VERSION ""

NS_ :

BS_:

BU_: IVT_Mod ECU Inverters

VAL_TABLE_ _B9_Voltage_Channels 3 "3 Channels" 0 "0 Channels" ;
VAL_TABLE_ _B9_Supply_Voltage 1 "12 / 24 V nominal supply voltage" ;
VAL_TABLE_ _B9_Current 2500 "2500 A" 1000 "1000 A" 500 "500 A" 300 "300 A" 100 "100 A" ;
VAL_TABLE_ _B9_Device_Type 2 "IVT-S" 1 "IVT-Mod" ;
VAL_TABLE_ VtDevice_Com 2 "CAN 2 - not terminated" 1 "CAN 1 - terminated" 0 "none" ;
VAL_TABLE_ VtDevice_TOI 3 "I" ;
VAL_TABLE_ VtResetErrorLogdata 7 "Reset error current implausible" 6 "Reset error Vref" 5 "Reset error Underflow ADC ch2" 4 "Reset error Overflow ADC ch2" 3 "Reset error Underflow ADC ch1" 2 "Reset error Overflow ADC ch1" 1 "Reset error ADC interrupt" 0 "Reset all measurement errors" ;
VAL_TABLE_ VtID_Result 0 "Vt_Result_inaktive" 8 "Vt_Result_Wh" 7 "Vt_Result_Ah" 6 "Vt_Result_W" 5 "Vt_Result_T" 4 "Vt_Result_U3" 3 "Vt_Result_U2" 2 "Vt_Result_U1" 1 "Vt_Result_I" ;
VAL_TABLE_ VtID_Cmd 54 "Set_THRESHOLD_neg" 53 "Set_THRESHOLD_pos" 32 "Set_MODE_Result_I" 16 "Set_CAN_ID_Result_I" 52 "Set_MODE" 51 "START_OC_TEST" 50 "STORE" 49 "TRIGGER" 48 "Reset_Err_Log" 39 "Set_MODE_Result_Wh" 38 "Set_MODE_Result_Ah" 37 "Set_MODE_Result_W" 23 "Set_CAN_ID_Result_Wh" 22 "Set_CAN_ID_Result_Ah" 21 "Set_CAN_ID_Result_W" 20 "Set_CAN_ID_Result_T" 35 "Set_MODE_Result_U3" 31 "Set_CAN_ID_Cmd" 29 "Set_CAN_ID_Response" 19 "Set_CAN_ID_Result_U3" 18 "Set_CAN_ID_Result_U2" 36 "Set_MODE_Result_T" 34 "Set_MODE_Result_U2" 33 "Set_MODE_Result_U1" 17 "Set_CAN_ID_Result_U1" ;
VAL_TABLE_ VtTriggerMode 2 "CYCLIC" 1 "TRIGGERED" 0 "DISABLED" ;
VAL_TABLE_ VtRunMode 1 "START" 0 "STOP" ;
VAL_TABLE_ VtID_Response 149 "ARTICLE_NUMBER" 148 "SERIAL NUMBER" 147 "SW_VERSION" 146 "DEVICE_ID" 145 "STATUS" 143 "CAN_ID" 142 "STORE_to_default" 134 "START_OC_TEST" 133 "Description for the value '0x85'" 132 "THRESHOLD" 131 "CONFIG" 130 "MODE" 129 "STORE" 128 "TRIGGER" ;

BO_ 3221225472 VECTOR__INDEPENDENT_SIG_MSG: 0 Vector__XXX
 SG_ _B1_Resp_Trigger_Mask : 0|16@0+ (1,0) [0|0] "" Vector__XXX
 SG_ _B9_Resp_Device_spare : 0|8@0+ (1,0) [0|0] "" Vector__XXX

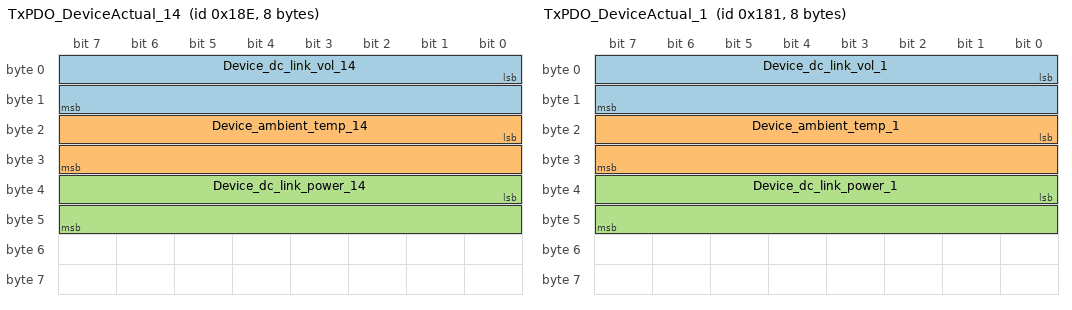
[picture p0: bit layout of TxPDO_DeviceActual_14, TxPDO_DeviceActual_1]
BO_ 398 TxPDO_DeviceActual_14: 8 Inverters
 SG_ Device_dc_link_vol_14 : 0|16@1- (0.0625,0) [-2048|2047.9375] "V" Vector__XXX
 SG_ Device_ambient_temp_14 : 16|16@1- (0.0625,0) [-2048|2047.9375] "°C" Vector__XXX
 SG_ Device_dc_link_power_14 : 32|16@1- (0.016,0) [-524.288|524.272] "kW" Vector__XXX

BO_ 385 TxPDO_DeviceActual_1: 8 Inverters
 SG_ Device_dc_link_vol_1 : 0|16@1- (0.0625,0) [-2048|2047.9375] "V" Vector__XXX
 SG_ Device_ambient_temp_1 : 16|16@1- (0.0625,0) [-2048|2047.9375] "°C" Vector__XXX
 SG_ Device_dc_link_power_1 : 32|16@1- (0.016,0) [-524.288|524.272] "kW" Vector__XXX

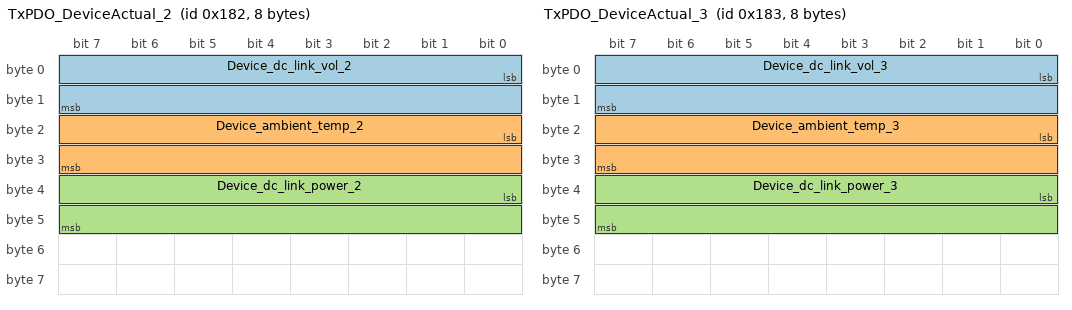
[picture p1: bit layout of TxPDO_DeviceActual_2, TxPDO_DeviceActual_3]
BO_ 386 TxPDO_DeviceActual_2: 8 Inverters
 SG_ Device_dc_link_vol_2 : 0|16@1- (0.0625,0) [-2048|2047.9375] "V" Vector__XXX
 SG_ Device_ambient_temp_2 : 16|16@1- (0.0625,0) [-2048|2047.9375] "°C" Vector__XXX
 SG_ Device_dc_link_power_2 : 32|16@1- (0.016,0) [-524.288|524.272] "kW" Vector__XXX

BO_ 387 TxPDO_DeviceActual_3: 8 Inverters
 SG_ Device_dc_link_vol_3 : 0|16@1- (0.0625,0) [-2048|2047.9375] "V" Vector__XXX
 SG_ Device_ambient_temp_3 : 16|16@1- (0.0625,0) [-2048|2047.9375] "°C" Vector__XXX
 SG_ Device_dc_link_power_3 : 32|16@1- (0.016,0) [-524.288|524.272] "kW" Vector__XXX

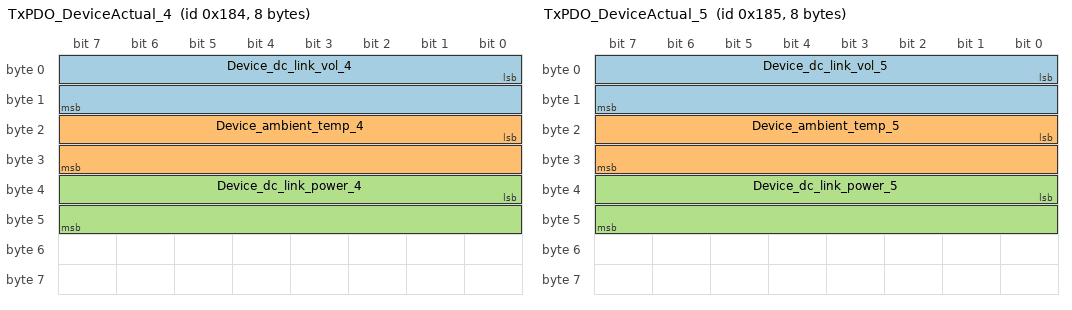
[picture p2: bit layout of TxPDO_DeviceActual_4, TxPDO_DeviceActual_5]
BO_ 388 TxPDO_DeviceActual_4: 8 Inverters
 SG_ Device_dc_link_vol_4 : 0|16@1- (0.0625,0) [-2048|2047.9375] "V" Vector__XXX
 SG_ Device_ambient_temp_4 : 16|16@1- (0.0625,0) [-2048|2047.9375] "°C" Vector__XXX
 SG_ Device_dc_link_power_4 : 32|16@1- (0.016,0) [-524.288|524.272] "kW" Vector__XXX

BO_ 389 TxPDO_DeviceActual_5: 8 Inverters
 SG_ Device_dc_link_vol_5 : 0|16@1- (0.0625,0) [-2048|2047.9375] "V" Vector__XXX
 SG_ Device_ambient_temp_5 : 16|16@1- (0.0625,0) [-2048|2047.9375] "°C" Vector__XXX
 SG_ Device_dc_link_power_5 : 32|16@1- (0.016,0) [-524.288|524.272] "kW" Vector__XXX

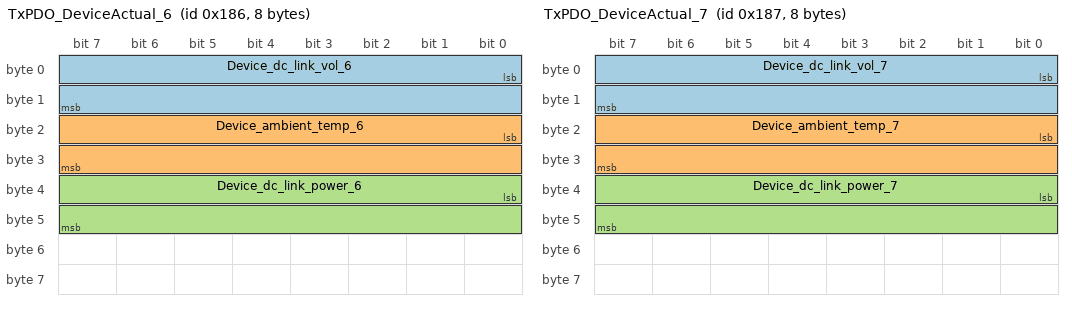
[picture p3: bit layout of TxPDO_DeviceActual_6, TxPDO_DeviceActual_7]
BO_ 390 TxPDO_DeviceActual_6: 8 Inverters
 SG_ Device_dc_link_vol_6 : 0|16@1- (0.0625,0) [-2048|2047.9375] "V" Vector__XXX
 SG_ Device_ambient_temp_6 : 16|16@1- (0.0625,0) [-2048|2047.9375] "°C" Vector__XXX
 SG_ Device_dc_link_power_6 : 32|16@1- (0.016,0) [-524.288|524.272] "kW" Vector__XXX

BO_ 391 TxPDO_DeviceActual_7: 8 Inverters
 SG_ Device_dc_link_vol_7 : 0|16@1- (0.0625,0) [-2048|2047.9375] "V" Vector__XXX
 SG_ Device_ambient_temp_7 : 16|16@1- (0.0625,0) [-2048|2047.9375] "°C" Vector__XXX
 SG_ Device_dc_link_power_7 : 32|16@1- (0.016,0) [-524.288|524.272] "kW" Vector__XXX

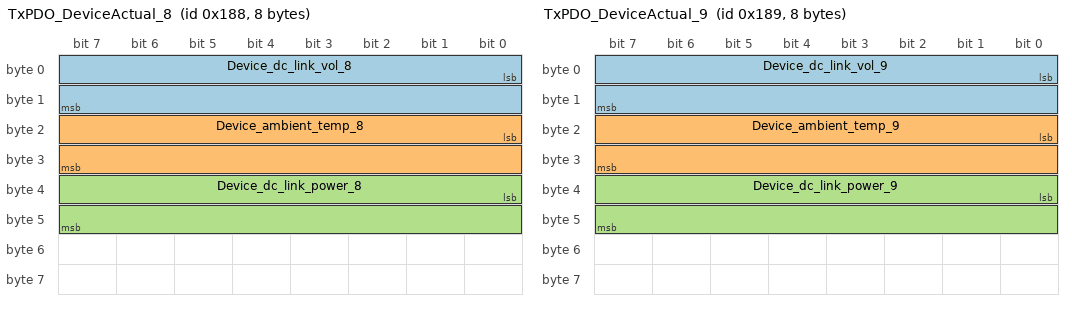
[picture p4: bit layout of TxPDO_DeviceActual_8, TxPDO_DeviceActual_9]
BO_ 392 TxPDO_DeviceActual_8: 8 Inverters
 SG_ Device_dc_link_vol_8 : 0|16@1- (0.0625,0) [-2048|2047.9375] "V" Vector__XXX
 SG_ Device_ambient_temp_8 : 16|16@1- (0.0625,0) [-2048|2047.9375] "°C" Vector__XXX
 SG_ Device_dc_link_power_8 : 32|16@1- (0.016,0) [-524.288|524.272] "kW" Vector__XXX

BO_ 393 TxPDO_DeviceActual_9: 8 Inverters
 SG_ Device_dc_link_vol_9 : 0|16@1- (0.0625,0) [-2048|2047.9375] "V" Vector__XXX
 SG_ Device_ambient_temp_9 : 16|16@1- (0.0625,0) [-2048|2047.9375] "°C" Vector__XXX
 SG_ Device_dc_link_power_9 : 32|16@1- (0.016,0) [-524.288|524.272] "kW" Vector__XXX

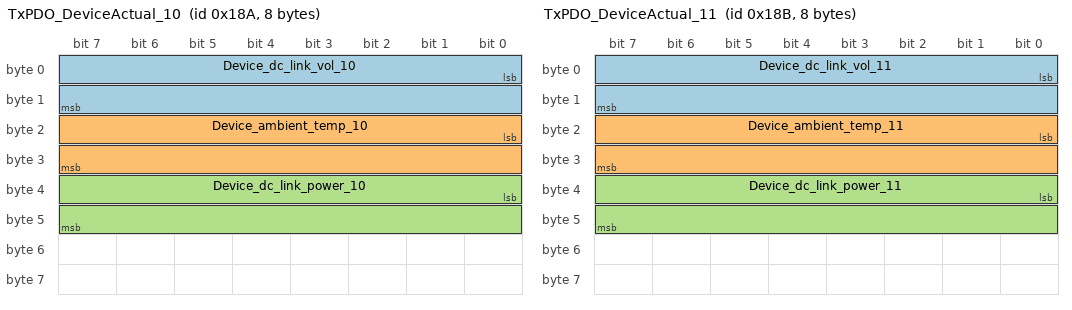
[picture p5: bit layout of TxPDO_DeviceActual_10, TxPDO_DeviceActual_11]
BO_ 394 TxPDO_DeviceActual_10: 8 Inverters
 SG_ Device_dc_link_vol_10 : 0|16@1- (0.0625,0) [-2048|2047.9375] "V" Vector__XXX
 SG_ Device_ambient_temp_10 : 16|16@1- (0.0625,0) [-2048|2047.9375] "°C" Vector__XXX
 SG_ Device_dc_link_power_10 : 32|16@1- (0.016,0) [-524.288|524.272] "kW" Vector__XXX

BO_ 395 TxPDO_DeviceActual_11: 8 Inverters
 SG_ Device_dc_link_vol_11 : 0|16@1- (0.0625,0) [-2048|2047.9375] "V" Vector__XXX
 SG_ Device_ambient_temp_11 : 16|16@1- (0.0625,0) [-2048|2047.9375] "°C" Vector__XXX
 SG_ Device_dc_link_power_11 : 32|16@1- (0.016,0) [-524.288|524.272] "kW" Vector__XXX

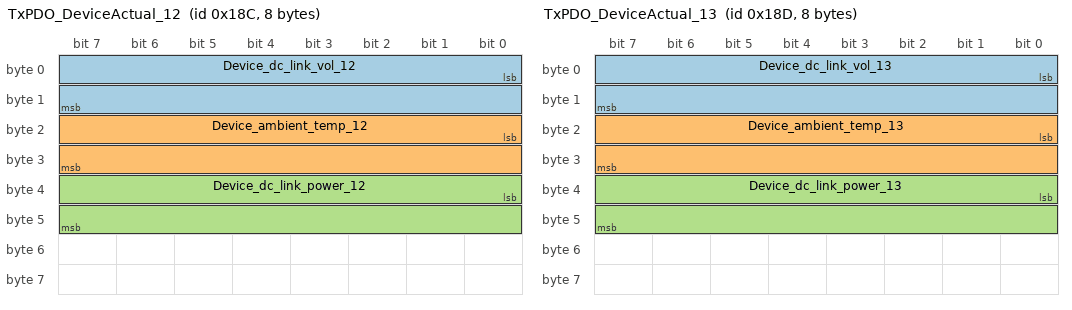
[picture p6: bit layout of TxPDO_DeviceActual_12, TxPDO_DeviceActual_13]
BO_ 396 TxPDO_DeviceActual_12: 8 Inverters
 SG_ Device_dc_link_vol_12 : 0|16@1- (0.0625,0) [-2048|2047.9375] "V" Vector__XXX
 SG_ Device_ambient_temp_12 : 16|16@1- (0.0625,0) [-2048|2047.9375] "°C" Vector__XXX
 SG_ Device_dc_link_power_12 : 32|16@1- (0.016,0) [-524.288|524.272] "kW" Vector__XXX

BO_ 397 TxPDO_DeviceActual_13: 8 Inverters
 SG_ Device_dc_link_vol_13 : 0|16@1- (0.0625,0) [-2048|2047.9375] "V" Vector__XXX
 SG_ Device_ambient_temp_13 : 16|16@1- (0.0625,0) [-2048|2047.9375] "°C" Vector__XXX
 SG_ Device_dc_link_power_13 : 32|16@1- (0.016,0) [-524.288|524.272] "kW" Vector__XXX

BO_ 462 TxPDO_InverterAStatus_14: 8 Inverters
 SG_ Inverter_A_Statusword_14 : 0|7@1+ (1,0) [0|127] "" Vector__XXX
 SG_ EVENTBUFFER_NEW_EVENT : 16|1@1+ (1,0) [0|1] "" Vector__XXX
 SG_ EVENTBUFFER_OVERFLOW : 17|1@1+ (1,0) [0|1] "" Vector__XXX
 SG_ POWERMODULE_TRIPZONE_OVERCURRE : 18|1@1+ (1,0) [0|1] "" Vector__XXX
 SG_ POWERMODULE_CURRENT_OFFSET_INI : 19|1@1+ (1,0) [0|1] "" Vector__XXX
 SG_ POWERMODULE_TEMPSENSOR_ERROR : 20|1@1+ (1,0) [0|1] "" Vector__XXX
 SG_ POWERMODULE_TEMPERATURE_WARNIN : 21|1@1+ (1,0) [0|1] "" Vector__XXX
 SG_ POWERMODULE_OVERTEMPERATURE : 22|1@1+ (1,0) [0|1] "" Vector__XXX
 SG_ POWERMODULE_IXT_FAULT : 23|1@1+ (1,0) [0|1] "" Vector__XXX
 SG_ POWERMODULE_SW_OVERCURRENT : 24|1@1+ (1,0) [0|1] "" Vector__XXX
 SG_ POWERMODULE_PATTERNDATA_INCONS : 25|1@1+ (1,0) [0|1] "" Vector__XXX
 SG_ DCBUS_TRIPZONE_OVERVOLTAGE : 26|1@1+ (1,0) [0|1] "" Vector__XXX
 SG_ DCBUS_SW_OVERVOLTAGE : 27|1@1+ (1,0) [0|1] "" Vector__XXX
 SG_ DCBUS_SW_UNDERVOLTAGE : 28|1@1+ (1,0) [0|1] "" Vector__XXX
 SG_ NEIGHBOUR_FAULT : 29|1@1+ (1,0) [0|1] "" Vector__XXX
 SG_ MOTOR_TEMPSENSOR_ERROR : 30|1@1+ (1,0) [0|1] "" Vector__XXX
 SG_ MOTOR_TEMPERATURE_WARNING : 31|1@1+ (1,0) [0|1] "" Vector__XXX
 SG_ MOTOR_OVERTEMPERATURE : 32|1@1+ (1,0) [0|1] "" Vector__XXX
 SG_ MOTOR_STATOR_FREQ_TO_HIGH : 33|1@1+ (1,0) [0|1] "" Vector__XXX
 SG_ SUPPLYVOLTAGE_ERROR : 34|1@1+ (1,0) [0|1] "" Vector__XXX
 SG_ RPDO_TIMEOUT : 35|1@1+ (1,0) [0|1] "" Vector__XXX
 SG_ NMT_NOT_OPERATIONAL : 36|1@1+ (1,0) [0|1] "" Vector__XXX
 SG_ TASKOVERRUN : 37|1@1+ (1,0) [0|1] "" Vector__XXX
 SG_ NETSYNC_ERROR : 38|1@1+ (1,0) [0|1] "" Vector__XXX
 SG_ POSDEVICE_SIGNAL_TO_LOW : 39|1@1+ (1,0) [0|1] "" Vector__XXX
 SG_ POSDEVICE_SIGNAL_TO_HIGH : 40|1@1+ (1,0) [0|1] "" Vector__XXX
 SG_ RESOLVER_CALIBRATION_FAILED : 41|1@1+ (1,0) [0|1] "" Vector__XXX
 SG_ SYSTEM_FAULT : 42|1@1+ (1,0) [0|1] "" Vector__XXX
 SG_ INTERLOCK_OPEN : 43|1@1+ (1,0) [0|1] "" Vector__XXX
 SG_ APPC_HAS_GATE_DRIVER_DISABLED : 44|1@1+ (1,0) [0|1] "" Vector__XXX
 SG_ MOTOR_STALL_ERROR : 45|1@1+ (1,0) [0|1] "" Vector__XXX
 SG_ AMBIENT_TEMPERATURE_WARNING : 46|1@1+ (1,0) [0|1] "" Vector__XXX
 SG_ AMBIENT_OVERTEMPERATURE : 47|1@1+ (1,0) [0|1] "" Vector__XXX
 SG_ AMBIENT_TEMPSENSOR_ERROR : 48|1@1+ (1,0) [0|1] "" Vector__XXX
 SG_ POWERMODULE_CLAMPING_TIMEOUT : 49|1@1+ (1,0) [0|1] "" Vector__XXX
 SG_ DCBUS_RIPPLE_TO_HIGH : 50|1@1+ (1,0) [0|1] "" Vector__XXX
 SG_ MOTOR_I2XT_WARNING : 51|1@1+ (1,0) [0|1] "" Vector__XXX
 SG_ MOTOR_I2XT_ERROR : 52|1@1+ (1,0) [0|1] "" Vector__XXX
 SG_ MOTOR_FIELDWEAKENING_ERROR : 53|1@1+ (1,0) [0|1] "" Vector__XXX
 SG_ INVALID_PARAMETER_COMBINATION : 54|1@1+ (1,0) [0|1] "" Vector__XXX
 SG_ PLUG_COVER_SENSOR_SIGNAL_LOW : 55|1@1+ (1,0) [0|1] "" Vector__XXX
 SG_ MOTOR_CONNECTION_TEST_FAILED : 56|1@1+ (1,0) [0|1] "" Vector__XXX
 SG_ POWERMODULE_IXT_WARNING : 57|1@1+ (1,0) [0|1] "" Vector__XXX
 SG_ ISOLATION_FAULT : 58|1@1+ (1,0) [0|1] "" Vector__XXX

BO_ 449 TxPDO_InverterAStatus_1: 8 Inverters
 SG_ Inverter_A_Statusword_1 : 0|7@1+ (1,0) [0|127] "" Vector__XXX
 SG_ EVENTBUFFER_NEW_EVENT : 16|1@1+ (1,0) [0|1] "" Vector__XXX
 SG_ EVENTBUFFER_OVERFLOW : 17|1@1+ (1,0) [0|1] "" Vector__XXX
 SG_ POWERMODULE_TRIPZONE_OVERCURRE : 18|1@1+ (1,0) [0|1] "" Vector__XXX
 SG_ POWERMODULE_CURRENT_OFFSET_INI : 19|1@1+ (1,0) [0|1] "" Vector__XXX
 SG_ POWERMODULE_TEMPSENSOR_ERROR : 20|1@1+ (1,0) [0|1] "" Vector__XXX
 SG_ POWERMODULE_TEMPERATURE_WARNIN : 21|1@1+ (1,0) [0|1] "" Vector__XXX
 SG_ POWERMODULE_OVERTEMPERATURE : 22|1@1+ (1,0) [0|1] "" Vector__XXX
 SG_ POWERMODULE_IXT_FAULT : 23|1@1+ (1,0) [0|1] "" Vector__XXX
 SG_ POWERMODULE_SW_OVERCURRENT : 24|1@1+ (1,0) [0|1] "" Vector__XXX
 SG_ POWERMODULE_PATTERNDATA_INCONS : 25|1@1+ (1,0) [0|1] "" Vector__XXX
 SG_ DCBUS_TRIPZONE_OVERVOLTAGE : 26|1@1+ (1,0) [0|1] "" Vector__XXX
 SG_ DCBUS_SW_OVERVOLTAGE : 27|1@1+ (1,0) [0|1] "" Vector__XXX
 SG_ DCBUS_SW_UNDERVOLTAGE : 28|1@1+ (1,0) [0|1] "" Vector__XXX
 SG_ NEIGHBOUR_FAULT : 29|1@1+ (1,0) [0|1] "" Vector__XXX
 SG_ MOTOR_TEMPSENSOR_ERROR : 30|1@1+ (1,0) [0|1] "" Vector__XXX
 SG_ MOTOR_TEMPERATURE_WARNING : 31|1@1+ (1,0) [0|1] "" Vector__XXX
 SG_ MOTOR_OVERTEMPERATURE : 32|1@1+ (1,0) [0|1] "" Vector__XXX
 SG_ MOTOR_STATOR_FREQ_TO_HIGH : 33|1@1+ (1,0) [0|1] "" Vector__XXX
 SG_ SUPPLYVOLTAGE_ERROR : 34|1@1+ (1,0) [0|1] "" Vector__XXX
 SG_ RPDO_TIMEOUT : 35|1@1+ (1,0) [0|1] "" Vector__XXX
 SG_ NMT_NOT_OPERATIONAL : 36|1@1+ (1,0) [0|1] "" Vector__XXX
 SG_ TASKOVERRUN : 37|1@1+ (1,0) [0|1] "" Vector__XXX
 SG_ NETSYNC_ERROR : 38|1@1+ (1,0) [0|1] "" Vector__XXX
 SG_ POSDEVICE_SIGNAL_TO_LOW : 39|1@1+ (1,0) [0|1] "" Vector__XXX
 SG_ POSDEVICE_SIGNAL_TO_HIGH : 40|1@1+ (1,0) [0|1] "" Vector__XXX
 SG_ RESOLVER_CALIBRATION_FAILED : 41|1@1+ (1,0) [0|1] "" Vector__XXX
 SG_ SYSTEM_FAULT : 42|1@1+ (1,0) [0|1] "" Vector__XXX
 SG_ INTERLOCK_OPEN : 43|1@1+ (1,0) [0|1] "" Vector__XXX
 SG_ APPC_HAS_GATE_DRIVER_DISABLED : 44|1@1+ (1,0) [0|1] "" Vector__XXX
 SG_ MOTOR_STALL_ERROR : 45|1@1+ (1,0) [0|1] "" Vector__XXX
 SG_ AMBIENT_TEMPERATURE_WARNING : 46|1@1+ (1,0) [0|1] "" Vector__XXX
 SG_ AMBIENT_OVERTEMPERATURE : 47|1@1+ (1,0) [0|1] "" Vector__XXX
 SG_ AMBIENT_TEMPSENSOR_ERROR : 48|1@1+ (1,0) [0|1] "" Vector__XXX
 SG_ POWERMODULE_CLAMPING_TIMEOUT : 49|1@1+ (1,0) [0|1] "" Vector__XXX
 SG_ DCBUS_RIPPLE_TO_HIGH : 50|1@1+ (1,0) [0|1] "" Vector__XXX
 SG_ MOTOR_I2XT_WARNING : 51|1@1+ (1,0) [0|1] "" Vector__XXX
 SG_ MOTOR_I2XT_ERROR : 52|1@1+ (1,0) [0|1] "" Vector__XXX
 SG_ MOTOR_FIELDWEAKENING_ERROR : 53|1@1+ (1,0) [0|1] "" Vector__XXX
 SG_ INVALID_PARAMETER_COMBINATION : 54|1@1+ (1,0) [0|1] "" Vector__XXX
 SG_ PLUG_COVER_SENSOR_SIGNAL_LOW : 55|1@1+ (1,0) [0|1] "" Vector__XXX
 SG_ MOTOR_CONNECTION_TEST_FAILED : 56|1@1+ (1,0) [0|1] "" Vector__XXX
 SG_ POWERMODULE_IXT_WARNING : 57|1@1+ (1,0) [0|1] "" Vector__XXX
 SG_ ISOLATION_FAULT : 58|1@1+ (1,0) [0|1] "" Vector__XXX

BO_ 450 TxPDO_InverterAStatus_2: 8 Inverters
 SG_ Inverter_A_Statusword_2 : 0|7@1+ (1,0) [0|127] "" Vector__XXX
 SG_ EVENTBUFFER_NEW_EVENT : 16|1@1+ (1,0) [0|1] "" Vector__XXX
 SG_ EVENTBUFFER_OVERFLOW : 17|1@1+ (1,0) [0|1] "" Vector__XXX
 SG_ POWERMODULE_TRIPZONE_OVERCURRE : 18|1@1+ (1,0) [0|1] "" Vector__XXX
 SG_ POWERMODULE_CURRENT_OFFSET_INI : 19|1@1+ (1,0) [0|1] "" Vector__XXX
 SG_ POWERMODULE_TEMPSENSOR_ERROR : 20|1@1+ (1,0) [0|1] "" Vector__XXX
 SG_ POWERMODULE_TEMPERATURE_WARNIN : 21|1@1+ (1,0) [0|1] "" Vector__XXX
 SG_ POWERMODULE_OVERTEMPERATURE : 22|1@1+ (1,0) [0|1] "" Vector__XXX
 SG_ POWERMODULE_IXT_FAULT : 23|1@1+ (1,0) [0|1] "" Vector__XXX
 SG_ POWERMODULE_SW_OVERCURRENT : 24|1@1+ (1,0) [0|1] "" Vector__XXX
 SG_ POWERMODULE_PATTERNDATA_INCONS : 25|1@1+ (1,0) [0|1] "" Vector__XXX
 SG_ DCBUS_TRIPZONE_OVERVOLTAGE : 26|1@1+ (1,0) [0|1] "" Vector__XXX
 SG_ DCBUS_SW_OVERVOLTAGE : 27|1@1+ (1,0) [0|1] "" Vector__XXX
 SG_ DCBUS_SW_UNDERVOLTAGE : 28|1@1+ (1,0) [0|1] "" Vector__XXX
 SG_ NEIGHBOUR_FAULT : 29|1@1+ (1,0) [0|1] "" Vector__XXX
 SG_ MOTOR_TEMPSENSOR_ERROR : 30|1@1+ (1,0) [0|1] "" Vector__XXX
 SG_ MOTOR_TEMPERATURE_WARNING : 31|1@1+ (1,0) [0|1] "" Vector__XXX
 SG_ MOTOR_OVERTEMPERATURE : 32|1@1+ (1,0) [0|1] "" Vector__XXX
 SG_ MOTOR_STATOR_FREQ_TO_HIGH : 33|1@1+ (1,0) [0|1] "" Vector__XXX
 SG_ SUPPLYVOLTAGE_ERROR : 34|1@1+ (1,0) [0|1] "" Vector__XXX
 SG_ RPDO_TIMEOUT : 35|1@1+ (1,0) [0|1] "" Vector__XXX
 SG_ NMT_NOT_OPERATIONAL : 36|1@1+ (1,0) [0|1] "" Vector__XXX
 SG_ TASKOVERRUN : 37|1@1+ (1,0) [0|1] "" Vector__XXX
 SG_ NETSYNC_ERROR : 38|1@1+ (1,0) [0|1] "" Vector__XXX
 SG_ POSDEVICE_SIGNAL_TO_LOW : 39|1@1+ (1,0) [0|1] "" Vector__XXX
 SG_ POSDEVICE_SIGNAL_TO_HIGH : 40|1@1+ (1,0) [0|1] "" Vector__XXX
 SG_ RESOLVER_CALIBRATION_FAILED : 41|1@1+ (1,0) [0|1] "" Vector__XXX
 SG_ SYSTEM_FAULT : 42|1@1+ (1,0) [0|1] "" Vector__XXX
 SG_ INTERLOCK_OPEN : 43|1@1+ (1,0) [0|1] "" Vector__XXX
 SG_ APPC_HAS_GATE_DRIVER_DISABLED : 44|1@1+ (1,0) [0|1] "" Vector__XXX
 SG_ MOTOR_STALL_ERROR : 45|1@1+ (1,0) [0|1] "" Vector__XXX
 SG_ AMBIENT_TEMPERATURE_WARNING : 46|1@1+ (1,0) [0|1] "" Vector__XXX
 SG_ AMBIENT_OVERTEMPERATURE : 47|1@1+ (1,0) [0|1] "" Vector__XXX
 SG_ AMBIENT_TEMPSENSOR_ERROR : 48|1@1+ (1,0) [0|1] "" Vector__XXX
 SG_ POWERMODULE_CLAMPING_TIMEOUT : 49|1@1+ (1,0) [0|1] "" Vector__XXX
 SG_ DCBUS_RIPPLE_TO_HIGH : 50|1@1+ (1,0) [0|1] "" Vector__XXX
 SG_ MOTOR_I2XT_WARNING : 51|1@1+ (1,0) [0|1] "" Vector__XXX
 SG_ MOTOR_I2XT_ERROR : 52|1@1+ (1,0) [0|1] "" Vector__XXX
 SG_ MOTOR_FIELDWEAKENING_ERROR : 53|1@1+ (1,0) [0|1] "" Vector__XXX
 SG_ INVALID_PARAMETER_COMBINATION : 54|1@1+ (1,0) [0|1] "" Vector__XXX
 SG_ PLUG_COVER_SENSOR_SIGNAL_LOW : 55|1@1+ (1,0) [0|1] "" Vector__XXX
 SG_ MOTOR_CONNECTION_TEST_FAILED : 56|1@1+ (1,0) [0|1] "" Vector__XXX
 SG_ POWERMODULE_IXT_WARNING : 57|1@1+ (1,0) [0|1] "" Vector__XXX
 SG_ ISOLATION_FAULT : 58|1@1+ (1,0) [0|1] "" Vector__XXX

BO_ 451 TxPDO_InverterAStatus_3: 8 Inverters
 SG_ Inverter_A_Statusword_3 : 0|7@1+ (1,0) [0|127] "" Vector__XXX
 SG_ EVENTBUFFER_NEW_EVENT : 16|1@1+ (1,0) [0|1] "" Vector__XXX
 SG_ EVENTBUFFER_OVERFLOW : 17|1@1+ (1,0) [0|1] "" Vector__XXX
 SG_ POWERMODULE_TRIPZONE_OVERCURRE : 18|1@1+ (1,0) [0|1] "" Vector__XXX
 SG_ POWERMODULE_CURRENT_OFFSET_INI : 19|1@1+ (1,0) [0|1] "" Vector__XXX
 SG_ POWERMODULE_TEMPSENSOR_ERROR : 20|1@1+ (1,0) [0|1] "" Vector__XXX
 SG_ POWERMODULE_TEMPERATURE_WARNIN : 21|1@1+ (1,0) [0|1] "" Vector__XXX
 SG_ POWERMODULE_OVERTEMPERATURE : 22|1@1+ (1,0) [0|1] "" Vector__XXX
 SG_ POWERMODULE_IXT_FAULT : 23|1@1+ (1,0) [0|1] "" Vector__XXX
 SG_ POWERMODULE_SW_OVERCURRENT : 24|1@1+ (1,0) [0|1] "" Vector__XXX
 SG_ POWERMODULE_PATTERNDATA_INCONS : 25|1@1+ (1,0) [0|1] "" Vector__XXX
 SG_ DCBUS_TRIPZONE_OVERVOLTAGE : 26|1@1+ (1,0) [0|1] "" Vector__XXX
 SG_ DCBUS_SW_OVERVOLTAGE : 27|1@1+ (1,0) [0|1] "" Vector__XXX
 SG_ DCBUS_SW_UNDERVOLTAGE : 28|1@1+ (1,0) [0|1] "" Vector__XXX
 SG_ NEIGHBOUR_FAULT : 29|1@1+ (1,0) [0|1] "" Vector__XXX
 SG_ MOTOR_TEMPSENSOR_ERROR : 30|1@1+ (1,0) [0|1] "" Vector__XXX
 SG_ MOTOR_TEMPERATURE_WARNING : 31|1@1+ (1,0) [0|1] "" Vector__XXX
 SG_ MOTOR_OVERTEMPERATURE : 32|1@1+ (1,0) [0|1] "" Vector__XXX
 SG_ MOTOR_STATOR_FREQ_TO_HIGH : 33|1@1+ (1,0) [0|1] "" Vector__XXX
 SG_ SUPPLYVOLTAGE_ERROR : 34|1@1+ (1,0) [0|1] "" Vector__XXX
 SG_ RPDO_TIMEOUT : 35|1@1+ (1,0) [0|1] "" Vector__XXX
 SG_ NMT_NOT_OPERATIONAL : 36|1@1+ (1,0) [0|1] "" Vector__XXX
 SG_ TASKOVERRUN : 37|1@1+ (1,0) [0|1] "" Vector__XXX
 SG_ NETSYNC_ERROR : 38|1@1+ (1,0) [0|1] "" Vector__XXX
 SG_ POSDEVICE_SIGNAL_TO_LOW : 39|1@1+ (1,0) [0|1] "" Vector__XXX
 SG_ POSDEVICE_SIGNAL_TO_HIGH : 40|1@1+ (1,0) [0|1] "" Vector__XXX
 SG_ RESOLVER_CALIBRATION_FAILED : 41|1@1+ (1,0) [0|1] "" Vector__XXX
 SG_ SYSTEM_FAULT : 42|1@1+ (1,0) [0|1] "" Vector__XXX
 SG_ INTERLOCK_OPEN : 43|1@1+ (1,0) [0|1] "" Vector__XXX
 SG_ APPC_HAS_GATE_DRIVER_DISABLED : 44|1@1+ (1,0) [0|1] "" Vector__XXX
 SG_ MOTOR_STALL_ERROR : 45|1@1+ (1,0) [0|1] "" Vector__XXX
 SG_ AMBIENT_TEMPERATURE_WARNING : 46|1@1+ (1,0) [0|1] "" Vector__XXX
 SG_ AMBIENT_OVERTEMPERATURE : 47|1@1+ (1,0) [0|1] "" Vector__XXX
 SG_ AMBIENT_TEMPSENSOR_ERROR : 48|1@1+ (1,0) [0|1] "" Vector__XXX
 SG_ POWERMODULE_CLAMPING_TIMEOUT : 49|1@1+ (1,0) [0|1] "" Vector__XXX
 SG_ DCBUS_RIPPLE_TO_HIGH : 50|1@1+ (1,0) [0|1] "" Vector__XXX
 SG_ MOTOR_I2XT_WARNING : 51|1@1+ (1,0) [0|1] "" Vector__XXX
 SG_ MOTOR_I2XT_ERROR : 52|1@1+ (1,0) [0|1] "" Vector__XXX
 SG_ MOTOR_FIELDWEAKENING_ERROR : 53|1@1+ (1,0) [0|1] "" Vector__XXX
 SG_ INVALID_PARAMETER_COMBINATION : 54|1@1+ (1,0) [0|1] "" Vector__XXX
 SG_ PLUG_COVER_SENSOR_SIGNAL_LOW : 55|1@1+ (1,0) [0|1] "" Vector__XXX
 SG_ MOTOR_CONNECTION_TEST_FAILED : 56|1@1+ (1,0) [0|1] "" Vector__XXX
 SG_ POWERMODULE_IXT_WARNING : 57|1@1+ (1,0) [0|1] "" Vector__XXX
 SG_ ISOLATION_FAULT : 58|1@1+ (1,0) [0|1] "" Vector__XXX

BO_ 452 TxPDO_InverterAStatus_4: 8 Inverters
 SG_ Inverter_A_Statusword_4 : 0|7@1+ (1,0) [0|127] "" Vector__XXX
 SG_ EVENTBUFFER_NEW_EVENT : 16|1@1+ (1,0) [0|1] "" Vector__XXX
 SG_ EVENTBUFFER_OVERFLOW : 17|1@1+ (1,0) [0|1] "" Vector__XXX
 SG_ POWERMODULE_TRIPZONE_OVERCURRE : 18|1@1+ (1,0) [0|1] "" Vector__XXX
 SG_ POWERMODULE_CURRENT_OFFSET_INI : 19|1@1+ (1,0) [0|1] "" Vector__XXX
 SG_ POWERMODULE_TEMPSENSOR_ERROR : 20|1@1+ (1,0) [0|1] "" Vector__XXX
 SG_ POWERMODULE_TEMPERATURE_WARNIN : 21|1@1+ (1,0) [0|1] "" Vector__XXX
 SG_ POWERMODULE_OVERTEMPERATURE : 22|1@1+ (1,0) [0|1] "" Vector__XXX
 SG_ POWERMODULE_IXT_FAULT : 23|1@1+ (1,0) [0|1] "" Vector__XXX
 SG_ POWERMODULE_SW_OVERCURRENT : 24|1@1+ (1,0) [0|1] "" Vector__XXX
 SG_ POWERMODULE_PATTERNDATA_INCONS : 25|1@1+ (1,0) [0|1] "" Vector__XXX
 SG_ DCBUS_TRIPZONE_OVERVOLTAGE : 26|1@1+ (1,0) [0|1] "" Vector__XXX
 SG_ DCBUS_SW_OVERVOLTAGE : 27|1@1+ (1,0) [0|1] "" Vector__XXX
 SG_ DCBUS_SW_UNDERVOLTAGE : 28|1@1+ (1,0) [0|1] "" Vector__XXX
 SG_ NEIGHBOUR_FAULT : 29|1@1+ (1,0) [0|1] "" Vector__XXX
 SG_ MOTOR_TEMPSENSOR_ERROR : 30|1@1+ (1,0) [0|1] "" Vector__XXX
 SG_ MOTOR_TEMPERATURE_WARNING : 31|1@1+ (1,0) [0|1] "" Vector__XXX
 SG_ MOTOR_OVERTEMPERATURE : 32|1@1+ (1,0) [0|1] "" Vector__XXX
 SG_ MOTOR_STATOR_FREQ_TO_HIGH : 33|1@1+ (1,0) [0|1] "" Vector__XXX
 SG_ SUPPLYVOLTAGE_ERROR : 34|1@1+ (1,0) [0|1] "" Vector__XXX
 SG_ RPDO_TIMEOUT : 35|1@1+ (1,0) [0|1] "" Vector__XXX
 SG_ NMT_NOT_OPERATIONAL : 36|1@1+ (1,0) [0|1] "" Vector__XXX
 SG_ TASKOVERRUN : 37|1@1+ (1,0) [0|1] "" Vector__XXX
 SG_ NETSYNC_ERROR : 38|1@1+ (1,0) [0|1] "" Vector__XXX
 SG_ POSDEVICE_SIGNAL_TO_LOW : 39|1@1+ (1,0) [0|1] "" Vector__XXX
 SG_ POSDEVICE_SIGNAL_TO_HIGH : 40|1@1+ (1,0) [0|1] "" Vector__XXX
 SG_ RESOLVER_CALIBRATION_FAILED : 41|1@1+ (1,0) [0|1] "" Vector__XXX
 SG_ SYSTEM_FAULT : 42|1@1+ (1,0) [0|1] "" Vector__XXX
 SG_ INTERLOCK_OPEN : 43|1@1+ (1,0) [0|1] "" Vector__XXX
 SG_ APPC_HAS_GATE_DRIVER_DISABLED : 44|1@1+ (1,0) [0|1] "" Vector__XXX
 SG_ MOTOR_STALL_ERROR : 45|1@1+ (1,0) [0|1] "" Vector__XXX
 SG_ AMBIENT_TEMPERATURE_WARNING : 46|1@1+ (1,0) [0|1] "" Vector__XXX
 SG_ AMBIENT_OVERTEMPERATURE : 47|1@1+ (1,0) [0|1] "" Vector__XXX
 SG_ AMBIENT_TEMPSENSOR_ERROR : 48|1@1+ (1,0) [0|1] "" Vector__XXX
 SG_ POWERMODULE_CLAMPING_TIMEOUT : 49|1@1+ (1,0) [0|1] "" Vector__XXX
 SG_ DCBUS_RIPPLE_TO_HIGH : 50|1@1+ (1,0) [0|1] "" Vector__XXX
 SG_ MOTOR_I2XT_WARNING : 51|1@1+ (1,0) [0|1] "" Vector__XXX
 SG_ MOTOR_I2XT_ERROR : 52|1@1+ (1,0) [0|1] "" Vector__XXX
 SG_ MOTOR_FIELDWEAKENING_ERROR : 53|1@1+ (1,0) [0|1] "" Vector__XXX
 SG_ INVALID_PARAMETER_COMBINATION : 54|1@1+ (1,0) [0|1] "" Vector__XXX
 SG_ PLUG_COVER_SENSOR_SIGNAL_LOW : 55|1@1+ (1,0) [0|1] "" Vector__XXX
 SG_ MOTOR_CONNECTION_TEST_FAILED : 56|1@1+ (1,0) [0|1] "" Vector__XXX
 SG_ POWERMODULE_IXT_WARNING : 57|1@1+ (1,0) [0|1] "" Vector__XXX
 SG_ ISOLATION_FAULT : 58|1@1+ (1,0) [0|1] "" Vector__XXX

BO_ 453 TxPDO_InverterAStatus_5: 8 Inverters
 SG_ Inverter_A_Statusword_5 : 0|7@1+ (1,0) [0|127] "" Vector__XXX
 SG_ EVENTBUFFER_NEW_EVENT : 16|1@1+ (1,0) [0|1] "" Vector__XXX
 SG_ EVENTBUFFER_OVERFLOW : 17|1@1+ (1,0) [0|1] "" Vector__XXX
 SG_ POWERMODULE_TRIPZONE_OVERCURRE : 18|1@1+ (1,0) [0|1] "" Vector__XXX
 SG_ POWERMODULE_CURRENT_OFFSET_INI : 19|1@1+ (1,0) [0|1] "" Vector__XXX
 SG_ POWERMODULE_TEMPSENSOR_ERROR : 20|1@1+ (1,0) [0|1] "" Vector__XXX
 SG_ POWERMODULE_TEMPERATURE_WARNIN : 21|1@1+ (1,0) [0|1] "" Vector__XXX
 SG_ POWERMODULE_OVERTEMPERATURE : 22|1@1+ (1,0) [0|1] "" Vector__XXX
 SG_ POWERMODULE_IXT_FAULT : 23|1@1+ (1,0) [0|1] "" Vector__XXX
 SG_ POWERMODULE_SW_OVERCURRENT : 24|1@1+ (1,0) [0|1] "" Vector__XXX
 SG_ POWERMODULE_PATTERNDATA_INCONS : 25|1@1+ (1,0) [0|1] "" Vector__XXX
 SG_ DCBUS_TRIPZONE_OVERVOLTAGE : 26|1@1+ (1,0) [0|1] "" Vector__XXX
 SG_ DCBUS_SW_OVERVOLTAGE : 27|1@1+ (1,0) [0|1] "" Vector__XXX
 SG_ DCBUS_SW_UNDERVOLTAGE : 28|1@1+ (1,0) [0|1] "" Vector__XXX
 SG_ NEIGHBOUR_FAULT : 29|1@1+ (1,0) [0|1] "" Vector__XXX
 SG_ MOTOR_TEMPSENSOR_ERROR : 30|1@1+ (1,0) [0|1] "" Vector__XXX
 SG_ MOTOR_TEMPERATURE_WARNING : 31|1@1+ (1,0) [0|1] "" Vector__XXX
 SG_ MOTOR_OVERTEMPERATURE : 32|1@1+ (1,0) [0|1] "" Vector__XXX
 SG_ MOTOR_STATOR_FREQ_TO_HIGH : 33|1@1+ (1,0) [0|1] "" Vector__XXX
 SG_ SUPPLYVOLTAGE_ERROR : 34|1@1+ (1,0) [0|1] "" Vector__XXX
 SG_ RPDO_TIMEOUT : 35|1@1+ (1,0) [0|1] "" Vector__XXX
 SG_ NMT_NOT_OPERATIONAL : 36|1@1+ (1,0) [0|1] "" Vector__XXX
 SG_ TASKOVERRUN : 37|1@1+ (1,0) [0|1] "" Vector__XXX
 SG_ NETSYNC_ERROR : 38|1@1+ (1,0) [0|1] "" Vector__XXX
 SG_ POSDEVICE_SIGNAL_TO_LOW : 39|1@1+ (1,0) [0|1] "" Vector__XXX
 SG_ POSDEVICE_SIGNAL_TO_HIGH : 40|1@1+ (1,0) [0|1] "" Vector__XXX
 SG_ RESOLVER_CALIBRATION_FAILED : 41|1@1+ (1,0) [0|1] "" Vector__XXX
 SG_ SYSTEM_FAULT : 42|1@1+ (1,0) [0|1] "" Vector__XXX
 SG_ INTERLOCK_OPEN : 43|1@1+ (1,0) [0|1] "" Vector__XXX
 SG_ APPC_HAS_GATE_DRIVER_DISABLED : 44|1@1+ (1,0) [0|1] "" Vector__XXX
 SG_ MOTOR_STALL_ERROR : 45|1@1+ (1,0) [0|1] "" Vector__XXX
 SG_ AMBIENT_TEMPERATURE_WARNING : 46|1@1+ (1,0) [0|1] "" Vector__XXX
 SG_ AMBIENT_OVERTEMPERATURE : 47|1@1+ (1,0) [0|1] "" Vector__XXX
 SG_ AMBIENT_TEMPSENSOR_ERROR : 48|1@1+ (1,0) [0|1] "" Vector__XXX
 SG_ POWERMODULE_CLAMPING_TIMEOUT : 49|1@1+ (1,0) [0|1] "" Vector__XXX
 SG_ DCBUS_RIPPLE_TO_HIGH : 50|1@1+ (1,0) [0|1] "" Vector__XXX
 SG_ MOTOR_I2XT_WARNING : 51|1@1+ (1,0) [0|1] "" Vector__XXX
 SG_ MOTOR_I2XT_ERROR : 52|1@1+ (1,0) [0|1] "" Vector__XXX
 SG_ MOTOR_FIELDWEAKENING_ERROR : 53|1@1+ (1,0) [0|1] "" Vector__XXX
 SG_ INVALID_PARAMETER_COMBINATION : 54|1@1+ (1,0) [0|1] "" Vector__XXX
 SG_ PLUG_COVER_SENSOR_SIGNAL_LOW : 55|1@1+ (1,0) [0|1] "" Vector__XXX
 SG_ MOTOR_CONNECTION_TEST_FAILED : 56|1@1+ (1,0) [0|1] "" Vector__XXX
 SG_ POWERMODULE_IXT_WARNING : 57|1@1+ (1,0) [0|1] "" Vector__XXX
 SG_ ISOLATION_FAULT : 58|1@1+ (1,0) [0|1] "" Vector__XXX

BO_ 454 TxPDO_InverterAStatus_6: 8 Inverters
 SG_ Inverter_A_Statusword_6 : 0|7@1+ (1,0) [0|127] "" Vector__XXX
 SG_ EVENTBUFFER_NEW_EVENT : 16|1@1+ (1,0) [0|1] "" Vector__XXX
 SG_ EVENTBUFFER_OVERFLOW : 17|1@1+ (1,0) [0|1] "" Vector__XXX
 SG_ POWERMODULE_TRIPZONE_OVERCURRE : 18|1@1+ (1,0) [0|1] "" Vector__XXX
 SG_ POWERMODULE_CURRENT_OFFSET_INI : 19|1@1+ (1,0) [0|1] "" Vector__XXX
 SG_ POWERMODULE_TEMPSENSOR_ERROR : 20|1@1+ (1,0) [0|1] "" Vector__XXX
 SG_ POWERMODULE_TEMPERATURE_WARNIN : 21|1@1+ (1,0) [0|1] "" Vector__XXX
 SG_ POWERMODULE_OVERTEMPERATURE : 22|1@1+ (1,0) [0|1] "" Vector__XXX
 SG_ POWERMODULE_IXT_FAULT : 23|1@1+ (1,0) [0|1] "" Vector__XXX
 SG_ POWERMODULE_SW_OVERCURRENT : 24|1@1+ (1,0) [0|1] "" Vector__XXX
 SG_ POWERMODULE_PATTERNDATA_INCONS : 25|1@1+ (1,0) [0|1] "" Vector__XXX
 SG_ DCBUS_TRIPZONE_OVERVOLTAGE : 26|1@1+ (1,0) [0|1] "" Vector__XXX
 SG_ DCBUS_SW_OVERVOLTAGE : 27|1@1+ (1,0) [0|1] "" Vector__XXX
 SG_ DCBUS_SW_UNDERVOLTAGE : 28|1@1+ (1,0) [0|1] "" Vector__XXX
 SG_ NEIGHBOUR_FAULT : 29|1@1+ (1,0) [0|1] "" Vector__XXX
 SG_ MOTOR_TEMPSENSOR_ERROR : 30|1@1+ (1,0) [0|1] "" Vector__XXX
 SG_ MOTOR_TEMPERATURE_WARNING : 31|1@1+ (1,0) [0|1] "" Vector__XXX
 SG_ MOTOR_OVERTEMPERATURE : 32|1@1+ (1,0) [0|1] "" Vector__XXX
 SG_ MOTOR_STATOR_FREQ_TO_HIGH : 33|1@1+ (1,0) [0|1] "" Vector__XXX
 SG_ SUPPLYVOLTAGE_ERROR : 34|1@1+ (1,0) [0|1] "" Vector__XXX
 SG_ RPDO_TIMEOUT : 35|1@1+ (1,0) [0|1] "" Vector__XXX
 SG_ NMT_NOT_OPERATIONAL : 36|1@1+ (1,0) [0|1] "" Vector__XXX
 SG_ TASKOVERRUN : 37|1@1+ (1,0) [0|1] "" Vector__XXX
 SG_ NETSYNC_ERROR : 38|1@1+ (1,0) [0|1] "" Vector__XXX
 SG_ POSDEVICE_SIGNAL_TO_LOW : 39|1@1+ (1,0) [0|1] "" Vector__XXX
 SG_ POSDEVICE_SIGNAL_TO_HIGH : 40|1@1+ (1,0) [0|1] "" Vector__XXX
 SG_ RESOLVER_CALIBRATION_FAILED : 41|1@1+ (1,0) [0|1] "" Vector__XXX
 SG_ SYSTEM_FAULT : 42|1@1+ (1,0) [0|1] "" Vector__XXX
 SG_ INTERLOCK_OPEN : 43|1@1+ (1,0) [0|1] "" Vector__XXX
 SG_ APPC_HAS_GATE_DRIVER_DISABLED : 44|1@1+ (1,0) [0|1] "" Vector__XXX
 SG_ MOTOR_STALL_ERROR : 45|1@1+ (1,0) [0|1] "" Vector__XXX
 SG_ AMBIENT_TEMPERATURE_WARNING : 46|1@1+ (1,0) [0|1] "" Vector__XXX
 SG_ AMBIENT_OVERTEMPERATURE : 47|1@1+ (1,0) [0|1] "" Vector__XXX
 SG_ AMBIENT_TEMPSENSOR_ERROR : 48|1@1+ (1,0) [0|1] "" Vector__XXX
 SG_ POWERMODULE_CLAMPING_TIMEOUT : 49|1@1+ (1,0) [0|1] "" Vector__XXX
 SG_ DCBUS_RIPPLE_TO_HIGH : 50|1@1+ (1,0) [0|1] "" Vector__XXX
 SG_ MOTOR_I2XT_WARNING : 51|1@1+ (1,0) [0|1] "" Vector__XXX
 SG_ MOTOR_I2XT_ERROR : 52|1@1+ (1,0) [0|1] "" Vector__XXX
 SG_ MOTOR_FIELDWEAKENING_ERROR : 53|1@1+ (1,0) [0|1] "" Vector__XXX
 SG_ INVALID_PARAMETER_COMBINATION : 54|1@1+ (1,0) [0|1] "" Vector__XXX
 SG_ PLUG_COVER_SENSOR_SIGNAL_LOW : 55|1@1+ (1,0) [0|1] "" Vector__XXX
 SG_ MOTOR_CONNECTION_TEST_FAILED : 56|1@1+ (1,0) [0|1] "" Vector__XXX
 SG_ POWERMODULE_IXT_WARNING : 57|1@1+ (1,0) [0|1] "" Vector__XXX
 SG_ ISOLATION_FAULT : 58|1@1+ (1,0) [0|1] "" Vector__XXX

BO_ 455 TxPDO_InverterAStatus_7: 8 Inverters
 SG_ Inverter_A_Statusword_7 : 0|7@1+ (1,0) [0|127] "" Vector__XXX
 SG_ EVENTBUFFER_NEW_EVENT : 16|1@1+ (1,0) [0|1] "" Vector__XXX
 SG_ EVENTBUFFER_OVERFLOW : 17|1@1+ (1,0) [0|1] "" Vector__XXX
 SG_ POWERMODULE_TRIPZONE_OVERCURRE : 18|1@1+ (1,0) [0|1] "" Vector__XXX
 SG_ POWERMODULE_CURRENT_OFFSET_INI : 19|1@1+ (1,0) [0|1] "" Vector__XXX
 SG_ POWERMODULE_TEMPSENSOR_ERROR : 20|1@1+ (1,0) [0|1] "" Vector__XXX
 SG_ POWERMODULE_TEMPERATURE_WARNIN : 21|1@1+ (1,0) [0|1] "" Vector__XXX
 SG_ POWERMODULE_OVERTEMPERATURE : 22|1@1+ (1,0) [0|1] "" Vector__XXX
 SG_ POWERMODULE_IXT_FAULT : 23|1@1+ (1,0) [0|1] "" Vector__XXX
 SG_ POWERMODULE_SW_OVERCURRENT : 24|1@1+ (1,0) [0|1] "" Vector__XXX
 SG_ POWERMODULE_PATTERNDATA_INCONS : 25|1@1+ (1,0) [0|1] "" Vector__XXX
 SG_ DCBUS_TRIPZONE_OVERVOLTAGE : 26|1@1+ (1,0) [0|1] "" Vector__XXX
 SG_ DCBUS_SW_OVERVOLTAGE : 27|1@1+ (1,0) [0|1] "" Vector__XXX
 SG_ DCBUS_SW_UNDERVOLTAGE : 28|1@1+ (1,0) [0|1] "" Vector__XXX
 SG_ NEIGHBOUR_FAULT : 29|1@1+ (1,0) [0|1] "" Vector__XXX
 SG_ MOTOR_TEMPSENSOR_ERROR : 30|1@1+ (1,0) [0|1] "" Vector__XXX
 SG_ MOTOR_TEMPERATURE_WARNING : 31|1@1+ (1,0) [0|1] "" Vector__XXX
 SG_ MOTOR_OVERTEMPERATURE : 32|1@1+ (1,0) [0|1] "" Vector__XXX
 SG_ MOTOR_STATOR_FREQ_TO_HIGH : 33|1@1+ (1,0) [0|1] "" Vector__XXX
 SG_ SUPPLYVOLTAGE_ERROR : 34|1@1+ (1,0) [0|1] "" Vector__XXX
 SG_ RPDO_TIMEOUT : 35|1@1+ (1,0) [0|1] "" Vector__XXX
 SG_ NMT_NOT_OPERATIONAL : 36|1@1+ (1,0) [0|1] "" Vector__XXX
 SG_ TASKOVERRUN : 37|1@1+ (1,0) [0|1] "" Vector__XXX
 SG_ NETSYNC_ERROR : 38|1@1+ (1,0) [0|1] "" Vector__XXX
 SG_ POSDEVICE_SIGNAL_TO_LOW : 39|1@1+ (1,0) [0|1] "" Vector__XXX
 SG_ POSDEVICE_SIGNAL_TO_HIGH : 40|1@1+ (1,0) [0|1] "" Vector__XXX
 SG_ RESOLVER_CALIBRATION_FAILED : 41|1@1+ (1,0) [0|1] "" Vector__XXX
 SG_ SYSTEM_FAULT : 42|1@1+ (1,0) [0|1] "" Vector__XXX
 SG_ INTERLOCK_OPEN : 43|1@1+ (1,0) [0|1] "" Vector__XXX
 SG_ APPC_HAS_GATE_DRIVER_DISABLED : 44|1@1+ (1,0) [0|1] "" Vector__XXX
 SG_ MOTOR_STALL_ERROR : 45|1@1+ (1,0) [0|1] "" Vector__XXX
 SG_ AMBIENT_TEMPERATURE_WARNING : 46|1@1+ (1,0) [0|1] "" Vector__XXX
 SG_ AMBIENT_OVERTEMPERATURE : 47|1@1+ (1,0) [0|1] "" Vector__XXX
 SG_ AMBIENT_TEMPSENSOR_ERROR : 48|1@1+ (1,0) [0|1] "" Vector__XXX
 SG_ POWERMODULE_CLAMPING_TIMEOUT : 49|1@1+ (1,0) [0|1] "" Vector__XXX
 SG_ DCBUS_RIPPLE_TO_HIGH : 50|1@1+ (1,0) [0|1] "" Vector__XXX
 SG_ MOTOR_I2XT_WARNING : 51|1@1+ (1,0) [0|1] "" Vector__XXX
 SG_ MOTOR_I2XT_ERROR : 52|1@1+ (1,0) [0|1] "" Vector__XXX
 SG_ MOTOR_FIELDWEAKENING_ERROR : 53|1@1+ (1,0) [0|1] "" Vector__XXX
 SG_ INVALID_PARAMETER_COMBINATION : 54|1@1+ (1,0) [0|1] "" Vector__XXX
 SG_ PLUG_COVER_SENSOR_SIGNAL_LOW : 55|1@1+ (1,0) [0|1] "" Vector__XXX
 SG_ MOTOR_CONNECTION_TEST_FAILED : 56|1@1+ (1,0) [0|1] "" Vector__XXX
 SG_ POWERMODULE_IXT_WARNING : 57|1@1+ (1,0) [0|1] "" Vector__XXX
 SG_ ISOLATION_FAULT : 58|1@1+ (1,0) [0|1] "" Vector__XXX

BO_ 456 TxPDO_InverterAStatus_8: 8 Inverters
 SG_ Inverter_A_Statusword_8 : 0|7@1+ (1,0) [0|127] "" Vector__XXX
 SG_ EVENTBUFFER_NEW_EVENT : 16|1@1+ (1,0) [0|1] "" Vector__XXX
 SG_ EVENTBUFFER_OVERFLOW : 17|1@1+ (1,0) [0|1] "" Vector__XXX
 SG_ POWERMODULE_TRIPZONE_OVERCURRE : 18|1@1+ (1,0) [0|1] "" Vector__XXX
 SG_ POWERMODULE_CURRENT_OFFSET_INI : 19|1@1+ (1,0) [0|1] "" Vector__XXX
 SG_ POWERMODULE_TEMPSENSOR_ERROR : 20|1@1+ (1,0) [0|1] "" Vector__XXX
 SG_ POWERMODULE_TEMPERATURE_WARNIN : 21|1@1+ (1,0) [0|1] "" Vector__XXX
 SG_ POWERMODULE_OVERTEMPERATURE : 22|1@1+ (1,0) [0|1] "" Vector__XXX
 SG_ POWERMODULE_IXT_FAULT : 23|1@1+ (1,0) [0|1] "" Vector__XXX
 SG_ POWERMODULE_SW_OVERCURRENT : 24|1@1+ (1,0) [0|1] "" Vector__XXX
 SG_ POWERMODULE_PATTERNDATA_INCONS : 25|1@1+ (1,0) [0|1] "" Vector__XXX
 SG_ DCBUS_TRIPZONE_OVERVOLTAGE : 26|1@1+ (1,0) [0|1] "" Vector__XXX
 SG_ DCBUS_SW_OVERVOLTAGE : 27|1@1+ (1,0) [0|1] "" Vector__XXX
 SG_ DCBUS_SW_UNDERVOLTAGE : 28|1@1+ (1,0) [0|1] "" Vector__XXX
 SG_ NEIGHBOUR_FAULT : 29|1@1+ (1,0) [0|1] "" Vector__XXX
 SG_ MOTOR_TEMPSENSOR_ERROR : 30|1@1+ (1,0) [0|1] "" Vector__XXX
 SG_ MOTOR_TEMPERATURE_WARNING : 31|1@1+ (1,0) [0|1] "" Vector__XXX
 SG_ MOTOR_OVERTEMPERATURE : 32|1@1+ (1,0) [0|1] "" Vector__XXX
 SG_ MOTOR_STATOR_FREQ_TO_HIGH : 33|1@1+ (1,0) [0|1] "" Vector__XXX
 SG_ SUPPLYVOLTAGE_ERROR : 34|1@1+ (1,0) [0|1] "" Vector__XXX
 SG_ RPDO_TIMEOUT : 35|1@1+ (1,0) [0|1] "" Vector__XXX
 SG_ NMT_NOT_OPERATIONAL : 36|1@1+ (1,0) [0|1] "" Vector__XXX
 SG_ TASKOVERRUN : 37|1@1+ (1,0) [0|1] "" Vector__XXX
 SG_ NETSYNC_ERROR : 38|1@1+ (1,0) [0|1] "" Vector__XXX
 SG_ POSDEVICE_SIGNAL_TO_LOW : 39|1@1+ (1,0) [0|1] "" Vector__XXX
 SG_ POSDEVICE_SIGNAL_TO_HIGH : 40|1@1+ (1,0) [0|1] "" Vector__XXX
 SG_ RESOLVER_CALIBRATION_FAILED : 41|1@1+ (1,0) [0|1] "" Vector__XXX
 SG_ SYSTEM_FAULT : 42|1@1+ (1,0) [0|1] "" Vector__XXX
 SG_ INTERLOCK_OPEN : 43|1@1+ (1,0) [0|1] "" Vector__XXX
 SG_ APPC_HAS_GATE_DRIVER_DISABLED : 44|1@1+ (1,0) [0|1] "" Vector__XXX
 SG_ MOTOR_STALL_ERROR : 45|1@1+ (1,0) [0|1] "" Vector__XXX
 SG_ AMBIENT_TEMPERATURE_WARNING : 46|1@1+ (1,0) [0|1] "" Vector__XXX
 SG_ AMBIENT_OVERTEMPERATURE : 47|1@1+ (1,0) [0|1] "" Vector__XXX
 SG_ AMBIENT_TEMPSENSOR_ERROR : 48|1@1+ (1,0) [0|1] "" Vector__XXX
 SG_ POWERMODULE_CLAMPING_TIMEOUT : 49|1@1+ (1,0) [0|1] "" Vector__XXX
 SG_ DCBUS_RIPPLE_TO_HIGH : 50|1@1+ (1,0) [0|1] "" Vector__XXX
 SG_ MOTOR_I2XT_WARNING : 51|1@1+ (1,0) [0|1] "" Vector__XXX
 SG_ MOTOR_I2XT_ERROR : 52|1@1+ (1,0) [0|1] "" Vector__XXX
 SG_ MOTOR_FIELDWEAKENING_ERROR : 53|1@1+ (1,0) [0|1] "" Vector__XXX
 SG_ INVALID_PARAMETER_COMBINATION : 54|1@1+ (1,0) [0|1] "" Vector__XXX
 SG_ PLUG_COVER_SENSOR_SIGNAL_LOW : 55|1@1+ (1,0) [0|1] "" Vector__XXX
 SG_ MOTOR_CONNECTION_TEST_FAILED : 56|1@1+ (1,0) [0|1] "" Vector__XXX
 SG_ POWERMODULE_IXT_WARNING : 57|1@1+ (1,0) [0|1] "" Vector__XXX
 SG_ ISOLATION_FAULT : 58|1@1+ (1,0) [0|1] "" Vector__XXX

BO_ 457 TxPDO_InverterAStatus_9: 8 Inverters
 SG_ Inverter_A_Statusword_9 : 0|7@1+ (1,0) [0|127] "" Vector__XXX
 SG_ EVENTBUFFER_NEW_EVENT : 16|1@1+ (1,0) [0|1] "" Vector__XXX
 SG_ EVENTBUFFER_OVERFLOW : 17|1@1+ (1,0) [0|1] "" Vector__XXX
 SG_ POWERMODULE_TRIPZONE_OVERCURRE : 18|1@1+ (1,0) [0|1] "" Vector__XXX
 SG_ POWERMODULE_CURRENT_OFFSET_INI : 19|1@1+ (1,0) [0|1] "" Vector__XXX
 SG_ POWERMODULE_TEMPSENSOR_ERROR : 20|1@1+ (1,0) [0|1] "" Vector__XXX
 SG_ POWERMODULE_TEMPERATURE_WARNIN : 21|1@1+ (1,0) [0|1] "" Vector__XXX
 SG_ POWERMODULE_OVERTEMPERATURE : 22|1@1+ (1,0) [0|1] "" Vector__XXX
 SG_ POWERMODULE_IXT_FAULT : 23|1@1+ (1,0) [0|1] "" Vector__XXX
 SG_ POWERMODULE_SW_OVERCURRENT : 24|1@1+ (1,0) [0|1] "" Vector__XXX
 SG_ POWERMODULE_PATTERNDATA_INCONS : 25|1@1+ (1,0) [0|1] "" Vector__XXX
 SG_ DCBUS_TRIPZONE_OVERVOLTAGE : 26|1@1+ (1,0) [0|1] "" Vector__XXX
 SG_ DCBUS_SW_OVERVOLTAGE : 27|1@1+ (1,0) [0|1] "" Vector__XXX
 SG_ DCBUS_SW_UNDERVOLTAGE : 28|1@1+ (1,0) [0|1] "" Vector__XXX
 SG_ NEIGHBOUR_FAULT : 29|1@1+ (1,0) [0|1] "" Vector__XXX
 SG_ MOTOR_TEMPSENSOR_ERROR : 30|1@1+ (1,0) [0|1] "" Vector__XXX
 SG_ MOTOR_TEMPERATURE_WARNING : 31|1@1+ (1,0) [0|1] "" Vector__XXX
 SG_ MOTOR_OVERTEMPERATURE : 32|1@1+ (1,0) [0|1] "" Vector__XXX
 SG_ MOTOR_STATOR_FREQ_TO_HIGH : 33|1@1+ (1,0) [0|1] "" Vector__XXX
 SG_ SUPPLYVOLTAGE_ERROR : 34|1@1+ (1,0) [0|1] "" Vector__XXX
 SG_ RPDO_TIMEOUT : 35|1@1+ (1,0) [0|1] "" Vector__XXX
 SG_ NMT_NOT_OPERATIONAL : 36|1@1+ (1,0) [0|1] "" Vector__XXX
 SG_ TASKOVERRUN : 37|1@1+ (1,0) [0|1] "" Vector__XXX
 SG_ NETSYNC_ERROR : 38|1@1+ (1,0) [0|1] "" Vector__XXX
 SG_ POSDEVICE_SIGNAL_TO_LOW : 39|1@1+ (1,0) [0|1] "" Vector__XXX
 SG_ POSDEVICE_SIGNAL_TO_HIGH : 40|1@1+ (1,0) [0|1] "" Vector__XXX
 SG_ RESOLVER_CALIBRATION_FAILED : 41|1@1+ (1,0) [0|1] "" Vector__XXX
 SG_ SYSTEM_FAULT : 42|1@1+ (1,0) [0|1] "" Vector__XXX
 SG_ INTERLOCK_OPEN : 43|1@1+ (1,0) [0|1] "" Vector__XXX
 SG_ APPC_HAS_GATE_DRIVER_DISABLED : 44|1@1+ (1,0) [0|1] "" Vector__XXX
 SG_ MOTOR_STALL_ERROR : 45|1@1+ (1,0) [0|1] "" Vector__XXX
 SG_ AMBIENT_TEMPERATURE_WARNING : 46|1@1+ (1,0) [0|1] "" Vector__XXX
 SG_ AMBIENT_OVERTEMPERATURE : 47|1@1+ (1,0) [0|1] "" Vector__XXX
 SG_ AMBIENT_TEMPSENSOR_ERROR : 48|1@1+ (1,0) [0|1] "" Vector__XXX
 SG_ POWERMODULE_CLAMPING_TIMEOUT : 49|1@1+ (1,0) [0|1] "" Vector__XXX
 SG_ DCBUS_RIPPLE_TO_HIGH : 50|1@1+ (1,0) [0|1] "" Vector__XXX
 SG_ MOTOR_I2XT_WARNING : 51|1@1+ (1,0) [0|1] "" Vector__XXX
 SG_ MOTOR_I2XT_ERROR : 52|1@1+ (1,0) [0|1] "" Vector__XXX
 SG_ MOTOR_FIELDWEAKENING_ERROR : 53|1@1+ (1,0) [0|1] "" Vector__XXX
 SG_ INVALID_PARAMETER_COMBINATION : 54|1@1+ (1,0) [0|1] "" Vector__XXX
 SG_ PLUG_COVER_SENSOR_SIGNAL_LOW : 55|1@1+ (1,0) [0|1] "" Vector__XXX
 SG_ MOTOR_CONNECTION_TEST_FAILED : 56|1@1+ (1,0) [0|1] "" Vector__XXX
 SG_ POWERMODULE_IXT_WARNING : 57|1@1+ (1,0) [0|1] "" Vector__XXX
 SG_ ISOLATION_FAULT : 58|1@1+ (1,0) [0|1] "" Vector__XXX

BO_ 458 TxPDO_InverterAStatus_10: 8 Inverters
 SG_ Inverter_A_Statusword_10 : 0|7@1+ (1,0) [0|127] "" Vector__XXX
 SG_ EVENTBUFFER_NEW_EVENT : 16|1@1+ (1,0) [0|1] "" Vector__XXX
 SG_ EVENTBUFFER_OVERFLOW : 17|1@1+ (1,0) [0|1] "" Vector__XXX
 SG_ POWERMODULE_TRIPZONE_OVERCURRE : 18|1@1+ (1,0) [0|1] "" Vector__XXX
 SG_ POWERMODULE_CURRENT_OFFSET_INI : 19|1@1+ (1,0) [0|1] "" Vector__XXX
 SG_ POWERMODULE_TEMPSENSOR_ERROR : 20|1@1+ (1,0) [0|1] "" Vector__XXX
 SG_ POWERMODULE_TEMPERATURE_WARNIN : 21|1@1+ (1,0) [0|1] "" Vector__XXX
 SG_ POWERMODULE_OVERTEMPERATURE : 22|1@1+ (1,0) [0|1] "" Vector__XXX
 SG_ POWERMODULE_IXT_FAULT : 23|1@1+ (1,0) [0|1] "" Vector__XXX
 SG_ POWERMODULE_SW_OVERCURRENT : 24|1@1+ (1,0) [0|1] "" Vector__XXX
 SG_ POWERMODULE_PATTERNDATA_INCONS : 25|1@1+ (1,0) [0|1] "" Vector__XXX
 SG_ DCBUS_TRIPZONE_OVERVOLTAGE : 26|1@1+ (1,0) [0|1] "" Vector__XXX
 SG_ DCBUS_SW_OVERVOLTAGE : 27|1@1+ (1,0) [0|1] "" Vector__XXX
 SG_ DCBUS_SW_UNDERVOLTAGE : 28|1@1+ (1,0) [0|1] "" Vector__XXX
 SG_ NEIGHBOUR_FAULT : 29|1@1+ (1,0) [0|1] "" Vector__XXX
 SG_ MOTOR_TEMPSENSOR_ERROR : 30|1@1+ (1,0) [0|1] "" Vector__XXX
 SG_ MOTOR_TEMPERATURE_WARNING : 31|1@1+ (1,0) [0|1] "" Vector__XXX
 SG_ MOTOR_OVERTEMPERATURE : 32|1@1+ (1,0) [0|1] "" Vector__XXX
 SG_ MOTOR_STATOR_FREQ_TO_HIGH : 33|1@1+ (1,0) [0|1] "" Vector__XXX
 SG_ SUPPLYVOLTAGE_ERROR : 34|1@1+ (1,0) [0|1] "" Vector__XXX
 SG_ RPDO_TIMEOUT : 35|1@1+ (1,0) [0|1] "" Vector__XXX
 SG_ NMT_NOT_OPERATIONAL : 36|1@1+ (1,0) [0|1] "" Vector__XXX
 SG_ TASKOVERRUN : 37|1@1+ (1,0) [0|1] "" Vector__XXX
 SG_ NETSYNC_ERROR : 38|1@1+ (1,0) [0|1] "" Vector__XXX
 SG_ POSDEVICE_SIGNAL_TO_LOW : 39|1@1+ (1,0) [0|1] "" Vector__XXX
 SG_ POSDEVICE_SIGNAL_TO_HIGH : 40|1@1+ (1,0) [0|1] "" Vector__XXX
 SG_ RESOLVER_CALIBRATION_FAILED : 41|1@1+ (1,0) [0|1] "" Vector__XXX
 SG_ SYSTEM_FAULT : 42|1@1+ (1,0) [0|1] "" Vector__XXX
 SG_ INTERLOCK_OPEN : 43|1@1+ (1,0) [0|1] "" Vector__XXX
 SG_ APPC_HAS_GATE_DRIVER_DISABLED : 44|1@1+ (1,0) [0|1] "" Vector__XXX
 SG_ MOTOR_STALL_ERROR : 45|1@1+ (1,0) [0|1] "" Vector__XXX
 SG_ AMBIENT_TEMPERATURE_WARNING : 46|1@1+ (1,0) [0|1] "" Vector__XXX
 SG_ AMBIENT_OVERTEMPERATURE : 47|1@1+ (1,0) [0|1] "" Vector__XXX
 SG_ AMBIENT_TEMPSENSOR_ERROR : 48|1@1+ (1,0) [0|1] "" Vector__XXX
 SG_ POWERMODULE_CLAMPING_TIMEOUT : 49|1@1+ (1,0) [0|1] "" Vector__XXX
 SG_ DCBUS_RIPPLE_TO_HIGH : 50|1@1+ (1,0) [0|1] "" Vector__XXX
 SG_ MOTOR_I2XT_WARNING : 51|1@1+ (1,0) [0|1] "" Vector__XXX
 SG_ MOTOR_I2XT_ERROR : 52|1@1+ (1,0) [0|1] "" Vector__XXX
 SG_ MOTOR_FIELDWEAKENING_ERROR : 53|1@1+ (1,0) [0|1] "" Vector__XXX
 SG_ INVALID_PARAMETER_COMBINATION : 54|1@1+ (1,0) [0|1] "" Vector__XXX
 SG_ PLUG_COVER_SENSOR_SIGNAL_LOW : 55|1@1+ (1,0) [0|1] "" Vector__XXX
 SG_ MOTOR_CONNECTION_TEST_FAILED : 56|1@1+ (1,0) [0|1] "" Vector__XXX
 SG_ POWERMODULE_IXT_WARNING : 57|1@1+ (1,0) [0|1] "" Vector__XXX
 SG_ ISOLATION_FAULT : 58|1@1+ (1,0) [0|1] "" Vector__XXX

BO_ 459 TxPDO_InverterAStatus_11: 8 Inverters
 SG_ Inverter_A_Statusword_11 : 0|7@1+ (1,0) [0|127] "" Vector__XXX
 SG_ EVENTBUFFER_NEW_EVENT : 16|1@1+ (1,0) [0|1] "" Vector__XXX
 SG_ EVENTBUFFER_OVERFLOW : 17|1@1+ (1,0) [0|1] "" Vector__XXX
 SG_ POWERMODULE_TRIPZONE_OVERCURRE : 18|1@1+ (1,0) [0|1] "" Vector__XXX
 SG_ POWERMODULE_CURRENT_OFFSET_INI : 19|1@1+ (1,0) [0|1] "" Vector__XXX
 SG_ POWERMODULE_TEMPSENSOR_ERROR : 20|1@1+ (1,0) [0|1] "" Vector__XXX
 SG_ POWERMODULE_TEMPERATURE_WARNIN : 21|1@1+ (1,0) [0|1] "" Vector__XXX
 SG_ POWERMODULE_OVERTEMPERATURE : 22|1@1+ (1,0) [0|1] "" Vector__XXX
 SG_ POWERMODULE_IXT_FAULT : 23|1@1+ (1,0) [0|1] "" Vector__XXX
 SG_ POWERMODULE_SW_OVERCURRENT : 24|1@1+ (1,0) [0|1] "" Vector__XXX
 SG_ POWERMODULE_PATTERNDATA_INCONS : 25|1@1+ (1,0) [0|1] "" Vector__XXX
 SG_ DCBUS_TRIPZONE_OVERVOLTAGE : 26|1@1+ (1,0) [0|1] "" Vector__XXX
 SG_ DCBUS_SW_OVERVOLTAGE : 27|1@1+ (1,0) [0|1] "" Vector__XXX
 SG_ DCBUS_SW_UNDERVOLTAGE : 28|1@1+ (1,0) [0|1] "" Vector__XXX
 SG_ NEIGHBOUR_FAULT : 29|1@1+ (1,0) [0|1] "" Vector__XXX
 SG_ MOTOR_TEMPSENSOR_ERROR : 30|1@1+ (1,0) [0|1] "" Vector__XXX
 SG_ MOTOR_TEMPERATURE_WARNING : 31|1@1+ (1,0) [0|1] "" Vector__XXX
 SG_ MOTOR_OVERTEMPERATURE : 32|1@1+ (1,0) [0|1] "" Vector__XXX
 SG_ MOTOR_STATOR_FREQ_TO_HIGH : 33|1@1+ (1,0) [0|1] "" Vector__XXX
 SG_ SUPPLYVOLTAGE_ERROR : 34|1@1+ (1,0) [0|1] "" Vector__XXX
 SG_ RPDO_TIMEOUT : 35|1@1+ (1,0) [0|1] "" Vector__XXX
 SG_ NMT_NOT_OPERATIONAL : 36|1@1+ (1,0) [0|1] "" Vector__XXX
 SG_ TASKOVERRUN : 37|1@1+ (1,0) [0|1] "" Vector__XXX
 SG_ NETSYNC_ERROR : 38|1@1+ (1,0) [0|1] "" Vector__XXX
 SG_ POSDEVICE_SIGNAL_TO_LOW : 39|1@1+ (1,0) [0|1] "" Vector__XXX
 SG_ POSDEVICE_SIGNAL_TO_HIGH : 40|1@1+ (1,0) [0|1] "" Vector__XXX
 SG_ RESOLVER_CALIBRATION_FAILED : 41|1@1+ (1,0) [0|1] "" Vector__XXX
 SG_ SYSTEM_FAULT : 42|1@1+ (1,0) [0|1] "" Vector__XXX
 SG_ INTERLOCK_OPEN : 43|1@1+ (1,0) [0|1] "" Vector__XXX
 SG_ APPC_HAS_GATE_DRIVER_DISABLED : 44|1@1+ (1,0) [0|1] "" Vector__XXX
 SG_ MOTOR_STALL_ERROR : 45|1@1+ (1,0) [0|1] "" Vector__XXX
 SG_ AMBIENT_TEMPERATURE_WARNING : 46|1@1+ (1,0) [0|1] "" Vector__XXX
 SG_ AMBIENT_OVERTEMPERATURE : 47|1@1+ (1,0) [0|1] "" Vector__XXX
 SG_ AMBIENT_TEMPSENSOR_ERROR : 48|1@1+ (1,0) [0|1] "" Vector__XXX
 SG_ POWERMODULE_CLAMPING_TIMEOUT : 49|1@1+ (1,0) [0|1] "" Vector__XXX
 SG_ DCBUS_RIPPLE_TO_HIGH : 50|1@1+ (1,0) [0|1] "" Vector__XXX
 SG_ MOTOR_I2XT_WARNING : 51|1@1+ (1,0) [0|1] "" Vector__XXX
 SG_ MOTOR_I2XT_ERROR : 52|1@1+ (1,0) [0|1] "" Vector__XXX
 SG_ MOTOR_FIELDWEAKENING_ERROR : 53|1@1+ (1,0) [0|1] "" Vector__XXX
 SG_ INVALID_PARAMETER_COMBINATION : 54|1@1+ (1,0) [0|1] "" Vector__XXX
 SG_ PLUG_COVER_SENSOR_SIGNAL_LOW : 55|1@1+ (1,0) [0|1] "" Vector__XXX
 SG_ MOTOR_CONNECTION_TEST_FAILED : 56|1@1+ (1,0) [0|1] "" Vector__XXX
 SG_ POWERMODULE_IXT_WARNING : 57|1@1+ (1,0) [0|1] "" Vector__XXX
 SG_ ISOLATION_FAULT : 58|1@1+ (1,0) [0|1] "" Vector__XXX

BO_ 460 TxPDO_InverterAStatus_12: 8 Inverters
 SG_ Inverter_A_Statusword_12 : 0|7@1+ (1,0) [0|127] "" Vector__XXX
 SG_ EVENTBUFFER_NEW_EVENT : 16|1@1+ (1,0) [0|1] "" Vector__XXX
 SG_ EVENTBUFFER_OVERFLOW : 17|1@1+ (1,0) [0|1] "" Vector__XXX
 SG_ POWERMODULE_TRIPZONE_OVERCURRE : 18|1@1+ (1,0) [0|1] "" Vector__XXX
 SG_ POWERMODULE_CURRENT_OFFSET_INI : 19|1@1+ (1,0) [0|1] "" Vector__XXX
 SG_ POWERMODULE_TEMPSENSOR_ERROR : 20|1@1+ (1,0) [0|1] "" Vector__XXX
 SG_ POWERMODULE_TEMPERATURE_WARNIN : 21|1@1+ (1,0) [0|1] "" Vector__XXX
 SG_ POWERMODULE_OVERTEMPERATURE : 22|1@1+ (1,0) [0|1] "" Vector__XXX
 SG_ POWERMODULE_IXT_FAULT : 23|1@1+ (1,0) [0|1] "" Vector__XXX
 SG_ POWERMODULE_SW_OVERCURRENT : 24|1@1+ (1,0) [0|1] "" Vector__XXX
 SG_ POWERMODULE_PATTERNDATA_INCONS : 25|1@1+ (1,0) [0|1] "" Vector__XXX
 SG_ DCBUS_TRIPZONE_OVERVOLTAGE : 26|1@1+ (1,0) [0|1] "" Vector__XXX
 SG_ DCBUS_SW_OVERVOLTAGE : 27|1@1+ (1,0) [0|1] "" Vector__XXX
 SG_ DCBUS_SW_UNDERVOLTAGE : 28|1@1+ (1,0) [0|1] "" Vector__XXX
 SG_ NEIGHBOUR_FAULT : 29|1@1+ (1,0) [0|1] "" Vector__XXX
 SG_ MOTOR_TEMPSENSOR_ERROR : 30|1@1+ (1,0) [0|1] "" Vector__XXX
 SG_ MOTOR_TEMPERATURE_WARNING : 31|1@1+ (1,0) [0|1] "" Vector__XXX
 SG_ MOTOR_OVERTEMPERATURE : 32|1@1+ (1,0) [0|1] "" Vector__XXX
 SG_ MOTOR_STATOR_FREQ_TO_HIGH : 33|1@1+ (1,0) [0|1] "" Vector__XXX
 SG_ SUPPLYVOLTAGE_ERROR : 34|1@1+ (1,0) [0|1] "" Vector__XXX
 SG_ RPDO_TIMEOUT : 35|1@1+ (1,0) [0|1] "" Vector__XXX
 SG_ NMT_NOT_OPERATIONAL : 36|1@1+ (1,0) [0|1] "" Vector__XXX
 SG_ TASKOVERRUN : 37|1@1+ (1,0) [0|1] "" Vector__XXX
 SG_ NETSYNC_ERROR : 38|1@1+ (1,0) [0|1] "" Vector__XXX
 SG_ POSDEVICE_SIGNAL_TO_LOW : 39|1@1+ (1,0) [0|1] "" Vector__XXX
 SG_ POSDEVICE_SIGNAL_TO_HIGH : 40|1@1+ (1,0) [0|1] "" Vector__XXX
 SG_ RESOLVER_CALIBRATION_FAILED : 41|1@1+ (1,0) [0|1] "" Vector__XXX
 SG_ SYSTEM_FAULT : 42|1@1+ (1,0) [0|1] "" Vector__XXX
 SG_ INTERLOCK_OPEN : 43|1@1+ (1,0) [0|1] "" Vector__XXX
 SG_ APPC_HAS_GATE_DRIVER_DISABLED : 44|1@1+ (1,0) [0|1] "" Vector__XXX
 SG_ MOTOR_STALL_ERROR : 45|1@1+ (1,0) [0|1] "" Vector__XXX
 SG_ AMBIENT_TEMPERATURE_WARNING : 46|1@1+ (1,0) [0|1] "" Vector__XXX
 SG_ AMBIENT_OVERTEMPERATURE : 47|1@1+ (1,0) [0|1] "" Vector__XXX
 SG_ AMBIENT_TEMPSENSOR_ERROR : 48|1@1+ (1,0) [0|1] "" Vector__XXX
 SG_ POWERMODULE_CLAMPING_TIMEOUT : 49|1@1+ (1,0) [0|1] "" Vector__XXX
 SG_ DCBUS_RIPPLE_TO_HIGH : 50|1@1+ (1,0) [0|1] "" Vector__XXX
 SG_ MOTOR_I2XT_WARNING : 51|1@1+ (1,0) [0|1] "" Vector__XXX
 SG_ MOTOR_I2XT_ERROR : 52|1@1+ (1,0) [0|1] "" Vector__XXX
 SG_ MOTOR_FIELDWEAKENING_ERROR : 53|1@1+ (1,0) [0|1] "" Vector__XXX
 SG_ INVALID_PARAMETER_COMBINATION : 54|1@1+ (1,0) [0|1] "" Vector__XXX
 SG_ PLUG_COVER_SENSOR_SIGNAL_LOW : 55|1@1+ (1,0) [0|1] "" Vector__XXX
 SG_ MOTOR_CONNECTION_TEST_FAILED : 56|1@1+ (1,0) [0|1] "" Vector__XXX
 SG_ POWERMODULE_IXT_WARNING : 57|1@1+ (1,0) [0|1] "" Vector__XXX
 SG_ ISOLATION_FAULT : 58|1@1+ (1,0) [0|1] "" Vector__XXX

BO_ 461 TxPDO_InverterAStatus_13: 8 Inverters
 SG_ Inverter_A_Statusword_13 : 0|7@1+ (1,0) [0|127] "" Vector__XXX
 SG_ EVENTBUFFER_NEW_EVENT : 16|1@1+ (1,0) [0|1] "" Vector__XXX
 SG_ EVENTBUFFER_OVERFLOW : 17|1@1+ (1,0) [0|1] "" Vector__XXX
 SG_ POWERMODULE_TRIPZONE_OVERCURRE : 18|1@1+ (1,0) [0|1] "" Vector__XXX
 SG_ POWERMODULE_CURRENT_OFFSET_INI : 19|1@1+ (1,0) [0|1] "" Vector__XXX
 SG_ POWERMODULE_TEMPSENSOR_ERROR : 20|1@1+ (1,0) [0|1] "" Vector__XXX
 SG_ POWERMODULE_TEMPERATURE_WARNIN : 21|1@1+ (1,0) [0|1] "" Vector__XXX
 SG_ POWERMODULE_OVERTEMPERATURE : 22|1@1+ (1,0) [0|1] "" Vector__XXX
 SG_ POWERMODULE_IXT_FAULT : 23|1@1+ (1,0) [0|1] "" Vector__XXX
 SG_ POWERMODULE_SW_OVERCURRENT : 24|1@1+ (1,0) [0|1] "" Vector__XXX
 SG_ POWERMODULE_PATTERNDATA_INCONS : 25|1@1+ (1,0) [0|1] "" Vector__XXX
 SG_ DCBUS_TRIPZONE_OVERVOLTAGE : 26|1@1+ (1,0) [0|1] "" Vector__XXX
 SG_ DCBUS_SW_OVERVOLTAGE : 27|1@1+ (1,0) [0|1] "" Vector__XXX
 SG_ DCBUS_SW_UNDERVOLTAGE : 28|1@1+ (1,0) [0|1] "" Vector__XXX
 SG_ NEIGHBOUR_FAULT : 29|1@1+ (1,0) [0|1] "" Vector__XXX
 SG_ MOTOR_TEMPSENSOR_ERROR : 30|1@1+ (1,0) [0|1] "" Vector__XXX
 SG_ MOTOR_TEMPERATURE_WARNING : 31|1@1+ (1,0) [0|1] "" Vector__XXX
 SG_ MOTOR_OVERTEMPERATURE : 32|1@1+ (1,0) [0|1] "" Vector__XXX
 SG_ MOTOR_STATOR_FREQ_TO_HIGH : 33|1@1+ (1,0) [0|1] "" Vector__XXX
 SG_ SUPPLYVOLTAGE_ERROR : 34|1@1+ (1,0) [0|1] "" Vector__XXX
 SG_ RPDO_TIMEOUT : 35|1@1+ (1,0) [0|1] "" Vector__XXX
 SG_ NMT_NOT_OPERATIONAL : 36|1@1+ (1,0) [0|1] "" Vector__XXX
 SG_ TASKOVERRUN : 37|1@1+ (1,0) [0|1] "" Vector__XXX
 SG_ NETSYNC_ERROR : 38|1@1+ (1,0) [0|1] "" Vector__XXX
 SG_ POSDEVICE_SIGNAL_TO_LOW : 39|1@1+ (1,0) [0|1] "" Vector__XXX
 SG_ POSDEVICE_SIGNAL_TO_HIGH : 40|1@1+ (1,0) [0|1] "" Vector__XXX
 SG_ RESOLVER_CALIBRATION_FAILED : 41|1@1+ (1,0) [0|1] "" Vector__XXX
 SG_ SYSTEM_FAULT : 42|1@1+ (1,0) [0|1] "" Vector__XXX
 SG_ INTERLOCK_OPEN : 43|1@1+ (1,0) [0|1] "" Vector__XXX
 SG_ APPC_HAS_GATE_DRIVER_DISABLED : 44|1@1+ (1,0) [0|1] "" Vector__XXX
 SG_ MOTOR_STALL_ERROR : 45|1@1+ (1,0) [0|1] "" Vector__XXX
 SG_ AMBIENT_TEMPERATURE_WARNING : 46|1@1+ (1,0) [0|1] "" Vector__XXX
 SG_ AMBIENT_OVERTEMPERATURE : 47|1@1+ (1,0) [0|1] "" Vector__XXX
 SG_ AMBIENT_TEMPSENSOR_ERROR : 48|1@1+ (1,0) [0|1] "" Vector__XXX
 SG_ POWERMODULE_CLAMPING_TIMEOUT : 49|1@1+ (1,0) [0|1] "" Vector__XXX
 SG_ DCBUS_RIPPLE_TO_HIGH : 50|1@1+ (1,0) [0|1] "" Vector__XXX
 SG_ MOTOR_I2XT_WARNING : 51|1@1+ (1,0) [0|1] "" Vector__XXX
 SG_ MOTOR_I2XT_ERROR : 52|1@1+ (1,0) [0|1] "" Vector__XXX
 SG_ MOTOR_FIELDWEAKENING_ERROR : 53|1@1+ (1,0) [0|1] "" Vector__XXX
 SG_ INVALID_PARAMETER_COMBINATION : 54|1@1+ (1,0) [0|1] "" Vector__XXX
 SG_ PLUG_COVER_SENSOR_SIGNAL_LOW : 55|1@1+ (1,0) [0|1] "" Vector__XXX
 SG_ MOTOR_CONNECTION_TEST_FAILED : 56|1@1+ (1,0) [0|1] "" Vector__XXX
 SG_ POWERMODULE_IXT_WARNING : 57|1@1+ (1,0) [0|1] "" Vector__XXX
 SG_ ISOLATION_FAULT : 58|1@1+ (1,0) [0|1] "" Vector__XXX

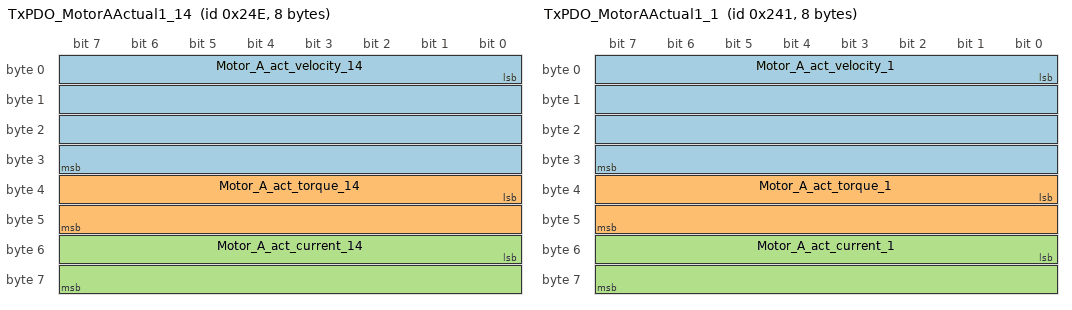
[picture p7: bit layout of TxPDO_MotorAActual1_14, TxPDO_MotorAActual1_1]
BO_ 590 TxPDO_MotorAActual1_14: 8 Inverters
 SG_ Motor_A_act_velocity_14 : 0|32@1- (6.103515625e-05,0) [-131072|131071.99994] "rpm" Vector__XXX
 SG_ Motor_A_act_torque_14 : 32|16@1- (0.1,0) [-3276.8|3276.7] "%" Vector__XXX
 SG_ Motor_A_act_current_14 : 48|16@1- (0.015625,0) [-512|511.984375] "A" Vector__XXX

BO_ 577 TxPDO_MotorAActual1_1: 8 Inverters
 SG_ Motor_A_act_velocity_1 : 0|32@1- (6.103515625e-05,0) [-131072|131071.99994] "rpm" Vector__XXX
 SG_ Motor_A_act_torque_1 : 32|16@1- (0.1,0) [-3276.8|3276.7] "%" Vector__XXX
 SG_ Motor_A_act_current_1 : 48|16@1- (0.015625,0) [-512|511.984375] "A" Vector__XXX

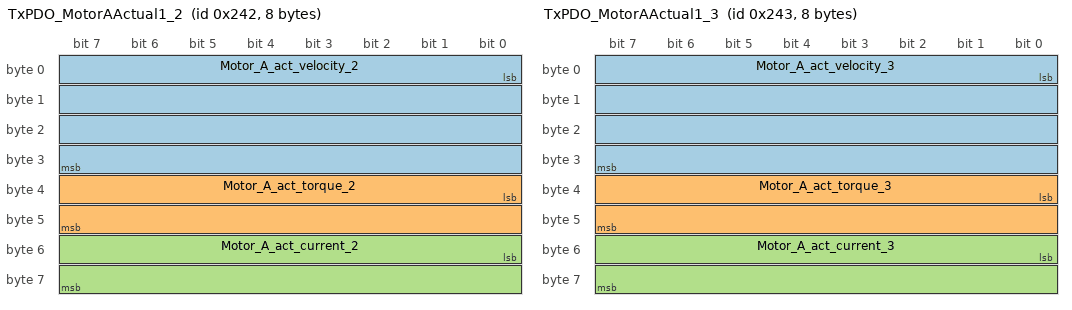
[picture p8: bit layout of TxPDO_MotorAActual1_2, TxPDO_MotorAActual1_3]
BO_ 578 TxPDO_MotorAActual1_2: 8 Inverters
 SG_ Motor_A_act_velocity_2 : 0|32@1- (6.103515625e-05,0) [-131072|131071.99994] "rpm" Vector__XXX
 SG_ Motor_A_act_torque_2 : 32|16@1- (0.1,0) [-3276.8|3276.7] "%" Vector__XXX
 SG_ Motor_A_act_current_2 : 48|16@1- (0.015625,0) [-512|511.984375] "A" Vector__XXX

BO_ 579 TxPDO_MotorAActual1_3: 8 Inverters
 SG_ Motor_A_act_velocity_3 : 0|32@1- (6.103515625e-05,0) [-131072|131071.99994] "rpm" Vector__XXX
 SG_ Motor_A_act_torque_3 : 32|16@1- (0.1,0) [-3276.8|3276.7] "%" Vector__XXX
 SG_ Motor_A_act_current_3 : 48|16@1- (0.015625,0) [-512|511.984375] "A" Vector__XXX

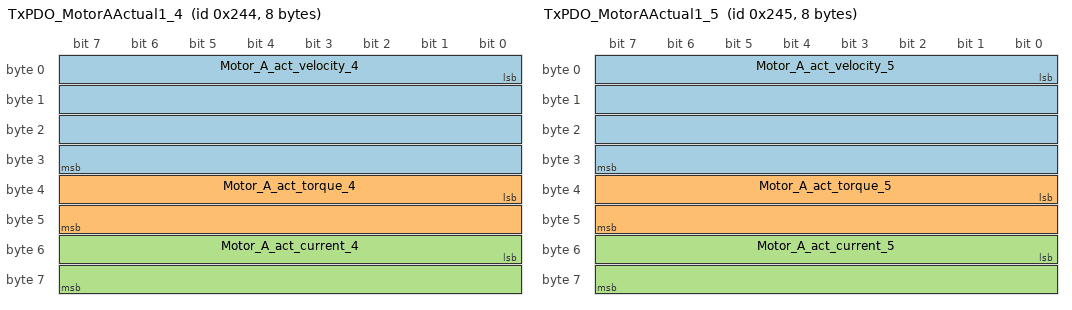
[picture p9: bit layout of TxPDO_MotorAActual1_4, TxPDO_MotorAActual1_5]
BO_ 580 TxPDO_MotorAActual1_4: 8 Inverters
 SG_ Motor_A_act_velocity_4 : 0|32@1- (6.103515625e-05,0) [-131072|131071.99994] "rpm" Vector__XXX
 SG_ Motor_A_act_torque_4 : 32|16@1- (0.1,0) [-3276.8|3276.7] "%" Vector__XXX
 SG_ Motor_A_act_current_4 : 48|16@1- (0.015625,0) [-512|511.984375] "A" Vector__XXX

BO_ 581 TxPDO_MotorAActual1_5: 8 Inverters
 SG_ Motor_A_act_velocity_5 : 0|32@1- (6.103515625e-05,0) [-131072|131071.99994] "rpm" Vector__XXX
 SG_ Motor_A_act_torque_5 : 32|16@1- (0.1,0) [-3276.8|3276.7] "%" Vector__XXX
 SG_ Motor_A_act_current_5 : 48|16@1- (0.015625,0) [-512|511.984375] "A" Vector__XXX

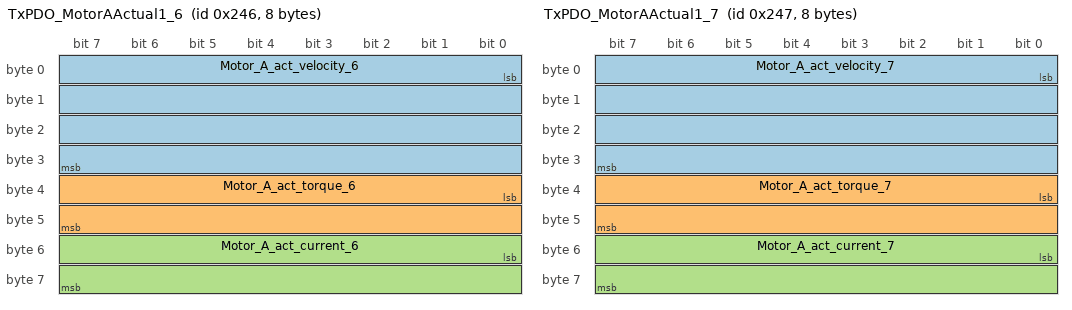
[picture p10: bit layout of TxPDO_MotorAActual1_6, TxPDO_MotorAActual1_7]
BO_ 582 TxPDO_MotorAActual1_6: 8 Inverters
 SG_ Motor_A_act_velocity_6 : 0|32@1- (6.103515625e-05,0) [-131072|131071.99994] "rpm" Vector__XXX
 SG_ Motor_A_act_torque_6 : 32|16@1- (0.1,0) [-3276.8|3276.7] "%" Vector__XXX
 SG_ Motor_A_act_current_6 : 48|16@1- (0.015625,0) [-512|511.984375] "A" Vector__XXX

BO_ 583 TxPDO_MotorAActual1_7: 8 Inverters
 SG_ Motor_A_act_velocity_7 : 0|32@1- (6.103515625e-05,0) [-131072|131071.99994] "rpm" Vector__XXX
 SG_ Motor_A_act_torque_7 : 32|16@1- (0.1,0) [-3276.8|3276.7] "%" Vector__XXX
 SG_ Motor_A_act_current_7 : 48|16@1- (0.015625,0) [-512|511.984375] "A" Vector__XXX

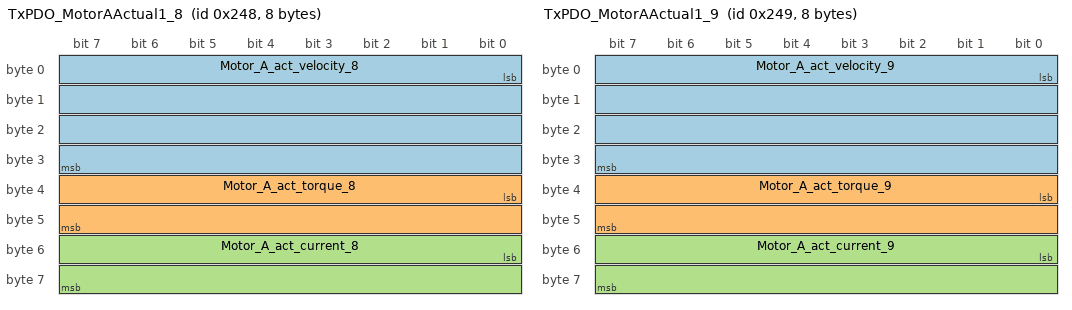
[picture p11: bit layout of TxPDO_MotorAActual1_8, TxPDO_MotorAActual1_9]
BO_ 584 TxPDO_MotorAActual1_8: 8 Inverters
 SG_ Motor_A_act_velocity_8 : 0|32@1- (6.103515625e-05,0) [-131072|131071.99994] "rpm" Vector__XXX
 SG_ Motor_A_act_torque_8 : 32|16@1- (0.1,0) [-3276.8|3276.7] "%" Vector__XXX
 SG_ Motor_A_act_current_8 : 48|16@1- (0.015625,0) [-512|511.984375] "A" Vector__XXX

BO_ 585 TxPDO_MotorAActual1_9: 8 Inverters
 SG_ Motor_A_act_velocity_9 : 0|32@1- (6.103515625e-05,0) [-131072|131071.99994] "rpm" Vector__XXX
 SG_ Motor_A_act_torque_9 : 32|16@1- (0.1,0) [-3276.8|3276.7] "%" Vector__XXX
 SG_ Motor_A_act_current_9 : 48|16@1- (0.015625,0) [-512|511.984375] "A" Vector__XXX

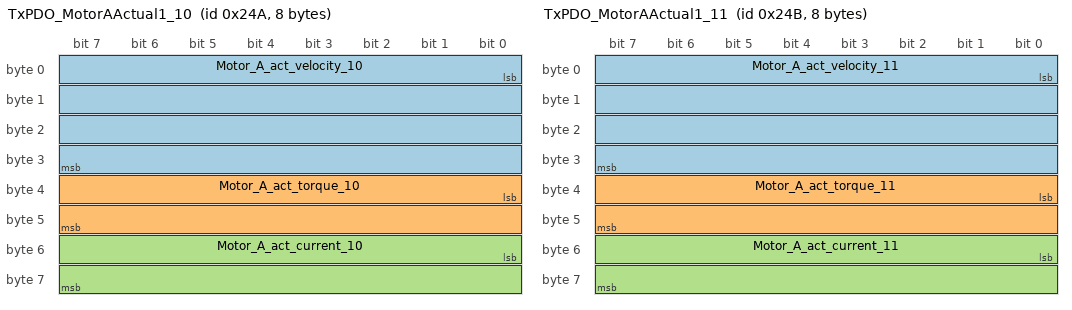
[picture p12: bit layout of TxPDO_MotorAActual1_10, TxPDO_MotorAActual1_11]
BO_ 586 TxPDO_MotorAActual1_10: 8 Inverters
 SG_ Motor_A_act_velocity_10 : 0|32@1- (6.103515625e-05,0) [-131072|131071.99994] "rpm" Vector__XXX
 SG_ Motor_A_act_torque_10 : 32|16@1- (0.1,0) [-3276.8|3276.7] "%" Vector__XXX
 SG_ Motor_A_act_current_10 : 48|16@1- (0.015625,0) [-512|511.984375] "A" Vector__XXX

BO_ 587 TxPDO_MotorAActual1_11: 8 Inverters
 SG_ Motor_A_act_velocity_11 : 0|32@1- (6.103515625e-05,0) [-131072|131071.99994] "rpm" Vector__XXX
 SG_ Motor_A_act_torque_11 : 32|16@1- (0.1,0) [-3276.8|3276.7] "%" Vector__XXX
 SG_ Motor_A_act_current_11 : 48|16@1- (0.015625,0) [-512|511.984375] "A" Vector__XXX

BO_ 588 TxPDO_MotorAActual1_12: 8 Inverters
 SG_ Motor_A_act_velocity_12 : 0|32@1- (6.103515625e-05,0) [-131072|131071.99994] "rpm" Vector__XXX
 SG_ Motor_A_act_torque_12 : 32|16@1- (0.1,0) [-3276.8|3276.7] "%" Vector__XXX
 SG_ Motor_A_act_current_12 : 48|16@1- (0.015625,0) [-512|511.984375] "A" Vector__XXX

BO_ 589 TxPDO_MotorAActual1_13: 8 Inverters
 SG_ Motor_A_act_velocity_13 : 0|32@1- (6.103515625e-05,0) [-131072|131071.99994] "rpm" Vector__XXX
 SG_ Motor_A_act_torque_13 : 32|16@1- (0.1,0) [-3276.8|3276.7] "%" Vector__XXX
 SG_ Motor_A_act_current_13 : 48|16@1- (0.015625,0) [-512|511.984375] "A" Vector__XXX

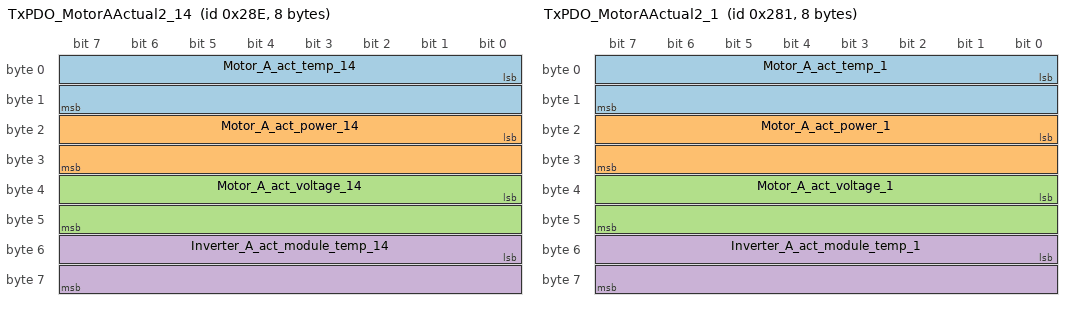
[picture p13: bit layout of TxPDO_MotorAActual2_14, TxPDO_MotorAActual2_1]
BO_ 654 TxPDO_MotorAActual2_14: 8 Inverters
 SG_ Motor_A_act_temp_14 : 0|16@1- (0.0625,0) [-2048|2047.9375] "°C" Vector__XXX
 SG_ Motor_A_act_power_14 : 16|16@1- (0.016,0) [-524.288|524.272] "kW" Vector__XXX
 SG_ Motor_A_act_voltage_14 : 32|16@1- (0.0625,0) [-2048|2047.9375] "V" Vector__XXX
 SG_ Inverter_A_act_module_temp_14 : 48|16@1- (0.0625,0) [-2048|2047.9375] "°C" Vector__XXX

BO_ 641 TxPDO_MotorAActual2_1: 8 Inverters
 SG_ Motor_A_act_temp_1 : 0|16@1- (0.0625,0) [-2048|2047.9375] "°C" Vector__XXX
 SG_ Motor_A_act_power_1 : 16|16@1- (0.016,0) [-524.288|524.272] "kW" Vector__XXX
 SG_ Motor_A_act_voltage_1 : 32|16@1- (0.0625,0) [-2048|2047.9375] "V" Vector__XXX
 SG_ Inverter_A_act_module_temp_1 : 48|16@1- (0.0625,0) [-2048|2047.9375] "°C" Vector__XXX

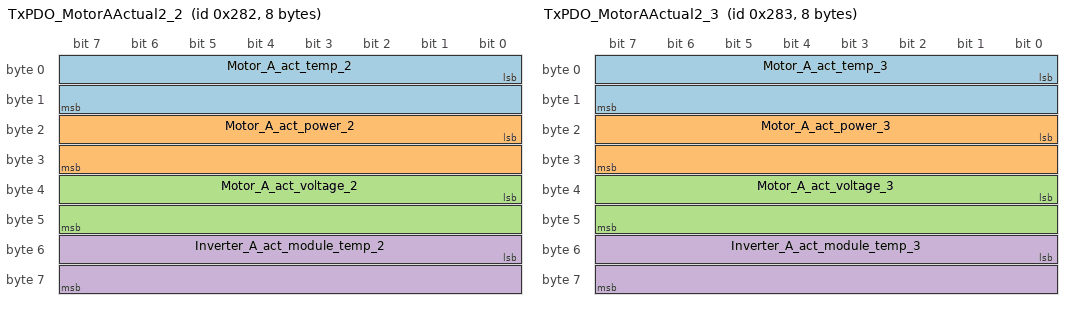
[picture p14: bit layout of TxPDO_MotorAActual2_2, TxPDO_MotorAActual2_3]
BO_ 642 TxPDO_MotorAActual2_2: 8 Inverters
 SG_ Motor_A_act_temp_2 : 0|16@1- (0.0625,0) [-2048|2047.9375] "°C" Vector__XXX
 SG_ Motor_A_act_power_2 : 16|16@1- (0.016,0) [-524.288|524.272] "kW" Vector__XXX
 SG_ Motor_A_act_voltage_2 : 32|16@1- (0.0625,0) [-2048|2047.9375] "V" Vector__XXX
 SG_ Inverter_A_act_module_temp_2 : 48|16@1- (0.0625,0) [-2048|2047.9375] "°C" Vector__XXX

BO_ 643 TxPDO_MotorAActual2_3: 8 Inverters
 SG_ Motor_A_act_temp_3 : 0|16@1- (0.0625,0) [-2048|2047.9375] "°C" Vector__XXX
 SG_ Motor_A_act_power_3 : 16|16@1- (0.016,0) [-524.288|524.272] "kW" Vector__XXX
 SG_ Motor_A_act_voltage_3 : 32|16@1- (0.0625,0) [-2048|2047.9375] "V" Vector__XXX
 SG_ Inverter_A_act_module_temp_3 : 48|16@1- (0.0625,0) [-2048|2047.9375] "°C" Vector__XXX

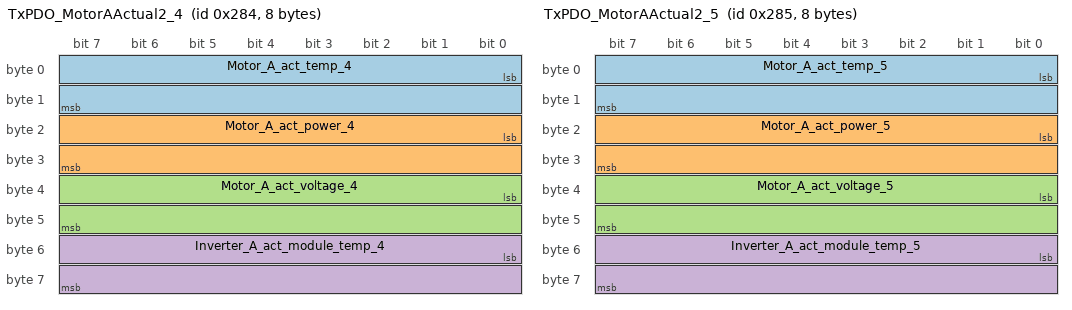
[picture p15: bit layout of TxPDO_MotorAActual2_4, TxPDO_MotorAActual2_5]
BO_ 644 TxPDO_MotorAActual2_4: 8 Inverters
 SG_ Motor_A_act_temp_4 : 0|16@1- (0.0625,0) [-2048|2047.9375] "°C" Vector__XXX
 SG_ Motor_A_act_power_4 : 16|16@1- (0.016,0) [-524.288|524.272] "kW" Vector__XXX
 SG_ Motor_A_act_voltage_4 : 32|16@1- (0.0625,0) [-2048|2047.9375] "V" Vector__XXX
 SG_ Inverter_A_act_module_temp_4 : 48|16@1- (0.0625,0) [-2048|2047.9375] "°C" Vector__XXX

BO_ 645 TxPDO_MotorAActual2_5: 8 Inverters
 SG_ Motor_A_act_temp_5 : 0|16@1- (0.0625,0) [-2048|2047.9375] "°C" Vector__XXX
 SG_ Motor_A_act_power_5 : 16|16@1- (0.016,0) [-524.288|524.272] "kW" Vector__XXX
 SG_ Motor_A_act_voltage_5 : 32|16@1- (0.0625,0) [-2048|2047.9375] "V" Vector__XXX
 SG_ Inverter_A_act_module_temp_5 : 48|16@1- (0.0625,0) [-2048|2047.9375] "°C" Vector__XXX

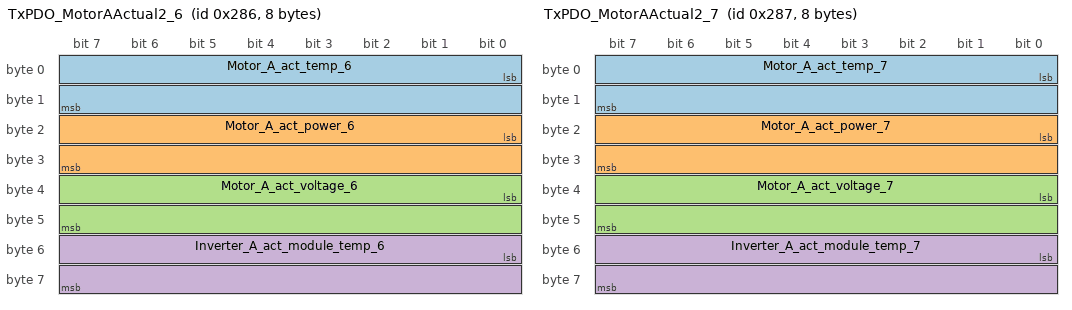
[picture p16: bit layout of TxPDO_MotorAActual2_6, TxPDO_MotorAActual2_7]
BO_ 646 TxPDO_MotorAActual2_6: 8 Inverters
 SG_ Motor_A_act_temp_6 : 0|16@1- (0.0625,0) [-2048|2047.9375] "°C" Vector__XXX
 SG_ Motor_A_act_power_6 : 16|16@1- (0.016,0) [-524.288|524.272] "kW" Vector__XXX
 SG_ Motor_A_act_voltage_6 : 32|16@1- (0.0625,0) [-2048|2047.9375] "V" Vector__XXX
 SG_ Inverter_A_act_module_temp_6 : 48|16@1- (0.0625,0) [-2048|2047.9375] "°C" Vector__XXX

BO_ 647 TxPDO_MotorAActual2_7: 8 Inverters
 SG_ Motor_A_act_temp_7 : 0|16@1- (0.0625,0) [-2048|2047.9375] "°C" Vector__XXX
 SG_ Motor_A_act_power_7 : 16|16@1- (0.016,0) [-524.288|524.272] "kW" Vector__XXX
 SG_ Motor_A_act_voltage_7 : 32|16@1- (0.0625,0) [-2048|2047.9375] "V" Vector__XXX
 SG_ Inverter_A_act_module_temp_7 : 48|16@1- (0.0625,0) [-2048|2047.9375] "°C" Vector__XXX

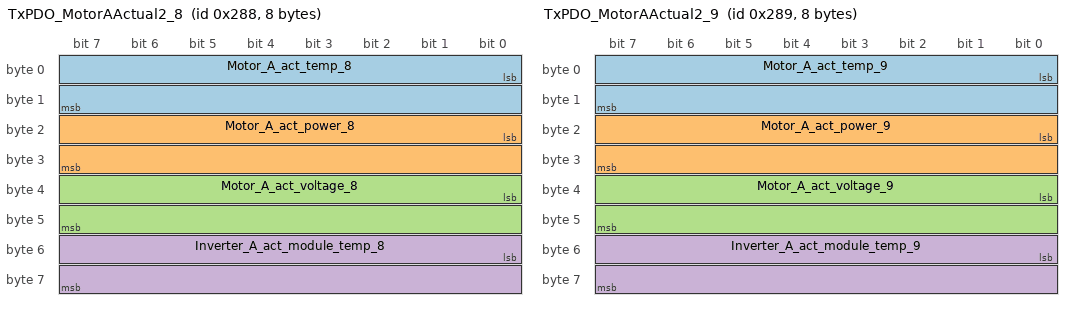
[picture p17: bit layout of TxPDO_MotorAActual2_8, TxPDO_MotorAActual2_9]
BO_ 648 TxPDO_MotorAActual2_8: 8 Inverters
 SG_ Motor_A_act_temp_8 : 0|16@1- (0.0625,0) [-2048|2047.9375] "°C" Vector__XXX
 SG_ Motor_A_act_power_8 : 16|16@1- (0.016,0) [-524.288|524.272] "kW" Vector__XXX
 SG_ Motor_A_act_voltage_8 : 32|16@1- (0.0625,0) [-2048|2047.9375] "V" Vector__XXX
 SG_ Inverter_A_act_module_temp_8 : 48|16@1- (0.0625,0) [-2048|2047.9375] "°C" Vector__XXX

BO_ 649 TxPDO_MotorAActual2_9: 8 Inverters
 SG_ Motor_A_act_temp_9 : 0|16@1- (0.0625,0) [-2048|2047.9375] "°C" Vector__XXX
 SG_ Motor_A_act_power_9 : 16|16@1- (0.016,0) [-524.288|524.272] "kW" Vector__XXX
 SG_ Motor_A_act_voltage_9 : 32|16@1- (0.0625,0) [-2048|2047.9375] "V" Vector__XXX
 SG_ Inverter_A_act_module_temp_9 : 48|16@1- (0.0625,0) [-2048|2047.9375] "°C" Vector__XXX

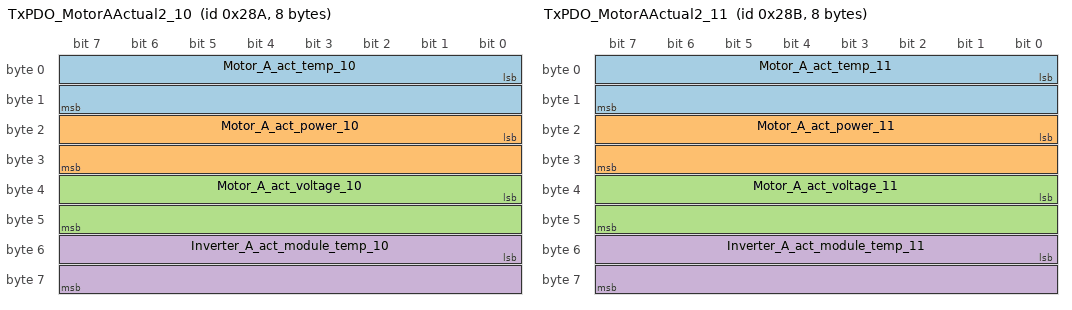
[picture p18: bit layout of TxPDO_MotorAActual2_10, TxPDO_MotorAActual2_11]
BO_ 650 TxPDO_MotorAActual2_10: 8 Inverters
 SG_ Motor_A_act_temp_10 : 0|16@1- (0.0625,0) [-2048|2047.9375] "°C" Vector__XXX
 SG_ Motor_A_act_power_10 : 16|16@1- (0.016,0) [-524.288|524.272] "kW" Vector__XXX
 SG_ Motor_A_act_voltage_10 : 32|16@1- (0.0625,0) [-2048|2047.9375] "V" Vector__XXX
 SG_ Inverter_A_act_module_temp_10 : 48|16@1- (0.0625,0) [-2048|2047.9375] "°C" Vector__XXX

BO_ 651 TxPDO_MotorAActual2_11: 8 Inverters
 SG_ Motor_A_act_temp_11 : 0|16@1- (0.0625,0) [-2048|2047.9375] "°C" Vector__XXX
 SG_ Motor_A_act_power_11 : 16|16@1- (0.016,0) [-524.288|524.272] "kW" Vector__XXX
 SG_ Motor_A_act_voltage_11 : 32|16@1- (0.0625,0) [-2048|2047.9375] "V" Vector__XXX
 SG_ Inverter_A_act_module_temp_11 : 48|16@1- (0.0625,0) [-2048|2047.9375] "°C" Vector__XXX

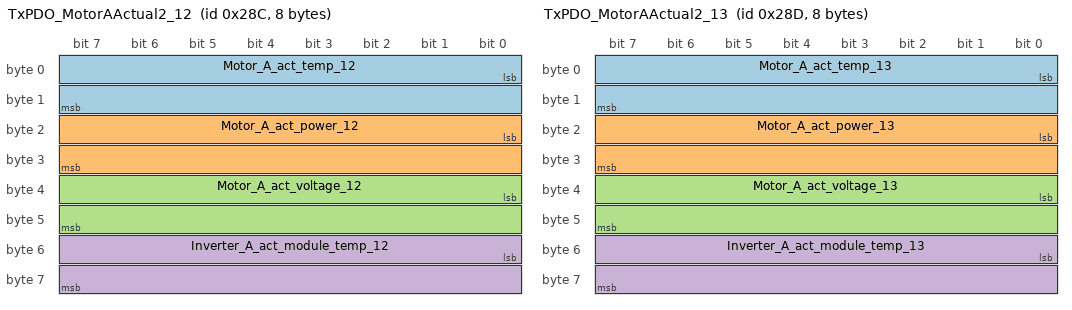
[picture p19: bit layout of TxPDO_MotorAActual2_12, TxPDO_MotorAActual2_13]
BO_ 652 TxPDO_MotorAActual2_12: 8 Inverters
 SG_ Motor_A_act_temp_12 : 0|16@1- (0.0625,0) [-2048|2047.9375] "°C" Vector__XXX
 SG_ Motor_A_act_power_12 : 16|16@1- (0.016,0) [-524.288|524.272] "kW" Vector__XXX
 SG_ Motor_A_act_voltage_12 : 32|16@1- (0.0625,0) [-2048|2047.9375] "V" Vector__XXX
 SG_ Inverter_A_act_module_temp_12 : 48|16@1- (0.0625,0) [-2048|2047.9375] "°C" Vector__XXX

BO_ 653 TxPDO_MotorAActual2_13: 8 Inverters
 SG_ Motor_A_act_temp_13 : 0|16@1- (0.0625,0) [-2048|2047.9375] "°C" Vector__XXX
 SG_ Motor_A_act_power_13 : 16|16@1- (0.016,0) [-524.288|524.272] "kW" Vector__XXX
 SG_ Motor_A_act_voltage_13 : 32|16@1- (0.0625,0) [-2048|2047.9375] "V" Vector__XXX
 SG_ Inverter_A_act_module_temp_13 : 48|16@1- (0.0625,0) [-2048|2047.9375] "°C" Vector__XXX

BO_ 718 TxPDO_InverterBStatus_14: 8 Inverters
 SG_ Inverter_B_Statusword_14 : 0|7@1+ (1,0) [0|127] "" Vector__XXX
 SG_ EVENTBUFFER_NEW_EVENT : 16|1@1+ (1,0) [0|1] "" Vector__XXX
 SG_ EVENTBUFFER_OVERFLOW : 17|1@1+ (1,0) [0|1] "" Vector__XXX
 SG_ POWERMODULE_TRIPZONE_OVERCURRE : 18|1@1+ (1,0) [0|1] "" Vector__XXX
 SG_ POWERMODULE_CURRENT_OFFSET_INI : 19|1@1+ (1,0) [0|1] "" Vector__XXX
 SG_ POWERMODULE_TEMPSENSOR_ERROR : 20|1@1+ (1,0) [0|1] "" Vector__XXX
 SG_ POWERMODULE_TEMPERATURE_WARNIN : 21|1@1+ (1,0) [0|1] "" Vector__XXX
 SG_ POWERMODULE_OVERTEMPERATURE : 22|1@1+ (1,0) [0|1] "" Vector__XXX
 SG_ POWERMODULE_IXT_FAULT : 23|1@1+ (1,0) [0|1] "" Vector__XXX
 SG_ POWERMODULE_SW_OVERCURRENT : 24|1@1+ (1,0) [0|1] "" Vector__XXX
 SG_ POWERMODULE_PATTERNDATA_INCONS : 25|1@1+ (1,0) [0|1] "" Vector__XXX
 SG_ DCBUS_TRIPZONE_OVERVOLTAGE : 26|1@1+ (1,0) [0|1] "" Vector__XXX
 SG_ DCBUS_SW_OVERVOLTAGE : 27|1@1+ (1,0) [0|1] "" Vector__XXX
 SG_ DCBUS_SW_UNDERVOLTAGE : 28|1@1+ (1,0) [0|1] "" Vector__XXX
 SG_ NEIGHBOUR_FAULT : 29|1@1+ (1,0) [0|1] "" Vector__XXX
 SG_ MOTOR_TEMPSENSOR_ERROR : 30|1@1+ (1,0) [0|1] "" Vector__XXX
 SG_ MOTOR_TEMPERATURE_WARNING : 31|1@1+ (1,0) [0|1] "" Vector__XXX
 SG_ MOTOR_OVERTEMPERATURE : 32|1@1+ (1,0) [0|1] "" Vector__XXX
 SG_ MOTOR_STATOR_FREQ_TO_HIGH : 33|1@1+ (1,0) [0|1] "" Vector__XXX
 SG_ SUPPLYVOLTAGE_ERROR : 34|1@1+ (1,0) [0|1] "" Vector__XXX
 SG_ RPDO_TIMEOUT : 35|1@1+ (1,0) [0|1] "" Vector__XXX
 SG_ NMT_NOT_OPERATIONAL : 36|1@1+ (1,0) [0|1] "" Vector__XXX
 SG_ TASKOVERRUN : 37|1@1+ (1,0) [0|1] "" Vector__XXX
 SG_ NETSYNC_ERROR : 38|1@1+ (1,0) [0|1] "" Vector__XXX
 SG_ POSDEVICE_SIGNAL_TO_LOW : 39|1@1+ (1,0) [0|1] "" Vector__XXX
 SG_ POSDEVICE_SIGNAL_TO_HIGH : 40|1@1+ (1,0) [0|1] "" Vector__XXX
 SG_ RESOLVER_CALIBRATION_FAILED : 41|1@1+ (1,0) [0|1] "" Vector__XXX
 SG_ SYSTEM_FAULT : 42|1@1+ (1,0) [0|1] "" Vector__XXX
 SG_ INTERLOCK_OPEN : 43|1@1+ (1,0) [0|1] "" Vector__XXX
 SG_ APPC_HAS_GATE_DRIVER_DISABLED : 44|1@1+ (1,0) [0|1] "" Vector__XXX
 SG_ MOTOR_STALL_ERROR : 45|1@1+ (1,0) [0|1] "" Vector__XXX
 SG_ AMBIENT_TEMPERATURE_WARNING : 46|1@1+ (1,0) [0|1] "" Vector__XXX
 SG_ AMBIENT_OVERTEMPERATURE : 47|1@1+ (1,0) [0|1] "" Vector__XXX
 SG_ AMBIENT_TEMPSENSOR_ERROR : 48|1@1+ (1,0) [0|1] "" Vector__XXX
 SG_ POWERMODULE_CLAMPING_TIMEOUT : 49|1@1+ (1,0) [0|1] "" Vector__XXX
 SG_ DCBUS_RIPPLE_TO_HIGH : 50|1@1+ (1,0) [0|1] "" Vector__XXX
 SG_ MOTOR_I2XT_WARNING : 51|1@1+ (1,0) [0|1] "" Vector__XXX
 SG_ MOTOR_I2XT_ERROR : 52|1@1+ (1,0) [0|1] "" Vector__XXX
 SG_ MOTOR_FIELDWEAKENING_ERROR : 53|1@1+ (1,0) [0|1] "" Vector__XXX
 SG_ INVALID_PARAMETER_COMBINATION : 54|1@1+ (1,0) [0|1] "" Vector__XXX
 SG_ PLUG_COVER_SENSOR_SIGNAL_LOW : 55|1@1+ (1,0) [0|1] "" Vector__XXX
 SG_ MOTOR_CONNECTION_TEST_FAILED : 56|1@1+ (1,0) [0|1] "" Vector__XXX
 SG_ POWERMODULE_IXT_WARNING : 57|1@1+ (1,0) [0|1] "" Vector__XXX
 SG_ ISOLATION_FAULT : 58|1@1+ (1,0) [0|1] "" Vector__XXX

BO_ 705 TxPDO_InverterBStatus_1: 8 Inverters
 SG_ Inverter_B_Statusword_1 : 0|7@1+ (1,0) [0|127] "" Vector__XXX
 SG_ EVENTBUFFER_NEW_EVENT : 16|1@1+ (1,0) [0|1] "" Vector__XXX
 SG_ EVENTBUFFER_OVERFLOW : 17|1@1+ (1,0) [0|1] "" Vector__XXX
 SG_ POWERMODULE_TRIPZONE_OVERCURRE : 18|1@1+ (1,0) [0|1] "" Vector__XXX
 SG_ POWERMODULE_CURRENT_OFFSET_INI : 19|1@1+ (1,0) [0|1] "" Vector__XXX
 SG_ POWERMODULE_TEMPSENSOR_ERROR : 20|1@1+ (1,0) [0|1] "" Vector__XXX
 SG_ POWERMODULE_TEMPERATURE_WARNIN : 21|1@1+ (1,0) [0|1] "" Vector__XXX
 SG_ POWERMODULE_OVERTEMPERATURE : 22|1@1+ (1,0) [0|1] "" Vector__XXX
 SG_ POWERMODULE_IXT_FAULT : 23|1@1+ (1,0) [0|1] "" Vector__XXX
 SG_ POWERMODULE_SW_OVERCURRENT : 24|1@1+ (1,0) [0|1] "" Vector__XXX
 SG_ POWERMODULE_PATTERNDATA_INCONS : 25|1@1+ (1,0) [0|1] "" Vector__XXX
 SG_ DCBUS_TRIPZONE_OVERVOLTAGE : 26|1@1+ (1,0) [0|1] "" Vector__XXX
 SG_ DCBUS_SW_OVERVOLTAGE : 27|1@1+ (1,0) [0|1] "" Vector__XXX
 SG_ DCBUS_SW_UNDERVOLTAGE : 28|1@1+ (1,0) [0|1] "" Vector__XXX
 SG_ NEIGHBOUR_FAULT : 29|1@1+ (1,0) [0|1] "" Vector__XXX
 SG_ MOTOR_TEMPSENSOR_ERROR : 30|1@1+ (1,0) [0|1] "" Vector__XXX
 SG_ MOTOR_TEMPERATURE_WARNING : 31|1@1+ (1,0) [0|1] "" Vector__XXX
 SG_ MOTOR_OVERTEMPERATURE : 32|1@1+ (1,0) [0|1] "" Vector__XXX
 SG_ MOTOR_STATOR_FREQ_TO_HIGH : 33|1@1+ (1,0) [0|1] "" Vector__XXX
 SG_ SUPPLYVOLTAGE_ERROR : 34|1@1+ (1,0) [0|1] "" Vector__XXX
 SG_ RPDO_TIMEOUT : 35|1@1+ (1,0) [0|1] "" Vector__XXX
 SG_ NMT_NOT_OPERATIONAL : 36|1@1+ (1,0) [0|1] "" Vector__XXX
 SG_ TASKOVERRUN : 37|1@1+ (1,0) [0|1] "" Vector__XXX
 SG_ NETSYNC_ERROR : 38|1@1+ (1,0) [0|1] "" Vector__XXX
 SG_ POSDEVICE_SIGNAL_TO_LOW : 39|1@1+ (1,0) [0|1] "" Vector__XXX
 SG_ POSDEVICE_SIGNAL_TO_HIGH : 40|1@1+ (1,0) [0|1] "" Vector__XXX
 SG_ RESOLVER_CALIBRATION_FAILED : 41|1@1+ (1,0) [0|1] "" Vector__XXX
 SG_ SYSTEM_FAULT : 42|1@1+ (1,0) [0|1] "" Vector__XXX
 SG_ INTERLOCK_OPEN : 43|1@1+ (1,0) [0|1] "" Vector__XXX
 SG_ APPC_HAS_GATE_DRIVER_DISABLED : 44|1@1+ (1,0) [0|1] "" Vector__XXX
 SG_ MOTOR_STALL_ERROR : 45|1@1+ (1,0) [0|1] "" Vector__XXX
 SG_ AMBIENT_TEMPERATURE_WARNING : 46|1@1+ (1,0) [0|1] "" Vector__XXX
 SG_ AMBIENT_OVERTEMPERATURE : 47|1@1+ (1,0) [0|1] "" Vector__XXX
 SG_ AMBIENT_TEMPSENSOR_ERROR : 48|1@1+ (1,0) [0|1] "" Vector__XXX
 SG_ POWERMODULE_CLAMPING_TIMEOUT : 49|1@1+ (1,0) [0|1] "" Vector__XXX
 SG_ DCBUS_RIPPLE_TO_HIGH : 50|1@1+ (1,0) [0|1] "" Vector__XXX
 SG_ MOTOR_I2XT_WARNING : 51|1@1+ (1,0) [0|1] "" Vector__XXX
 SG_ MOTOR_I2XT_ERROR : 52|1@1+ (1,0) [0|1] "" Vector__XXX
 SG_ MOTOR_FIELDWEAKENING_ERROR : 53|1@1+ (1,0) [0|1] "" Vector__XXX
 SG_ INVALID_PARAMETER_COMBINATION : 54|1@1+ (1,0) [0|1] "" Vector__XXX
 SG_ PLUG_COVER_SENSOR_SIGNAL_LOW : 55|1@1+ (1,0) [0|1] "" Vector__XXX
 SG_ MOTOR_CONNECTION_TEST_FAILED : 56|1@1+ (1,0) [0|1] "" Vector__XXX
 SG_ POWERMODULE_IXT_WARNING : 57|1@1+ (1,0) [0|1] "" Vector__XXX
 SG_ ISOLATION_FAULT : 58|1@1+ (1,0) [0|1] "" Vector__XXX

BO_ 706 TxPDO_InverterBStatus_2: 8 Inverters
 SG_ Inverter_B_Statusword_2 : 0|7@1+ (1,0) [0|127] "" Vector__XXX
 SG_ EVENTBUFFER_NEW_EVENT : 16|1@1+ (1,0) [0|1] "" Vector__XXX
 SG_ EVENTBUFFER_OVERFLOW : 17|1@1+ (1,0) [0|1] "" Vector__XXX
 SG_ POWERMODULE_TRIPZONE_OVERCURRE : 18|1@1+ (1,0) [0|1] "" Vector__XXX
 SG_ POWERMODULE_CURRENT_OFFSET_INI : 19|1@1+ (1,0) [0|1] "" Vector__XXX
 SG_ POWERMODULE_TEMPSENSOR_ERROR : 20|1@1+ (1,0) [0|1] "" Vector__XXX
 SG_ POWERMODULE_TEMPERATURE_WARNIN : 21|1@1+ (1,0) [0|1] "" Vector__XXX
 SG_ POWERMODULE_OVERTEMPERATURE : 22|1@1+ (1,0) [0|1] "" Vector__XXX
 SG_ POWERMODULE_IXT_FAULT : 23|1@1+ (1,0) [0|1] "" Vector__XXX
 SG_ POWERMODULE_SW_OVERCURRENT : 24|1@1+ (1,0) [0|1] "" Vector__XXX
 SG_ POWERMODULE_PATTERNDATA_INCONS : 25|1@1+ (1,0) [0|1] "" Vector__XXX
 SG_ DCBUS_TRIPZONE_OVERVOLTAGE : 26|1@1+ (1,0) [0|1] "" Vector__XXX
 SG_ DCBUS_SW_OVERVOLTAGE : 27|1@1+ (1,0) [0|1] "" Vector__XXX
 SG_ DCBUS_SW_UNDERVOLTAGE : 28|1@1+ (1,0) [0|1] "" Vector__XXX
 SG_ NEIGHBOUR_FAULT : 29|1@1+ (1,0) [0|1] "" Vector__XXX
 SG_ MOTOR_TEMPSENSOR_ERROR : 30|1@1+ (1,0) [0|1] "" Vector__XXX
 SG_ MOTOR_TEMPERATURE_WARNING : 31|1@1+ (1,0) [0|1] "" Vector__XXX
 SG_ MOTOR_OVERTEMPERATURE : 32|1@1+ (1,0) [0|1] "" Vector__XXX
 SG_ MOTOR_STATOR_FREQ_TO_HIGH : 33|1@1+ (1,0) [0|1] "" Vector__XXX
 SG_ SUPPLYVOLTAGE_ERROR : 34|1@1+ (1,0) [0|1] "" Vector__XXX
 SG_ RPDO_TIMEOUT : 35|1@1+ (1,0) [0|1] "" Vector__XXX
 SG_ NMT_NOT_OPERATIONAL : 36|1@1+ (1,0) [0|1] "" Vector__XXX
 SG_ TASKOVERRUN : 37|1@1+ (1,0) [0|1] "" Vector__XXX
 SG_ NETSYNC_ERROR : 38|1@1+ (1,0) [0|1] "" Vector__XXX
 SG_ POSDEVICE_SIGNAL_TO_LOW : 39|1@1+ (1,0) [0|1] "" Vector__XXX
 SG_ POSDEVICE_SIGNAL_TO_HIGH : 40|1@1+ (1,0) [0|1] "" Vector__XXX
 SG_ RESOLVER_CALIBRATION_FAILED : 41|1@1+ (1,0) [0|1] "" Vector__XXX
 SG_ SYSTEM_FAULT : 42|1@1+ (1,0) [0|1] "" Vector__XXX
 SG_ INTERLOCK_OPEN : 43|1@1+ (1,0) [0|1] "" Vector__XXX
 SG_ APPC_HAS_GATE_DRIVER_DISABLED : 44|1@1+ (1,0) [0|1] "" Vector__XXX
 SG_ MOTOR_STALL_ERROR : 45|1@1+ (1,0) [0|1] "" Vector__XXX
 SG_ AMBIENT_TEMPERATURE_WARNING : 46|1@1+ (1,0) [0|1] "" Vector__XXX
 SG_ AMBIENT_OVERTEMPERATURE : 47|1@1+ (1,0) [0|1] "" Vector__XXX
 SG_ AMBIENT_TEMPSENSOR_ERROR : 48|1@1+ (1,0) [0|1] "" Vector__XXX
 SG_ POWERMODULE_CLAMPING_TIMEOUT : 49|1@1+ (1,0) [0|1] "" Vector__XXX
 SG_ DCBUS_RIPPLE_TO_HIGH : 50|1@1+ (1,0) [0|1] "" Vector__XXX
 SG_ MOTOR_I2XT_WARNING : 51|1@1+ (1,0) [0|1] "" Vector__XXX
 SG_ MOTOR_I2XT_ERROR : 52|1@1+ (1,0) [0|1] "" Vector__XXX
 SG_ MOTOR_FIELDWEAKENING_ERROR : 53|1@1+ (1,0) [0|1] "" Vector__XXX
 SG_ INVALID_PARAMETER_COMBINATION : 54|1@1+ (1,0) [0|1] "" Vector__XXX
 SG_ PLUG_COVER_SENSOR_SIGNAL_LOW : 55|1@1+ (1,0) [0|1] "" Vector__XXX
 SG_ MOTOR_CONNECTION_TEST_FAILED : 56|1@1+ (1,0) [0|1] "" Vector__XXX
 SG_ POWERMODULE_IXT_WARNING : 57|1@1+ (1,0) [0|1] "" Vector__XXX
 SG_ ISOLATION_FAULT : 58|1@1+ (1,0) [0|1] "" Vector__XXX

BO_ 707 TxPDO_InverterBStatus_3: 8 Inverters
 SG_ Inverter_B_Statusword_3 : 0|7@1+ (1,0) [0|127] "" Vector__XXX
 SG_ EVENTBUFFER_NEW_EVENT : 16|1@1+ (1,0) [0|1] "" Vector__XXX
 SG_ EVENTBUFFER_OVERFLOW : 17|1@1+ (1,0) [0|1] "" Vector__XXX
 SG_ POWERMODULE_TRIPZONE_OVERCURRE : 18|1@1+ (1,0) [0|1] "" Vector__XXX
 SG_ POWERMODULE_CURRENT_OFFSET_INI : 19|1@1+ (1,0) [0|1] "" Vector__XXX
 SG_ POWERMODULE_TEMPSENSOR_ERROR : 20|1@1+ (1,0) [0|1] "" Vector__XXX
 SG_ POWERMODULE_TEMPERATURE_WARNIN : 21|1@1+ (1,0) [0|1] "" Vector__XXX
 SG_ POWERMODULE_OVERTEMPERATURE : 22|1@1+ (1,0) [0|1] "" Vector__XXX
 SG_ POWERMODULE_IXT_FAULT : 23|1@1+ (1,0) [0|1] "" Vector__XXX
 SG_ POWERMODULE_SW_OVERCURRENT : 24|1@1+ (1,0) [0|1] "" Vector__XXX
 SG_ POWERMODULE_PATTERNDATA_INCONS : 25|1@1+ (1,0) [0|1] "" Vector__XXX
 SG_ DCBUS_TRIPZONE_OVERVOLTAGE : 26|1@1+ (1,0) [0|1] "" Vector__XXX
 SG_ DCBUS_SW_OVERVOLTAGE : 27|1@1+ (1,0) [0|1] "" Vector__XXX
 SG_ DCBUS_SW_UNDERVOLTAGE : 28|1@1+ (1,0) [0|1] "" Vector__XXX
 SG_ NEIGHBOUR_FAULT : 29|1@1+ (1,0) [0|1] "" Vector__XXX
 SG_ MOTOR_TEMPSENSOR_ERROR : 30|1@1+ (1,0) [0|1] "" Vector__XXX
 SG_ MOTOR_TEMPERATURE_WARNING : 31|1@1+ (1,0) [0|1] "" Vector__XXX
 SG_ MOTOR_OVERTEMPERATURE : 32|1@1+ (1,0) [0|1] "" Vector__XXX
 SG_ MOTOR_STATOR_FREQ_TO_HIGH : 33|1@1+ (1,0) [0|1] "" Vector__XXX
 SG_ SUPPLYVOLTAGE_ERROR : 34|1@1+ (1,0) [0|1] "" Vector__XXX
 SG_ RPDO_TIMEOUT : 35|1@1+ (1,0) [0|1] "" Vector__XXX
 SG_ NMT_NOT_OPERATIONAL : 36|1@1+ (1,0) [0|1] "" Vector__XXX
 SG_ TASKOVERRUN : 37|1@1+ (1,0) [0|1] "" Vector__XXX
 SG_ NETSYNC_ERROR : 38|1@1+ (1,0) [0|1] "" Vector__XXX
 SG_ POSDEVICE_SIGNAL_TO_LOW : 39|1@1+ (1,0) [0|1] "" Vector__XXX
 SG_ POSDEVICE_SIGNAL_TO_HIGH : 40|1@1+ (1,0) [0|1] "" Vector__XXX
 SG_ RESOLVER_CALIBRATION_FAILED : 41|1@1+ (1,0) [0|1] "" Vector__XXX
 SG_ SYSTEM_FAULT : 42|1@1+ (1,0) [0|1] "" Vector__XXX
 SG_ INTERLOCK_OPEN : 43|1@1+ (1,0) [0|1] "" Vector__XXX
 SG_ APPC_HAS_GATE_DRIVER_DISABLED : 44|1@1+ (1,0) [0|1] "" Vector__XXX
 SG_ MOTOR_STALL_ERROR : 45|1@1+ (1,0) [0|1] "" Vector__XXX
 SG_ AMBIENT_TEMPERATURE_WARNING : 46|1@1+ (1,0) [0|1] "" Vector__XXX
 SG_ AMBIENT_OVERTEMPERATURE : 47|1@1+ (1,0) [0|1] "" Vector__XXX
 SG_ AMBIENT_TEMPSENSOR_ERROR : 48|1@1+ (1,0) [0|1] "" Vector__XXX
 SG_ POWERMODULE_CLAMPING_TIMEOUT : 49|1@1+ (1,0) [0|1] "" Vector__XXX
 SG_ DCBUS_RIPPLE_TO_HIGH : 50|1@1+ (1,0) [0|1] "" Vector__XXX
 SG_ MOTOR_I2XT_WARNING : 51|1@1+ (1,0) [0|1] "" Vector__XXX
 SG_ MOTOR_I2XT_ERROR : 52|1@1+ (1,0) [0|1] "" Vector__XXX
 SG_ MOTOR_FIELDWEAKENING_ERROR : 53|1@1+ (1,0) [0|1] "" Vector__XXX
 SG_ INVALID_PARAMETER_COMBINATION : 54|1@1+ (1,0) [0|1] "" Vector__XXX
 SG_ PLUG_COVER_SENSOR_SIGNAL_LOW : 55|1@1+ (1,0) [0|1] "" Vector__XXX
 SG_ MOTOR_CONNECTION_TEST_FAILED : 56|1@1+ (1,0) [0|1] "" Vector__XXX
 SG_ POWERMODULE_IXT_WARNING : 57|1@1+ (1,0) [0|1] "" Vector__XXX
 SG_ ISOLATION_FAULT : 58|1@1+ (1,0) [0|1] "" Vector__XXX

CM_ BO_ 3221225472 "This is a message for not used signals, created by Vector CANdb++ DBC OLE DB Provider.";
BA_DEF_ BU_  "Manufacturer" STRING ;
BA_DEF_ BU_  "ILUsed" ENUM  "No","Yes";
BA_DEF_ BO_  "NmMessage" ENUM  "no","yes";
BA_DEF_ BO_  "GenMsgILSupport" ENUM  "No","Yes";
BA_DEF_ BU_  "NmNode" ENUM  "no","yes";
BA_DEF_  "NmBaseAddress" HEX 1024 1087;
BA_DEF_  "BusType" STRING ;
BA_DEF_ BO_  "GenMsgSendType" ENUM  "Cyclic","NotUsed","NotUsed","NotUsed","NotUsed","Cyclic","NotUsed","IfActive","NoMsgSendType","NotUsed","vector_leerstring";
BA_DEF_ SG_  "GenSigSendType" ENUM  "Cyclic","OnWrite","OnWriteWithRepetition","OnChange","OnChangeWithRepetition","IfActive","IfActiveWithRepetition","NoSigSendType","NotUsed","NotUsed","NotUsed","NotUsed","NotUsed";
BA_DEF_ SG_  "GenSigStartValue" FLOAT 0 1215752192;
BA_DEF_DEF_  "Manufacturer" "Isabellenhuette";
BA_DEF_DEF_  "ILUsed" "Yes";
BA_DEF_DEF_  "NmMessage" "no";
BA_DEF_DEF_  "GenMsgILSupport" "Yes";
BA_DEF_DEF_  "NmNode" "no";
BA_DEF_DEF_  "NmBaseAddress" 1024;
BA_DEF_DEF_  "BusType" "CAN";
BA_DEF_DEF_  "GenMsgSendType" "NoMsgSendType";
BA_DEF_DEF_  "GenSigSendType" "OnWrite";
BA_DEF_DEF_  "GenSigStartValue" 0;
BA_ "NmNode" BU_ IVT_Mod 1;
VAL_ 462 Inverter_A_Statusword_14 0 "NotReadyToSwitchOn" 64 "SwitchOnDisabled" 80 "SwitchOnDisabled" 96 "SwitchOnDisabled" 112 "SwitchOnDisabled" 33 "ReadyToSwitchOn" 49 "ReadyToSwitchOn" 35 "SwitchedOn" 51 "SwitchedOn" 39 "OperationEnabled" 55 "OperationEnabled" 7 "QuickStopActive" 23 "QuickStopActive" 15 "FaultReactionActive" 31 "FaultReactionActive" 47 "FaultReactionActive" 63 "FaultReactionActive" 8 "Fault" 24 "Fault" 40 "Fault" 56 "Fault" ;
VAL_ 462 EVENTBUFFER_NEW_EVENT 0 "no" 1 "yes" ;
VAL_ 462 EVENTBUFFER_OVERFLOW 0 "no" 1 "yes" ;
VAL_ 462 POWERMODULE_TRIPZONE_OVERCURRE 0 "no" 1 "yes" ;
VAL_ 462 POWERMODULE_CURRENT_OFFSET_INI 0 "no" 1 "yes" ;
VAL_ 462 POWERMODULE_TEMPSENSOR_ERROR 0 "no" 1 "yes" ;
VAL_ 462 POWERMODULE_TEMPERATURE_WARNIN 0 "no" 1 "yes" ;
VAL_ 462 POWERMODULE_OVERTEMPERATURE 0 "no" 1 "yes" ;
VAL_ 462 POWERMODULE_IXT_FAULT 0 "no" 1 "yes" ;
VAL_ 462 POWERMODULE_SW_OVERCURRENT 0 "no" 1 "yes" ;
VAL_ 462 POWERMODULE_PATTERNDATA_INCONS 0 "no" 1 "yes" ;
VAL_ 462 DCBUS_TRIPZONE_OVERVOLTAGE 0 "no" 1 "yes" ;
VAL_ 462 DCBUS_SW_OVERVOLTAGE 0 "no" 1 "yes" ;
VAL_ 462 DCBUS_SW_UNDERVOLTAGE 0 "no" 1 "yes" ;
VAL_ 462 NEIGHBOUR_FAULT 0 "no" 1 "yes" ;
VAL_ 462 MOTOR_TEMPSENSOR_ERROR 0 "no" 1 "yes" ;
VAL_ 462 MOTOR_TEMPERATURE_WARNING 0 "no" 1 "yes" ;
VAL_ 462 MOTOR_OVERTEMPERATURE 0 "no" 1 "yes" ;
VAL_ 462 MOTOR_STATOR_FREQ_TO_HIGH 0 "no" 1 "yes" ;
VAL_ 462 SUPPLYVOLTAGE_ERROR 0 "no" 1 "yes" ;
VAL_ 462 RPDO_TIMEOUT 0 "no" 1 "yes" ;
VAL_ 462 NMT_NOT_OPERATIONAL 0 "no" 1 "yes" ;
VAL_ 462 TASKOVERRUN 0 "no" 1 "yes" ;
VAL_ 462 NETSYNC_ERROR 0 "no" 1 "yes" ;
VAL_ 462 POSDEVICE_SIGNAL_TO_LOW 0 "no" 1 "yes" ;
VAL_ 462 POSDEVICE_SIGNAL_TO_HIGH 0 "no" 1 "yes" ;
VAL_ 462 RESOLVER_CALIBRATION_FAILED 0 "no" 1 "yes" ;
VAL_ 462 SYSTEM_FAULT 0 "no" 1 "yes" ;
VAL_ 462 INTERLOCK_OPEN 0 "no" 1 "yes" ;
VAL_ 462 APPC_HAS_GATE_DRIVER_DISABLED 0 "no" 1 "yes" ;
VAL_ 462 MOTOR_STALL_ERROR 0 "no" 1 "yes" ;
VAL_ 462 AMBIENT_TEMPERATURE_WARNING 0 "no" 1 "yes" ;
VAL_ 462 AMBIENT_OVERTEMPERATURE 0 "no" 1 "yes" ;
VAL_ 462 AMBIENT_TEMPSENSOR_ERROR 0 "no" 1 "yes" ;
VAL_ 462 POWERMODULE_CLAMPING_TIMEOUT 0 "no" 1 "yes" ;
VAL_ 462 DCBUS_RIPPLE_TO_HIGH 0 "no" 1 "yes" ;
VAL_ 462 MOTOR_I2XT_WARNING 0 "no" 1 "yes" ;
VAL_ 462 MOTOR_I2XT_ERROR 0 "no" 1 "yes" ;
VAL_ 462 MOTOR_FIELDWEAKENING_ERROR 0 "no" 1 "yes" ;
VAL_ 462 INVALID_PARAMETER_COMBINATION 0 "no" 1 "yes" ;
VAL_ 462 PLUG_COVER_SENSOR_SIGNAL_LOW 0 "no" 1 "yes" ;
VAL_ 462 MOTOR_CONNECTION_TEST_FAILED 0 "no" 1 "yes" ;
VAL_ 462 POWERMODULE_IXT_WARNING 0 "no" 1 "yes" ;
VAL_ 462 ISOLATION_FAULT 0 "no" 1 "yes" ;
VAL_ 449 Inverter_A_Statusword_1 0 "NotReadyToSwitchOn" 64 "SwitchOnDisabled" 80 "SwitchOnDisabled" 96 "SwitchOnDisabled" 112 "SwitchOnDisabled" 33 "ReadyToSwitchOn" 49 "ReadyToSwitchOn" 35 "SwitchedOn" 51 "SwitchedOn" 39 "OperationEnabled" 55 "OperationEnabled" 7 "QuickStopActive" 23 "QuickStopActive" 15 "FaultReactionActive" 31 "FaultReactionActive" 47 "FaultReactionActive" 63 "FaultReactionActive" 8 "Fault" 24 "Fault" 40 "Fault" 56 "Fault" ;
VAL_ 449 EVENTBUFFER_NEW_EVENT 0 "no" 1 "yes" ;
VAL_ 449 EVENTBUFFER_OVERFLOW 0 "no" 1 "yes" ;
VAL_ 449 POWERMODULE_TRIPZONE_OVERCURRE 0 "no" 1 "yes" ;
VAL_ 449 POWERMODULE_CURRENT_OFFSET_INI 0 "no" 1 "yes" ;
VAL_ 449 POWERMODULE_TEMPSENSOR_ERROR 0 "no" 1 "yes" ;
VAL_ 449 POWERMODULE_TEMPERATURE_WARNIN 0 "no" 1 "yes" ;
VAL_ 449 POWERMODULE_OVERTEMPERATURE 0 "no" 1 "yes" ;
VAL_ 449 POWERMODULE_IXT_FAULT 0 "no" 1 "yes" ;
VAL_ 449 POWERMODULE_SW_OVERCURRENT 0 "no" 1 "yes" ;
VAL_ 449 POWERMODULE_PATTERNDATA_INCONS 0 "no" 1 "yes" ;
VAL_ 449 DCBUS_TRIPZONE_OVERVOLTAGE 0 "no" 1 "yes" ;
VAL_ 449 DCBUS_SW_OVERVOLTAGE 0 "no" 1 "yes" ;
VAL_ 449 DCBUS_SW_UNDERVOLTAGE 0 "no" 1 "yes" ;
VAL_ 449 NEIGHBOUR_FAULT 0 "no" 1 "yes" ;
VAL_ 449 MOTOR_TEMPSENSOR_ERROR 0 "no" 1 "yes" ;
VAL_ 449 MOTOR_TEMPERATURE_WARNING 0 "no" 1 "yes" ;
VAL_ 449 MOTOR_OVERTEMPERATURE 0 "no" 1 "yes" ;
VAL_ 449 MOTOR_STATOR_FREQ_TO_HIGH 0 "no" 1 "yes" ;
VAL_ 449 SUPPLYVOLTAGE_ERROR 0 "no" 1 "yes" ;
VAL_ 449 RPDO_TIMEOUT 0 "no" 1 "yes" ;
VAL_ 449 NMT_NOT_OPERATIONAL 0 "no" 1 "yes" ;
VAL_ 449 TASKOVERRUN 0 "no" 1 "yes" ;
VAL_ 449 NETSYNC_ERROR 0 "no" 1 "yes" ;
VAL_ 449 POSDEVICE_SIGNAL_TO_LOW 0 "no" 1 "yes" ;
VAL_ 449 POSDEVICE_SIGNAL_TO_HIGH 0 "no" 1 "yes" ;
VAL_ 449 RESOLVER_CALIBRATION_FAILED 0 "no" 1 "yes" ;
VAL_ 449 SYSTEM_FAULT 0 "no" 1 "yes" ;
VAL_ 449 INTERLOCK_OPEN 0 "no" 1 "yes" ;
VAL_ 449 APPC_HAS_GATE_DRIVER_DISABLED 0 "no" 1 "yes" ;
VAL_ 449 MOTOR_STALL_ERROR 0 "no" 1 "yes" ;
VAL_ 449 AMBIENT_TEMPERATURE_WARNING 0 "no" 1 "yes" ;
VAL_ 449 AMBIENT_OVERTEMPERATURE 0 "no" 1 "yes" ;
VAL_ 449 AMBIENT_TEMPSENSOR_ERROR 0 "no" 1 "yes" ;
VAL_ 449 POWERMODULE_CLAMPING_TIMEOUT 0 "no" 1 "yes" ;
VAL_ 449 DCBUS_RIPPLE_TO_HIGH 0 "no" 1 "yes" ;
VAL_ 449 MOTOR_I2XT_WARNING 0 "no" 1 "yes" ;
VAL_ 449 MOTOR_I2XT_ERROR 0 "no" 1 "yes" ;
VAL_ 449 MOTOR_FIELDWEAKENING_ERROR 0 "no" 1 "yes" ;
VAL_ 449 INVALID_PARAMETER_COMBINATION 0 "no" 1 "yes" ;
VAL_ 449 PLUG_COVER_SENSOR_SIGNAL_LOW 0 "no" 1 "yes" ;
VAL_ 449 MOTOR_CONNECTION_TEST_FAILED 0 "no" 1 "yes" ;
VAL_ 449 POWERMODULE_IXT_WARNING 0 "no" 1 "yes" ;
VAL_ 449 ISOLATION_FAULT 0 "no" 1 "yes" ;
VAL_ 450 Inverter_A_Statusword_2 0 "NotReadyToSwitchOn" 64 "SwitchOnDisabled" 80 "SwitchOnDisabled" 96 "SwitchOnDisabled" 112 "SwitchOnDisabled" 33 "ReadyToSwitchOn" 49 "ReadyToSwitchOn" 35 "SwitchedOn" 51 "SwitchedOn" 39 "OperationEnabled" 55 "OperationEnabled" 7 "QuickStopActive" 23 "QuickStopActive" 15 "FaultReactionActive" 31 "FaultReactionActive" 47 "FaultReactionActive" 63 "FaultReactionActive" 8 "Fault" 24 "Fault" 40 "Fault" 56 "Fault" ;
VAL_ 450 EVENTBUFFER_NEW_EVENT 0 "no" 1 "yes" ;
VAL_ 450 EVENTBUFFER_OVERFLOW 0 "no" 1 "yes" ;
VAL_ 450 POWERMODULE_TRIPZONE_OVERCURRE 0 "no" 1 "yes" ;
VAL_ 450 POWERMODULE_CURRENT_OFFSET_INI 0 "no" 1 "yes" ;
VAL_ 450 POWERMODULE_TEMPSENSOR_ERROR 0 "no" 1 "yes" ;
VAL_ 450 POWERMODULE_TEMPERATURE_WARNIN 0 "no" 1 "yes" ;
VAL_ 450 POWERMODULE_OVERTEMPERATURE 0 "no" 1 "yes" ;
VAL_ 450 POWERMODULE_IXT_FAULT 0 "no" 1 "yes" ;
VAL_ 450 POWERMODULE_SW_OVERCURRENT 0 "no" 1 "yes" ;
VAL_ 450 POWERMODULE_PATTERNDATA_INCONS 0 "no" 1 "yes" ;
VAL_ 450 DCBUS_TRIPZONE_OVERVOLTAGE 0 "no" 1 "yes" ;
VAL_ 450 DCBUS_SW_OVERVOLTAGE 0 "no" 1 "yes" ;
VAL_ 450 DCBUS_SW_UNDERVOLTAGE 0 "no" 1 "yes" ;
VAL_ 450 NEIGHBOUR_FAULT 0 "no" 1 "yes" ;
VAL_ 450 MOTOR_TEMPSENSOR_ERROR 0 "no" 1 "yes" ;
VAL_ 450 MOTOR_TEMPERATURE_WARNING 0 "no" 1 "yes" ;
VAL_ 450 MOTOR_OVERTEMPERATURE 0 "no" 1 "yes" ;
VAL_ 450 MOTOR_STATOR_FREQ_TO_HIGH 0 "no" 1 "yes" ;
VAL_ 450 SUPPLYVOLTAGE_ERROR 0 "no" 1 "yes" ;
VAL_ 450 RPDO_TIMEOUT 0 "no" 1 "yes" ;
VAL_ 450 NMT_NOT_OPERATIONAL 0 "no" 1 "yes" ;
VAL_ 450 TASKOVERRUN 0 "no" 1 "yes" ;
VAL_ 450 NETSYNC_ERROR 0 "no" 1 "yes" ;
VAL_ 450 POSDEVICE_SIGNAL_TO_LOW 0 "no" 1 "yes" ;
VAL_ 450 POSDEVICE_SIGNAL_TO_HIGH 0 "no" 1 "yes" ;
VAL_ 450 RESOLVER_CALIBRATION_FAILED 0 "no" 1 "yes" ;
VAL_ 450 SYSTEM_FAULT 0 "no" 1 "yes" ;
VAL_ 450 INTERLOCK_OPEN 0 "no" 1 "yes" ;
VAL_ 450 APPC_HAS_GATE_DRIVER_DISABLED 0 "no" 1 "yes" ;
VAL_ 450 MOTOR_STALL_ERROR 0 "no" 1 "yes" ;
VAL_ 450 AMBIENT_TEMPERATURE_WARNING 0 "no" 1 "yes" ;
VAL_ 450 AMBIENT_OVERTEMPERATURE 0 "no" 1 "yes" ;
VAL_ 450 AMBIENT_TEMPSENSOR_ERROR 0 "no" 1 "yes" ;
VAL_ 450 POWERMODULE_CLAMPING_TIMEOUT 0 "no" 1 "yes" ;
VAL_ 450 DCBUS_RIPPLE_TO_HIGH 0 "no" 1 "yes" ;
VAL_ 450 MOTOR_I2XT_WARNING 0 "no" 1 "yes" ;
VAL_ 450 MOTOR_I2XT_ERROR 0 "no" 1 "yes" ;
VAL_ 450 MOTOR_FIELDWEAKENING_ERROR 0 "no" 1 "yes" ;
VAL_ 450 INVALID_PARAMETER_COMBINATION 0 "no" 1 "yes" ;
VAL_ 450 PLUG_COVER_SENSOR_SIGNAL_LOW 0 "no" 1 "yes" ;
VAL_ 450 MOTOR_CONNECTION_TEST_FAILED 0 "no" 1 "yes" ;
VAL_ 450 POWERMODULE_IXT_WARNING 0 "no" 1 "yes" ;
VAL_ 450 ISOLATION_FAULT 0 "no" 1 "yes" ;
VAL_ 451 Inverter_A_Statusword_3 0 "NotReadyToSwitchOn" 64 "SwitchOnDisabled" 80 "SwitchOnDisabled" 96 "SwitchOnDisabled" 112 "SwitchOnDisabled" 33 "ReadyToSwitchOn" 49 "ReadyToSwitchOn" 35 "SwitchedOn" 51 "SwitchedOn" 39 "OperationEnabled" 55 "OperationEnabled" 7 "QuickStopActive" 23 "QuickStopActive" 15 "FaultReactionActive" 31 "FaultReactionActive" 47 "FaultReactionActive" 63 "FaultReactionActive" 8 "Fault" 24 "Fault" 40 "Fault" 56 "Fault" ;
VAL_ 451 EVENTBUFFER_NEW_EVENT 0 "no" 1 "yes" ;
VAL_ 451 EVENTBUFFER_OVERFLOW 0 "no" 1 "yes" ;
VAL_ 451 POWERMODULE_TRIPZONE_OVERCURRE 0 "no" 1 "yes" ;
VAL_ 451 POWERMODULE_CURRENT_OFFSET_INI 0 "no" 1 "yes" ;
VAL_ 451 POWERMODULE_TEMPSENSOR_ERROR 0 "no" 1 "yes" ;
VAL_ 451 POWERMODULE_TEMPERATURE_WARNIN 0 "no" 1 "yes" ;
VAL_ 451 POWERMODULE_OVERTEMPERATURE 0 "no" 1 "yes" ;
VAL_ 451 POWERMODULE_IXT_FAULT 0 "no" 1 "yes" ;
VAL_ 451 POWERMODULE_SW_OVERCURRENT 0 "no" 1 "yes" ;
VAL_ 451 POWERMODULE_PATTERNDATA_INCONS 0 "no" 1 "yes" ;
VAL_ 451 DCBUS_TRIPZONE_OVERVOLTAGE 0 "no" 1 "yes" ;
VAL_ 451 DCBUS_SW_OVERVOLTAGE 0 "no" 1 "yes" ;
VAL_ 451 DCBUS_SW_UNDERVOLTAGE 0 "no" 1 "yes" ;
VAL_ 451 NEIGHBOUR_FAULT 0 "no" 1 "yes" ;
VAL_ 451 MOTOR_TEMPSENSOR_ERROR 0 "no" 1 "yes" ;
VAL_ 451 MOTOR_TEMPERATURE_WARNING 0 "no" 1 "yes" ;
VAL_ 451 MOTOR_OVERTEMPERATURE 0 "no" 1 "yes" ;
VAL_ 451 MOTOR_STATOR_FREQ_TO_HIGH 0 "no" 1 "yes" ;
VAL_ 451 SUPPLYVOLTAGE_ERROR 0 "no" 1 "yes" ;
VAL_ 451 RPDO_TIMEOUT 0 "no" 1 "yes" ;
VAL_ 451 NMT_NOT_OPERATIONAL 0 "no" 1 "yes" ;
VAL_ 451 TASKOVERRUN 0 "no" 1 "yes" ;
VAL_ 451 NETSYNC_ERROR 0 "no" 1 "yes" ;
VAL_ 451 POSDEVICE_SIGNAL_TO_LOW 0 "no" 1 "yes" ;
VAL_ 451 POSDEVICE_SIGNAL_TO_HIGH 0 "no" 1 "yes" ;
VAL_ 451 RESOLVER_CALIBRATION_FAILED 0 "no" 1 "yes" ;
VAL_ 451 SYSTEM_FAULT 0 "no" 1 "yes" ;
VAL_ 451 INTERLOCK_OPEN 0 "no" 1 "yes" ;
VAL_ 451 APPC_HAS_GATE_DRIVER_DISABLED 0 "no" 1 "yes" ;
VAL_ 451 MOTOR_STALL_ERROR 0 "no" 1 "yes" ;
VAL_ 451 AMBIENT_TEMPERATURE_WARNING 0 "no" 1 "yes" ;
VAL_ 451 AMBIENT_OVERTEMPERATURE 0 "no" 1 "yes" ;
VAL_ 451 AMBIENT_TEMPSENSOR_ERROR 0 "no" 1 "yes" ;
VAL_ 451 POWERMODULE_CLAMPING_TIMEOUT 0 "no" 1 "yes" ;
VAL_ 451 DCBUS_RIPPLE_TO_HIGH 0 "no" 1 "yes" ;
VAL_ 451 MOTOR_I2XT_WARNING 0 "no" 1 "yes" ;
VAL_ 451 MOTOR_I2XT_ERROR 0 "no" 1 "yes" ;
VAL_ 451 MOTOR_FIELDWEAKENING_ERROR 0 "no" 1 "yes" ;
VAL_ 451 INVALID_PARAMETER_COMBINATION 0 "no" 1 "yes" ;
VAL_ 451 PLUG_COVER_SENSOR_SIGNAL_LOW 0 "no" 1 "yes" ;
VAL_ 451 MOTOR_CONNECTION_TEST_FAILED 0 "no" 1 "yes" ;
VAL_ 451 POWERMODULE_IXT_WARNING 0 "no" 1 "yes" ;
VAL_ 451 ISOLATION_FAULT 0 "no" 1 "yes" ;
VAL_ 452 Inverter_A_Statusword_4 0 "NotReadyToSwitchOn" 64 "SwitchOnDisabled" 80 "SwitchOnDisabled" 96 "SwitchOnDisabled" 112 "SwitchOnDisabled" 33 "ReadyToSwitchOn" 49 "ReadyToSwitchOn" 35 "SwitchedOn" 51 "SwitchedOn" 39 "OperationEnabled" 55 "OperationEnabled" 7 "QuickStopActive" 23 "QuickStopActive" 15 "FaultReactionActive" 31 "FaultReactionActive" 47 "FaultReactionActive" 63 "FaultReactionActive" 8 "Fault" 24 "Fault" 40 "Fault" 56 "Fault" ;
VAL_ 452 EVENTBUFFER_NEW_EVENT 0 "no" 1 "yes" ;
VAL_ 452 EVENTBUFFER_OVERFLOW 0 "no" 1 "yes" ;
VAL_ 452 POWERMODULE_TRIPZONE_OVERCURRE 0 "no" 1 "yes" ;
VAL_ 452 POWERMODULE_CURRENT_OFFSET_INI 0 "no" 1 "yes" ;
VAL_ 452 POWERMODULE_TEMPSENSOR_ERROR 0 "no" 1 "yes" ;
VAL_ 452 POWERMODULE_TEMPERATURE_WARNIN 0 "no" 1 "yes" ;
VAL_ 452 POWERMODULE_OVERTEMPERATURE 0 "no" 1 "yes" ;
VAL_ 452 POWERMODULE_IXT_FAULT 0 "no" 1 "yes" ;
VAL_ 452 POWERMODULE_SW_OVERCURRENT 0 "no" 1 "yes" ;
VAL_ 452 POWERMODULE_PATTERNDATA_INCONS 0 "no" 1 "yes" ;
VAL_ 452 DCBUS_TRIPZONE_OVERVOLTAGE 0 "no" 1 "yes" ;
VAL_ 452 DCBUS_SW_OVERVOLTAGE 0 "no" 1 "yes" ;
VAL_ 452 DCBUS_SW_UNDERVOLTAGE 0 "no" 1 "yes" ;
VAL_ 452 NEIGHBOUR_FAULT 0 "no" 1 "yes" ;
VAL_ 452 MOTOR_TEMPSENSOR_ERROR 0 "no" 1 "yes" ;
VAL_ 452 MOTOR_TEMPERATURE_WARNING 0 "no" 1 "yes" ;
VAL_ 452 MOTOR_OVERTEMPERATURE 0 "no" 1 "yes" ;
VAL_ 452 MOTOR_STATOR_FREQ_TO_HIGH 0 "no" 1 "yes" ;
VAL_ 452 SUPPLYVOLTAGE_ERROR 0 "no" 1 "yes" ;
VAL_ 452 RPDO_TIMEOUT 0 "no" 1 "yes" ;
VAL_ 452 NMT_NOT_OPERATIONAL 0 "no" 1 "yes" ;
VAL_ 452 TASKOVERRUN 0 "no" 1 "yes" ;
VAL_ 452 NETSYNC_ERROR 0 "no" 1 "yes" ;
VAL_ 452 POSDEVICE_SIGNAL_TO_LOW 0 "no" 1 "yes" ;
VAL_ 452 POSDEVICE_SIGNAL_TO_HIGH 0 "no" 1 "yes" ;
VAL_ 452 RESOLVER_CALIBRATION_FAILED 0 "no" 1 "yes" ;
VAL_ 452 SYSTEM_FAULT 0 "no" 1 "yes" ;
VAL_ 452 INTERLOCK_OPEN 0 "no" 1 "yes" ;
VAL_ 452 APPC_HAS_GATE_DRIVER_DISABLED 0 "no" 1 "yes" ;
VAL_ 452 MOTOR_STALL_ERROR 0 "no" 1 "yes" ;
VAL_ 452 AMBIENT_TEMPERATURE_WARNING 0 "no" 1 "yes" ;
VAL_ 452 AMBIENT_OVERTEMPERATURE 0 "no" 1 "yes" ;
VAL_ 452 AMBIENT_TEMPSENSOR_ERROR 0 "no" 1 "yes" ;
VAL_ 452 POWERMODULE_CLAMPING_TIMEOUT 0 "no" 1 "yes" ;
VAL_ 452 DCBUS_RIPPLE_TO_HIGH 0 "no" 1 "yes" ;
VAL_ 452 MOTOR_I2XT_WARNING 0 "no" 1 "yes" ;
VAL_ 452 MOTOR_I2XT_ERROR 0 "no" 1 "yes" ;
VAL_ 452 MOTOR_FIELDWEAKENING_ERROR 0 "no" 1 "yes" ;
VAL_ 452 INVALID_PARAMETER_COMBINATION 0 "no" 1 "yes" ;
VAL_ 452 PLUG_COVER_SENSOR_SIGNAL_LOW 0 "no" 1 "yes" ;
VAL_ 452 MOTOR_CONNECTION_TEST_FAILED 0 "no" 1 "yes" ;
VAL_ 452 POWERMODULE_IXT_WARNING 0 "no" 1 "yes" ;
VAL_ 452 ISOLATION_FAULT 0 "no" 1 "yes" ;
VAL_ 453 Inverter_A_Statusword_5 0 "NotReadyToSwitchOn" 64 "SwitchOnDisabled" 80 "SwitchOnDisabled" 96 "SwitchOnDisabled" 112 "SwitchOnDisabled" 33 "ReadyToSwitchOn" 49 "ReadyToSwitchOn" 35 "SwitchedOn" 51 "SwitchedOn" 39 "OperationEnabled" 55 "OperationEnabled" 7 "QuickStopActive" 23 "QuickStopActive" 15 "FaultReactionActive" 31 "FaultReactionActive" 47 "FaultReactionActive" 63 "FaultReactionActive" 8 "Fault" 24 "Fault" 40 "Fault" 56 "Fault" ;
VAL_ 453 EVENTBUFFER_NEW_EVENT 0 "no" 1 "yes" ;
VAL_ 453 EVENTBUFFER_OVERFLOW 0 "no" 1 "yes" ;
VAL_ 453 POWERMODULE_TRIPZONE_OVERCURRE 0 "no" 1 "yes" ;
VAL_ 453 POWERMODULE_CURRENT_OFFSET_INI 0 "no" 1 "yes" ;
VAL_ 453 POWERMODULE_TEMPSENSOR_ERROR 0 "no" 1 "yes" ;
VAL_ 453 POWERMODULE_TEMPERATURE_WARNIN 0 "no" 1 "yes" ;
VAL_ 453 POWERMODULE_OVERTEMPERATURE 0 "no" 1 "yes" ;
VAL_ 453 POWERMODULE_IXT_FAULT 0 "no" 1 "yes" ;
VAL_ 453 POWERMODULE_SW_OVERCURRENT 0 "no" 1 "yes" ;
VAL_ 453 POWERMODULE_PATTERNDATA_INCONS 0 "no" 1 "yes" ;
VAL_ 453 DCBUS_TRIPZONE_OVERVOLTAGE 0 "no" 1 "yes" ;
VAL_ 453 DCBUS_SW_OVERVOLTAGE 0 "no" 1 "yes" ;
VAL_ 453 DCBUS_SW_UNDERVOLTAGE 0 "no" 1 "yes" ;
VAL_ 453 NEIGHBOUR_FAULT 0 "no" 1 "yes" ;
VAL_ 453 MOTOR_TEMPSENSOR_ERROR 0 "no" 1 "yes" ;
VAL_ 453 MOTOR_TEMPERATURE_WARNING 0 "no" 1 "yes" ;
VAL_ 453 MOTOR_OVERTEMPERATURE 0 "no" 1 "yes" ;
VAL_ 453 MOTOR_STATOR_FREQ_TO_HIGH 0 "no" 1 "yes" ;
VAL_ 453 SUPPLYVOLTAGE_ERROR 0 "no" 1 "yes" ;
VAL_ 453 RPDO_TIMEOUT 0 "no" 1 "yes" ;
VAL_ 453 NMT_NOT_OPERATIONAL 0 "no" 1 "yes" ;
VAL_ 453 TASKOVERRUN 0 "no" 1 "yes" ;
VAL_ 453 NETSYNC_ERROR 0 "no" 1 "yes" ;
VAL_ 453 POSDEVICE_SIGNAL_TO_LOW 0 "no" 1 "yes" ;
VAL_ 453 POSDEVICE_SIGNAL_TO_HIGH 0 "no" 1 "yes" ;
VAL_ 453 RESOLVER_CALIBRATION_FAILED 0 "no" 1 "yes" ;
VAL_ 453 SYSTEM_FAULT 0 "no" 1 "yes" ;
VAL_ 453 INTERLOCK_OPEN 0 "no" 1 "yes" ;
VAL_ 453 APPC_HAS_GATE_DRIVER_DISABLED 0 "no" 1 "yes" ;
VAL_ 453 MOTOR_STALL_ERROR 0 "no" 1 "yes" ;
VAL_ 453 AMBIENT_TEMPERATURE_WARNING 0 "no" 1 "yes" ;
VAL_ 453 AMBIENT_OVERTEMPERATURE 0 "no" 1 "yes" ;
VAL_ 453 AMBIENT_TEMPSENSOR_ERROR 0 "no" 1 "yes" ;
VAL_ 453 POWERMODULE_CLAMPING_TIMEOUT 0 "no" 1 "yes" ;
VAL_ 453 DCBUS_RIPPLE_TO_HIGH 0 "no" 1 "yes" ;
VAL_ 453 MOTOR_I2XT_WARNING 0 "no" 1 "yes" ;
VAL_ 453 MOTOR_I2XT_ERROR 0 "no" 1 "yes" ;
VAL_ 453 MOTOR_FIELDWEAKENING_ERROR 0 "no" 1 "yes" ;
VAL_ 453 INVALID_PARAMETER_COMBINATION 0 "no" 1 "yes" ;
VAL_ 453 PLUG_COVER_SENSOR_SIGNAL_LOW 0 "no" 1 "yes" ;
VAL_ 453 MOTOR_CONNECTION_TEST_FAILED 0 "no" 1 "yes" ;
VAL_ 453 POWERMODULE_IXT_WARNING 0 "no" 1 "yes" ;
VAL_ 453 ISOLATION_FAULT 0 "no" 1 "yes" ;
VAL_ 454 Inverter_A_Statusword_6 0 "NotReadyToSwitchOn" 64 "SwitchOnDisabled" 80 "SwitchOnDisabled" 96 "SwitchOnDisabled" 112 "SwitchOnDisabled" 33 "ReadyToSwitchOn" 49 "ReadyToSwitchOn" 35 "SwitchedOn" 51 "SwitchedOn" 39 "OperationEnabled" 55 "OperationEnabled" 7 "QuickStopActive" 23 "QuickStopActive" 15 "FaultReactionActive" 31 "FaultReactionActive" 47 "FaultReactionActive" 63 "FaultReactionActive" 8 "Fault" 24 "Fault" 40 "Fault" 56 "Fault" ;
VAL_ 454 EVENTBUFFER_NEW_EVENT 0 "no" 1 "yes" ;
VAL_ 454 EVENTBUFFER_OVERFLOW 0 "no" 1 "yes" ;
VAL_ 454 POWERMODULE_TRIPZONE_OVERCURRE 0 "no" 1 "yes" ;
VAL_ 454 POWERMODULE_CURRENT_OFFSET_INI 0 "no" 1 "yes" ;
VAL_ 454 POWERMODULE_TEMPSENSOR_ERROR 0 "no" 1 "yes" ;
VAL_ 454 POWERMODULE_TEMPERATURE_WARNIN 0 "no" 1 "yes" ;
VAL_ 454 POWERMODULE_OVERTEMPERATURE 0 "no" 1 "yes" ;
VAL_ 454 POWERMODULE_IXT_FAULT 0 "no" 1 "yes" ;
VAL_ 454 POWERMODULE_SW_OVERCURRENT 0 "no" 1 "yes" ;
VAL_ 454 POWERMODULE_PATTERNDATA_INCONS 0 "no" 1 "yes" ;
VAL_ 454 DCBUS_TRIPZONE_OVERVOLTAGE 0 "no" 1 "yes" ;
VAL_ 454 DCBUS_SW_OVERVOLTAGE 0 "no" 1 "yes" ;
VAL_ 454 DCBUS_SW_UNDERVOLTAGE 0 "no" 1 "yes" ;
VAL_ 454 NEIGHBOUR_FAULT 0 "no" 1 "yes" ;
VAL_ 454 MOTOR_TEMPSENSOR_ERROR 0 "no" 1 "yes" ;
VAL_ 454 MOTOR_TEMPERATURE_WARNING 0 "no" 1 "yes" ;
VAL_ 454 MOTOR_OVERTEMPERATURE 0 "no" 1 "yes" ;
VAL_ 454 MOTOR_STATOR_FREQ_TO_HIGH 0 "no" 1 "yes" ;
VAL_ 454 SUPPLYVOLTAGE_ERROR 0 "no" 1 "yes" ;
VAL_ 454 RPDO_TIMEOUT 0 "no" 1 "yes" ;
VAL_ 454 NMT_NOT_OPERATIONAL 0 "no" 1 "yes" ;
VAL_ 454 TASKOVERRUN 0 "no" 1 "yes" ;
VAL_ 454 NETSYNC_ERROR 0 "no" 1 "yes" ;
VAL_ 454 POSDEVICE_SIGNAL_TO_LOW 0 "no" 1 "yes" ;
VAL_ 454 POSDEVICE_SIGNAL_TO_HIGH 0 "no" 1 "yes" ;
VAL_ 454 RESOLVER_CALIBRATION_FAILED 0 "no" 1 "yes" ;
VAL_ 454 SYSTEM_FAULT 0 "no" 1 "yes" ;
VAL_ 454 INTERLOCK_OPEN 0 "no" 1 "yes" ;
VAL_ 454 APPC_HAS_GATE_DRIVER_DISABLED 0 "no" 1 "yes" ;
VAL_ 454 MOTOR_STALL_ERROR 0 "no" 1 "yes" ;
VAL_ 454 AMBIENT_TEMPERATURE_WARNING 0 "no" 1 "yes" ;
VAL_ 454 AMBIENT_OVERTEMPERATURE 0 "no" 1 "yes" ;
VAL_ 454 AMBIENT_TEMPSENSOR_ERROR 0 "no" 1 "yes" ;
VAL_ 454 POWERMODULE_CLAMPING_TIMEOUT 0 "no" 1 "yes" ;
VAL_ 454 DCBUS_RIPPLE_TO_HIGH 0 "no" 1 "yes" ;
VAL_ 454 MOTOR_I2XT_WARNING 0 "no" 1 "yes" ;
VAL_ 454 MOTOR_I2XT_ERROR 0 "no" 1 "yes" ;
VAL_ 454 MOTOR_FIELDWEAKENING_ERROR 0 "no" 1 "yes" ;
VAL_ 454 INVALID_PARAMETER_COMBINATION 0 "no" 1 "yes" ;
VAL_ 454 PLUG_COVER_SENSOR_SIGNAL_LOW 0 "no" 1 "yes" ;
VAL_ 454 MOTOR_CONNECTION_TEST_FAILED 0 "no" 1 "yes" ;
VAL_ 454 POWERMODULE_IXT_WARNING 0 "no" 1 "yes" ;
VAL_ 454 ISOLATION_FAULT 0 "no" 1 "yes" ;
VAL_ 455 Inverter_A_Statusword_7 0 "NotReadyToSwitchOn" 64 "SwitchOnDisabled" 80 "SwitchOnDisabled" 96 "SwitchOnDisabled" 112 "SwitchOnDisabled" 33 "ReadyToSwitchOn" 49 "ReadyToSwitchOn" 35 "SwitchedOn" 51 "SwitchedOn" 39 "OperationEnabled" 55 "OperationEnabled" 7 "QuickStopActive" 23 "QuickStopActive" 15 "FaultReactionActive" 31 "FaultReactionActive" 47 "FaultReactionActive" 63 "FaultReactionActive" 8 "Fault" 24 "Fault" 40 "Fault" 56 "Fault" ;
VAL_ 455 EVENTBUFFER_NEW_EVENT 0 "no" 1 "yes" ;
VAL_ 455 EVENTBUFFER_OVERFLOW 0 "no" 1 "yes" ;
VAL_ 455 POWERMODULE_TRIPZONE_OVERCURRE 0 "no" 1 "yes" ;
VAL_ 455 POWERMODULE_CURRENT_OFFSET_INI 0 "no" 1 "yes" ;
VAL_ 455 POWERMODULE_TEMPSENSOR_ERROR 0 "no" 1 "yes" ;
VAL_ 455 POWERMODULE_TEMPERATURE_WARNIN 0 "no" 1 "yes" ;
VAL_ 455 POWERMODULE_OVERTEMPERATURE 0 "no" 1 "yes" ;
VAL_ 455 POWERMODULE_IXT_FAULT 0 "no" 1 "yes" ;
VAL_ 455 POWERMODULE_SW_OVERCURRENT 0 "no" 1 "yes" ;
VAL_ 455 POWERMODULE_PATTERNDATA_INCONS 0 "no" 1 "yes" ;
VAL_ 455 DCBUS_TRIPZONE_OVERVOLTAGE 0 "no" 1 "yes" ;
VAL_ 455 DCBUS_SW_OVERVOLTAGE 0 "no" 1 "yes" ;
VAL_ 455 DCBUS_SW_UNDERVOLTAGE 0 "no" 1 "yes" ;
VAL_ 455 NEIGHBOUR_FAULT 0 "no" 1 "yes" ;
VAL_ 455 MOTOR_TEMPSENSOR_ERROR 0 "no" 1 "yes" ;
VAL_ 455 MOTOR_TEMPERATURE_WARNING 0 "no" 1 "yes" ;
VAL_ 455 MOTOR_OVERTEMPERATURE 0 "no" 1 "yes" ;
VAL_ 455 MOTOR_STATOR_FREQ_TO_HIGH 0 "no" 1 "yes" ;
VAL_ 455 SUPPLYVOLTAGE_ERROR 0 "no" 1 "yes" ;
VAL_ 455 RPDO_TIMEOUT 0 "no" 1 "yes" ;
VAL_ 455 NMT_NOT_OPERATIONAL 0 "no" 1 "yes" ;
VAL_ 455 TASKOVERRUN 0 "no" 1 "yes" ;
VAL_ 455 NETSYNC_ERROR 0 "no" 1 "yes" ;
VAL_ 455 POSDEVICE_SIGNAL_TO_LOW 0 "no" 1 "yes" ;
VAL_ 455 POSDEVICE_SIGNAL_TO_HIGH 0 "no" 1 "yes" ;
VAL_ 455 RESOLVER_CALIBRATION_FAILED 0 "no" 1 "yes" ;
VAL_ 455 SYSTEM_FAULT 0 "no" 1 "yes" ;
VAL_ 455 INTERLOCK_OPEN 0 "no" 1 "yes" ;
VAL_ 455 APPC_HAS_GATE_DRIVER_DISABLED 0 "no" 1 "yes" ;
VAL_ 455 MOTOR_STALL_ERROR 0 "no" 1 "yes" ;
VAL_ 455 AMBIENT_TEMPERATURE_WARNING 0 "no" 1 "yes" ;
VAL_ 455 AMBIENT_OVERTEMPERATURE 0 "no" 1 "yes" ;
VAL_ 455 AMBIENT_TEMPSENSOR_ERROR 0 "no" 1 "yes" ;
VAL_ 455 POWERMODULE_CLAMPING_TIMEOUT 0 "no" 1 "yes" ;
VAL_ 455 DCBUS_RIPPLE_TO_HIGH 0 "no" 1 "yes" ;
VAL_ 455 MOTOR_I2XT_WARNING 0 "no" 1 "yes" ;
VAL_ 455 MOTOR_I2XT_ERROR 0 "no" 1 "yes" ;
VAL_ 455 MOTOR_FIELDWEAKENING_ERROR 0 "no" 1 "yes" ;
VAL_ 455 INVALID_PARAMETER_COMBINATION 0 "no" 1 "yes" ;
VAL_ 455 PLUG_COVER_SENSOR_SIGNAL_LOW 0 "no" 1 "yes" ;
VAL_ 455 MOTOR_CONNECTION_TEST_FAILED 0 "no" 1 "yes" ;
VAL_ 455 POWERMODULE_IXT_WARNING 0 "no" 1 "yes" ;
VAL_ 455 ISOLATION_FAULT 0 "no" 1 "yes" ;
VAL_ 456 Inverter_A_Statusword_8 0 "NotReadyToSwitchOn" 64 "SwitchOnDisabled" 80 "SwitchOnDisabled" 96 "SwitchOnDisabled" 112 "SwitchOnDisabled" 33 "ReadyToSwitchOn" 49 "ReadyToSwitchOn" 35 "SwitchedOn" 51 "SwitchedOn" 39 "OperationEnabled" 55 "OperationEnabled" 7 "QuickStopActive" 23 "QuickStopActive" 15 "FaultReactionActive" 31 "FaultReactionActive" 47 "FaultReactionActive" 63 "FaultReactionActive" 8 "Fault" 24 "Fault" 40 "Fault" 56 "Fault" ;
VAL_ 456 EVENTBUFFER_NEW_EVENT 0 "no" 1 "yes" ;
VAL_ 456 EVENTBUFFER_OVERFLOW 0 "no" 1 "yes" ;
VAL_ 456 POWERMODULE_TRIPZONE_OVERCURRE 0 "no" 1 "yes" ;
VAL_ 456 POWERMODULE_CURRENT_OFFSET_INI 0 "no" 1 "yes" ;
VAL_ 456 POWERMODULE_TEMPSENSOR_ERROR 0 "no" 1 "yes" ;
VAL_ 456 POWERMODULE_TEMPERATURE_WARNIN 0 "no" 1 "yes" ;
VAL_ 456 POWERMODULE_OVERTEMPERATURE 0 "no" 1 "yes" ;
VAL_ 456 POWERMODULE_IXT_FAULT 0 "no" 1 "yes" ;
VAL_ 456 POWERMODULE_SW_OVERCURRENT 0 "no" 1 "yes" ;
VAL_ 456 POWERMODULE_PATTERNDATA_INCONS 0 "no" 1 "yes" ;
VAL_ 456 DCBUS_TRIPZONE_OVERVOLTAGE 0 "no" 1 "yes" ;
VAL_ 456 DCBUS_SW_OVERVOLTAGE 0 "no" 1 "yes" ;
VAL_ 456 DCBUS_SW_UNDERVOLTAGE 0 "no" 1 "yes" ;
VAL_ 456 NEIGHBOUR_FAULT 0 "no" 1 "yes" ;
VAL_ 456 MOTOR_TEMPSENSOR_ERROR 0 "no" 1 "yes" ;
VAL_ 456 MOTOR_TEMPERATURE_WARNING 0 "no" 1 "yes" ;
VAL_ 456 MOTOR_OVERTEMPERATURE 0 "no" 1 "yes" ;
VAL_ 456 MOTOR_STATOR_FREQ_TO_HIGH 0 "no" 1 "yes" ;
VAL_ 456 SUPPLYVOLTAGE_ERROR 0 "no" 1 "yes" ;
VAL_ 456 RPDO_TIMEOUT 0 "no" 1 "yes" ;
VAL_ 456 NMT_NOT_OPERATIONAL 0 "no" 1 "yes" ;
VAL_ 456 TASKOVERRUN 0 "no" 1 "yes" ;
VAL_ 456 NETSYNC_ERROR 0 "no" 1 "yes" ;
VAL_ 456 POSDEVICE_SIGNAL_TO_LOW 0 "no" 1 "yes" ;
VAL_ 456 POSDEVICE_SIGNAL_TO_HIGH 0 "no" 1 "yes" ;
VAL_ 456 RESOLVER_CALIBRATION_FAILED 0 "no" 1 "yes" ;
VAL_ 456 SYSTEM_FAULT 0 "no" 1 "yes" ;
VAL_ 456 INTERLOCK_OPEN 0 "no" 1 "yes" ;
VAL_ 456 APPC_HAS_GATE_DRIVER_DISABLED 0 "no" 1 "yes" ;
VAL_ 456 MOTOR_STALL_ERROR 0 "no" 1 "yes" ;
VAL_ 456 AMBIENT_TEMPERATURE_WARNING 0 "no" 1 "yes" ;
VAL_ 456 AMBIENT_OVERTEMPERATURE 0 "no" 1 "yes" ;
VAL_ 456 AMBIENT_TEMPSENSOR_ERROR 0 "no" 1 "yes" ;
VAL_ 456 POWERMODULE_CLAMPING_TIMEOUT 0 "no" 1 "yes" ;
VAL_ 456 DCBUS_RIPPLE_TO_HIGH 0 "no" 1 "yes" ;
VAL_ 456 MOTOR_I2XT_WARNING 0 "no" 1 "yes" ;
VAL_ 456 MOTOR_I2XT_ERROR 0 "no" 1 "yes" ;
VAL_ 456 MOTOR_FIELDWEAKENING_ERROR 0 "no" 1 "yes" ;
VAL_ 456 INVALID_PARAMETER_COMBINATION 0 "no" 1 "yes" ;
VAL_ 456 PLUG_COVER_SENSOR_SIGNAL_LOW 0 "no" 1 "yes" ;
VAL_ 456 MOTOR_CONNECTION_TEST_FAILED 0 "no" 1 "yes" ;
VAL_ 456 POWERMODULE_IXT_WARNING 0 "no" 1 "yes" ;
VAL_ 456 ISOLATION_FAULT 0 "no" 1 "yes" ;
VAL_ 457 Inverter_A_Statusword_9 0 "NotReadyToSwitchOn" 64 "SwitchOnDisabled" 80 "SwitchOnDisabled" 96 "SwitchOnDisabled" 112 "SwitchOnDisabled" 33 "ReadyToSwitchOn" 49 "ReadyToSwitchOn" 35 "SwitchedOn" 51 "SwitchedOn" 39 "OperationEnabled" 55 "OperationEnabled" 7 "QuickStopActive" 23 "QuickStopActive" 15 "FaultReactionActive" 31 "FaultReactionActive" 47 "FaultReactionActive" 63 "FaultReactionActive" 8 "Fault" 24 "Fault" 40 "Fault" 56 "Fault" ;
VAL_ 457 EVENTBUFFER_NEW_EVENT 0 "no" 1 "yes" ;
VAL_ 457 EVENTBUFFER_OVERFLOW 0 "no" 1 "yes" ;
VAL_ 457 POWERMODULE_TRIPZONE_OVERCURRE 0 "no" 1 "yes" ;
VAL_ 457 POWERMODULE_CURRENT_OFFSET_INI 0 "no" 1 "yes" ;
VAL_ 457 POWERMODULE_TEMPSENSOR_ERROR 0 "no" 1 "yes" ;
VAL_ 457 POWERMODULE_TEMPERATURE_WARNIN 0 "no" 1 "yes" ;
VAL_ 457 POWERMODULE_OVERTEMPERATURE 0 "no" 1 "yes" ;
VAL_ 457 POWERMODULE_IXT_FAULT 0 "no" 1 "yes" ;
VAL_ 457 POWERMODULE_SW_OVERCURRENT 0 "no" 1 "yes" ;
VAL_ 457 POWERMODULE_PATTERNDATA_INCONS 0 "no" 1 "yes" ;
VAL_ 457 DCBUS_TRIPZONE_OVERVOLTAGE 0 "no" 1 "yes" ;
VAL_ 457 DCBUS_SW_OVERVOLTAGE 0 "no" 1 "yes" ;
VAL_ 457 DCBUS_SW_UNDERVOLTAGE 0 "no" 1 "yes" ;
VAL_ 457 NEIGHBOUR_FAULT 0 "no" 1 "yes" ;
VAL_ 457 MOTOR_TEMPSENSOR_ERROR 0 "no" 1 "yes" ;
VAL_ 457 MOTOR_TEMPERATURE_WARNING 0 "no" 1 "yes" ;
VAL_ 457 MOTOR_OVERTEMPERATURE 0 "no" 1 "yes" ;
VAL_ 457 MOTOR_STATOR_FREQ_TO_HIGH 0 "no" 1 "yes" ;
VAL_ 457 SUPPLYVOLTAGE_ERROR 0 "no" 1 "yes" ;
VAL_ 457 RPDO_TIMEOUT 0 "no" 1 "yes" ;
VAL_ 457 NMT_NOT_OPERATIONAL 0 "no" 1 "yes" ;
VAL_ 457 TASKOVERRUN 0 "no" 1 "yes" ;
VAL_ 457 NETSYNC_ERROR 0 "no" 1 "yes" ;
VAL_ 457 POSDEVICE_SIGNAL_TO_LOW 0 "no" 1 "yes" ;
VAL_ 457 POSDEVICE_SIGNAL_TO_HIGH 0 "no" 1 "yes" ;
VAL_ 457 RESOLVER_CALIBRATION_FAILED 0 "no" 1 "yes" ;
VAL_ 457 SYSTEM_FAULT 0 "no" 1 "yes" ;
VAL_ 457 INTERLOCK_OPEN 0 "no" 1 "yes" ;
VAL_ 457 APPC_HAS_GATE_DRIVER_DISABLED 0 "no" 1 "yes" ;
VAL_ 457 MOTOR_STALL_ERROR 0 "no" 1 "yes" ;
VAL_ 457 AMBIENT_TEMPERATURE_WARNING 0 "no" 1 "yes" ;
VAL_ 457 AMBIENT_OVERTEMPERATURE 0 "no" 1 "yes" ;
VAL_ 457 AMBIENT_TEMPSENSOR_ERROR 0 "no" 1 "yes" ;
VAL_ 457 POWERMODULE_CLAMPING_TIMEOUT 0 "no" 1 "yes" ;
VAL_ 457 DCBUS_RIPPLE_TO_HIGH 0 "no" 1 "yes" ;
VAL_ 457 MOTOR_I2XT_WARNING 0 "no" 1 "yes" ;
VAL_ 457 MOTOR_I2XT_ERROR 0 "no" 1 "yes" ;
VAL_ 457 MOTOR_FIELDWEAKENING_ERROR 0 "no" 1 "yes" ;
VAL_ 457 INVALID_PARAMETER_COMBINATION 0 "no" 1 "yes" ;
VAL_ 457 PLUG_COVER_SENSOR_SIGNAL_LOW 0 "no" 1 "yes" ;
VAL_ 457 MOTOR_CONNECTION_TEST_FAILED 0 "no" 1 "yes" ;
VAL_ 457 POWERMODULE_IXT_WARNING 0 "no" 1 "yes" ;
VAL_ 457 ISOLATION_FAULT 0 "no" 1 "yes" ;
VAL_ 458 Inverter_A_Statusword_10 0 "NotReadyToSwitchOn" 64 "SwitchOnDisabled" 80 "SwitchOnDisabled" 96 "SwitchOnDisabled" 112 "SwitchOnDisabled" 33 "ReadyToSwitchOn" 49 "ReadyToSwitchOn" 35 "SwitchedOn" 51 "SwitchedOn" 39 "OperationEnabled" 55 "OperationEnabled" 7 "QuickStopActive" 23 "QuickStopActive" 15 "FaultReactionActive" 31 "FaultReactionActive" 47 "FaultReactionActive" 63 "FaultReactionActive" 8 "Fault" 24 "Fault" 40 "Fault" 56 "Fault" ;
VAL_ 458 EVENTBUFFER_NEW_EVENT 0 "no" 1 "yes" ;
VAL_ 458 EVENTBUFFER_OVERFLOW 0 "no" 1 "yes" ;
VAL_ 458 POWERMODULE_TRIPZONE_OVERCURRE 0 "no" 1 "yes" ;
VAL_ 458 POWERMODULE_CURRENT_OFFSET_INI 0 "no" 1 "yes" ;
VAL_ 458 POWERMODULE_TEMPSENSOR_ERROR 0 "no" 1 "yes" ;
VAL_ 458 POWERMODULE_TEMPERATURE_WARNIN 0 "no" 1 "yes" ;
VAL_ 458 POWERMODULE_OVERTEMPERATURE 0 "no" 1 "yes" ;
VAL_ 458 POWERMODULE_IXT_FAULT 0 "no" 1 "yes" ;
VAL_ 458 POWERMODULE_SW_OVERCURRENT 0 "no" 1 "yes" ;
VAL_ 458 POWERMODULE_PATTERNDATA_INCONS 0 "no" 1 "yes" ;
VAL_ 458 DCBUS_TRIPZONE_OVERVOLTAGE 0 "no" 1 "yes" ;
VAL_ 458 DCBUS_SW_OVERVOLTAGE 0 "no" 1 "yes" ;
VAL_ 458 DCBUS_SW_UNDERVOLTAGE 0 "no" 1 "yes" ;
VAL_ 458 NEIGHBOUR_FAULT 0 "no" 1 "yes" ;
VAL_ 458 MOTOR_TEMPSENSOR_ERROR 0 "no" 1 "yes" ;
VAL_ 458 MOTOR_TEMPERATURE_WARNING 0 "no" 1 "yes" ;
VAL_ 458 MOTOR_OVERTEMPERATURE 0 "no" 1 "yes" ;
VAL_ 458 MOTOR_STATOR_FREQ_TO_HIGH 0 "no" 1 "yes" ;
VAL_ 458 SUPPLYVOLTAGE_ERROR 0 "no" 1 "yes" ;
VAL_ 458 RPDO_TIMEOUT 0 "no" 1 "yes" ;
VAL_ 458 NMT_NOT_OPERATIONAL 0 "no" 1 "yes" ;
VAL_ 458 TASKOVERRUN 0 "no" 1 "yes" ;
VAL_ 458 NETSYNC_ERROR 0 "no" 1 "yes" ;
VAL_ 458 POSDEVICE_SIGNAL_TO_LOW 0 "no" 1 "yes" ;
VAL_ 458 POSDEVICE_SIGNAL_TO_HIGH 0 "no" 1 "yes" ;
VAL_ 458 RESOLVER_CALIBRATION_FAILED 0 "no" 1 "yes" ;
VAL_ 458 SYSTEM_FAULT 0 "no" 1 "yes" ;
VAL_ 458 INTERLOCK_OPEN 0 "no" 1 "yes" ;
VAL_ 458 APPC_HAS_GATE_DRIVER_DISABLED 0 "no" 1 "yes" ;
VAL_ 458 MOTOR_STALL_ERROR 0 "no" 1 "yes" ;
VAL_ 458 AMBIENT_TEMPERATURE_WARNING 0 "no" 1 "yes" ;
VAL_ 458 AMBIENT_OVERTEMPERATURE 0 "no" 1 "yes" ;
VAL_ 458 AMBIENT_TEMPSENSOR_ERROR 0 "no" 1 "yes" ;
VAL_ 458 POWERMODULE_CLAMPING_TIMEOUT 0 "no" 1 "yes" ;
VAL_ 458 DCBUS_RIPPLE_TO_HIGH 0 "no" 1 "yes" ;
VAL_ 458 MOTOR_I2XT_WARNING 0 "no" 1 "yes" ;
VAL_ 458 MOTOR_I2XT_ERROR 0 "no" 1 "yes" ;
VAL_ 458 MOTOR_FIELDWEAKENING_ERROR 0 "no" 1 "yes" ;
VAL_ 458 INVALID_PARAMETER_COMBINATION 0 "no" 1 "yes" ;
VAL_ 458 PLUG_COVER_SENSOR_SIGNAL_LOW 0 "no" 1 "yes" ;
VAL_ 458 MOTOR_CONNECTION_TEST_FAILED 0 "no" 1 "yes" ;
VAL_ 458 POWERMODULE_IXT_WARNING 0 "no" 1 "yes" ;
VAL_ 458 ISOLATION_FAULT 0 "no" 1 "yes" ;
VAL_ 459 Inverter_A_Statusword_11 0 "NotReadyToSwitchOn" 64 "SwitchOnDisabled" 80 "SwitchOnDisabled" 96 "SwitchOnDisabled" 112 "SwitchOnDisabled" 33 "ReadyToSwitchOn" 49 "ReadyToSwitchOn" 35 "SwitchedOn" 51 "SwitchedOn" 39 "OperationEnabled" 55 "OperationEnabled" 7 "QuickStopActive" 23 "QuickStopActive" 15 "FaultReactionActive" 31 "FaultReactionActive" 47 "FaultReactionActive" 63 "FaultReactionActive" 8 "Fault" 24 "Fault" 40 "Fault" 56 "Fault" ;
VAL_ 459 EVENTBUFFER_NEW_EVENT 0 "no" 1 "yes" ;
VAL_ 459 EVENTBUFFER_OVERFLOW 0 "no" 1 "yes" ;
VAL_ 459 POWERMODULE_TRIPZONE_OVERCURRE 0 "no" 1 "yes" ;
VAL_ 459 POWERMODULE_CURRENT_OFFSET_INI 0 "no" 1 "yes" ;
VAL_ 459 POWERMODULE_TEMPSENSOR_ERROR 0 "no" 1 "yes" ;
VAL_ 459 POWERMODULE_TEMPERATURE_WARNIN 0 "no" 1 "yes" ;
VAL_ 459 POWERMODULE_OVERTEMPERATURE 0 "no" 1 "yes" ;
VAL_ 459 POWERMODULE_IXT_FAULT 0 "no" 1 "yes" ;
VAL_ 459 POWERMODULE_SW_OVERCURRENT 0 "no" 1 "yes" ;
VAL_ 459 POWERMODULE_PATTERNDATA_INCONS 0 "no" 1 "yes" ;
VAL_ 459 DCBUS_TRIPZONE_OVERVOLTAGE 0 "no" 1 "yes" ;
VAL_ 459 DCBUS_SW_OVERVOLTAGE 0 "no" 1 "yes" ;
VAL_ 459 DCBUS_SW_UNDERVOLTAGE 0 "no" 1 "yes" ;
VAL_ 459 NEIGHBOUR_FAULT 0 "no" 1 "yes" ;
VAL_ 459 MOTOR_TEMPSENSOR_ERROR 0 "no" 1 "yes" ;
VAL_ 459 MOTOR_TEMPERATURE_WARNING 0 "no" 1 "yes" ;
VAL_ 459 MOTOR_OVERTEMPERATURE 0 "no" 1 "yes" ;
VAL_ 459 MOTOR_STATOR_FREQ_TO_HIGH 0 "no" 1 "yes" ;
VAL_ 459 SUPPLYVOLTAGE_ERROR 0 "no" 1 "yes" ;
VAL_ 459 RPDO_TIMEOUT 0 "no" 1 "yes" ;
VAL_ 459 NMT_NOT_OPERATIONAL 0 "no" 1 "yes" ;
VAL_ 459 TASKOVERRUN 0 "no" 1 "yes" ;
VAL_ 459 NETSYNC_ERROR 0 "no" 1 "yes" ;
VAL_ 459 POSDEVICE_SIGNAL_TO_LOW 0 "no" 1 "yes" ;
VAL_ 459 POSDEVICE_SIGNAL_TO_HIGH 0 "no" 1 "yes" ;
VAL_ 459 RESOLVER_CALIBRATION_FAILED 0 "no" 1 "yes" ;
VAL_ 459 SYSTEM_FAULT 0 "no" 1 "yes" ;
VAL_ 459 INTERLOCK_OPEN 0 "no" 1 "yes" ;
VAL_ 459 APPC_HAS_GATE_DRIVER_DISABLED 0 "no" 1 "yes" ;
VAL_ 459 MOTOR_STALL_ERROR 0 "no" 1 "yes" ;
VAL_ 459 AMBIENT_TEMPERATURE_WARNING 0 "no" 1 "yes" ;
VAL_ 459 AMBIENT_OVERTEMPERATURE 0 "no" 1 "yes" ;
VAL_ 459 AMBIENT_TEMPSENSOR_ERROR 0 "no" 1 "yes" ;
VAL_ 459 POWERMODULE_CLAMPING_TIMEOUT 0 "no" 1 "yes" ;
VAL_ 459 DCBUS_RIPPLE_TO_HIGH 0 "no" 1 "yes" ;
VAL_ 459 MOTOR_I2XT_WARNING 0 "no" 1 "yes" ;
VAL_ 459 MOTOR_I2XT_ERROR 0 "no" 1 "yes" ;
VAL_ 459 MOTOR_FIELDWEAKENING_ERROR 0 "no" 1 "yes" ;
VAL_ 459 INVALID_PARAMETER_COMBINATION 0 "no" 1 "yes" ;
VAL_ 459 PLUG_COVER_SENSOR_SIGNAL_LOW 0 "no" 1 "yes" ;
VAL_ 459 MOTOR_CONNECTION_TEST_FAILED 0 "no" 1 "yes" ;
VAL_ 459 POWERMODULE_IXT_WARNING 0 "no" 1 "yes" ;
VAL_ 459 ISOLATION_FAULT 0 "no" 1 "yes" ;
VAL_ 460 Inverter_A_Statusword_12 0 "NotReadyToSwitchOn" 64 "SwitchOnDisabled" 80 "SwitchOnDisabled" 96 "SwitchOnDisabled" 112 "SwitchOnDisabled" 33 "ReadyToSwitchOn" 49 "ReadyToSwitchOn" 35 "SwitchedOn" 51 "SwitchedOn" 39 "OperationEnabled" 55 "OperationEnabled" 7 "QuickStopActive" 23 "QuickStopActive" 15 "FaultReactionActive" 31 "FaultReactionActive" 47 "FaultReactionActive" 63 "FaultReactionActive" 8 "Fault" 24 "Fault" 40 "Fault" 56 "Fault" ;
VAL_ 460 EVENTBUFFER_NEW_EVENT 0 "no" 1 "yes" ;
VAL_ 460 EVENTBUFFER_OVERFLOW 0 "no" 1 "yes" ;
VAL_ 460 POWERMODULE_TRIPZONE_OVERCURRE 0 "no" 1 "yes" ;
VAL_ 460 POWERMODULE_CURRENT_OFFSET_INI 0 "no" 1 "yes" ;
VAL_ 460 POWERMODULE_TEMPSENSOR_ERROR 0 "no" 1 "yes" ;
VAL_ 460 POWERMODULE_TEMPERATURE_WARNIN 0 "no" 1 "yes" ;
VAL_ 460 POWERMODULE_OVERTEMPERATURE 0 "no" 1 "yes" ;
VAL_ 460 POWERMODULE_IXT_FAULT 0 "no" 1 "yes" ;
VAL_ 460 POWERMODULE_SW_OVERCURRENT 0 "no" 1 "yes" ;
VAL_ 460 POWERMODULE_PATTERNDATA_INCONS 0 "no" 1 "yes" ;
VAL_ 460 DCBUS_TRIPZONE_OVERVOLTAGE 0 "no" 1 "yes" ;
VAL_ 460 DCBUS_SW_OVERVOLTAGE 0 "no" 1 "yes" ;
VAL_ 460 DCBUS_SW_UNDERVOLTAGE 0 "no" 1 "yes" ;
VAL_ 460 NEIGHBOUR_FAULT 0 "no" 1 "yes" ;
VAL_ 460 MOTOR_TEMPSENSOR_ERROR 0 "no" 1 "yes" ;
VAL_ 460 MOTOR_TEMPERATURE_WARNING 0 "no" 1 "yes" ;
VAL_ 460 MOTOR_OVERTEMPERATURE 0 "no" 1 "yes" ;
VAL_ 460 MOTOR_STATOR_FREQ_TO_HIGH 0 "no" 1 "yes" ;
VAL_ 460 SUPPLYVOLTAGE_ERROR 0 "no" 1 "yes" ;
VAL_ 460 RPDO_TIMEOUT 0 "no" 1 "yes" ;
VAL_ 460 NMT_NOT_OPERATIONAL 0 "no" 1 "yes" ;
VAL_ 460 TASKOVERRUN 0 "no" 1 "yes" ;
VAL_ 460 NETSYNC_ERROR 0 "no" 1 "yes" ;
VAL_ 460 POSDEVICE_SIGNAL_TO_LOW 0 "no" 1 "yes" ;
VAL_ 460 POSDEVICE_SIGNAL_TO_HIGH 0 "no" 1 "yes" ;
VAL_ 460 RESOLVER_CALIBRATION_FAILED 0 "no" 1 "yes" ;
VAL_ 460 SYSTEM_FAULT 0 "no" 1 "yes" ;
VAL_ 460 INTERLOCK_OPEN 0 "no" 1 "yes" ;
VAL_ 460 APPC_HAS_GATE_DRIVER_DISABLED 0 "no" 1 "yes" ;
VAL_ 460 MOTOR_STALL_ERROR 0 "no" 1 "yes" ;
VAL_ 460 AMBIENT_TEMPERATURE_WARNING 0 "no" 1 "yes" ;
VAL_ 460 AMBIENT_OVERTEMPERATURE 0 "no" 1 "yes" ;
VAL_ 460 AMBIENT_TEMPSENSOR_ERROR 0 "no" 1 "yes" ;
VAL_ 460 POWERMODULE_CLAMPING_TIMEOUT 0 "no" 1 "yes" ;
VAL_ 460 DCBUS_RIPPLE_TO_HIGH 0 "no" 1 "yes" ;
VAL_ 460 MOTOR_I2XT_WARNING 0 "no" 1 "yes" ;
VAL_ 460 MOTOR_I2XT_ERROR 0 "no" 1 "yes" ;
VAL_ 460 MOTOR_FIELDWEAKENING_ERROR 0 "no" 1 "yes" ;
VAL_ 460 INVALID_PARAMETER_COMBINATION 0 "no" 1 "yes" ;
VAL_ 460 PLUG_COVER_SENSOR_SIGNAL_LOW 0 "no" 1 "yes" ;
VAL_ 460 MOTOR_CONNECTION_TEST_FAILED 0 "no" 1 "yes" ;
VAL_ 460 POWERMODULE_IXT_WARNING 0 "no" 1 "yes" ;
VAL_ 460 ISOLATION_FAULT 0 "no" 1 "yes" ;
VAL_ 461 Inverter_A_Statusword_13 0 "NotReadyToSwitchOn" 64 "SwitchOnDisabled" 80 "SwitchOnDisabled" 96 "SwitchOnDisabled" 112 "SwitchOnDisabled" 33 "ReadyToSwitchOn" 49 "ReadyToSwitchOn" 35 "SwitchedOn" 51 "SwitchedOn" 39 "OperationEnabled" 55 "OperationEnabled" 7 "QuickStopActive" 23 "QuickStopActive" 15 "FaultReactionActive" 31 "FaultReactionActive" 47 "FaultReactionActive" 63 "FaultReactionActive" 8 "Fault" 24 "Fault" 40 "Fault" 56 "Fault" ;
VAL_ 461 EVENTBUFFER_NEW_EVENT 0 "no" 1 "yes" ;
VAL_ 461 EVENTBUFFER_OVERFLOW 0 "no" 1 "yes" ;
VAL_ 461 POWERMODULE_TRIPZONE_OVERCURRE 0 "no" 1 "yes" ;
VAL_ 461 POWERMODULE_CURRENT_OFFSET_INI 0 "no" 1 "yes" ;
VAL_ 461 POWERMODULE_TEMPSENSOR_ERROR 0 "no" 1 "yes" ;
VAL_ 461 POWERMODULE_TEMPERATURE_WARNIN 0 "no" 1 "yes" ;
VAL_ 461 POWERMODULE_OVERTEMPERATURE 0 "no" 1 "yes" ;
VAL_ 461 POWERMODULE_IXT_FAULT 0 "no" 1 "yes" ;
VAL_ 461 POWERMODULE_SW_OVERCURRENT 0 "no" 1 "yes" ;
VAL_ 461 POWERMODULE_PATTERNDATA_INCONS 0 "no" 1 "yes" ;
VAL_ 461 DCBUS_TRIPZONE_OVERVOLTAGE 0 "no" 1 "yes" ;
VAL_ 461 DCBUS_SW_OVERVOLTAGE 0 "no" 1 "yes" ;
VAL_ 461 DCBUS_SW_UNDERVOLTAGE 0 "no" 1 "yes" ;
VAL_ 461 NEIGHBOUR_FAULT 0 "no" 1 "yes" ;
VAL_ 461 MOTOR_TEMPSENSOR_ERROR 0 "no" 1 "yes" ;
VAL_ 461 MOTOR_TEMPERATURE_WARNING 0 "no" 1 "yes" ;
VAL_ 461 MOTOR_OVERTEMPERATURE 0 "no" 1 "yes" ;
VAL_ 461 MOTOR_STATOR_FREQ_TO_HIGH 0 "no" 1 "yes" ;
VAL_ 461 SUPPLYVOLTAGE_ERROR 0 "no" 1 "yes" ;
VAL_ 461 RPDO_TIMEOUT 0 "no" 1 "yes" ;
VAL_ 461 NMT_NOT_OPERATIONAL 0 "no" 1 "yes" ;
VAL_ 461 TASKOVERRUN 0 "no" 1 "yes" ;
VAL_ 461 NETSYNC_ERROR 0 "no" 1 "yes" ;
VAL_ 461 POSDEVICE_SIGNAL_TO_LOW 0 "no" 1 "yes" ;
VAL_ 461 POSDEVICE_SIGNAL_TO_HIGH 0 "no" 1 "yes" ;
VAL_ 461 RESOLVER_CALIBRATION_FAILED 0 "no" 1 "yes" ;
VAL_ 461 SYSTEM_FAULT 0 "no" 1 "yes" ;
VAL_ 461 INTERLOCK_OPEN 0 "no" 1 "yes" ;
VAL_ 461 APPC_HAS_GATE_DRIVER_DISABLED 0 "no" 1 "yes" ;
VAL_ 461 MOTOR_STALL_ERROR 0 "no" 1 "yes" ;
VAL_ 461 AMBIENT_TEMPERATURE_WARNING 0 "no" 1 "yes" ;
VAL_ 461 AMBIENT_OVERTEMPERATURE 0 "no" 1 "yes" ;
VAL_ 461 AMBIENT_TEMPSENSOR_ERROR 0 "no" 1 "yes" ;
VAL_ 461 POWERMODULE_CLAMPING_TIMEOUT 0 "no" 1 "yes" ;
VAL_ 461 DCBUS_RIPPLE_TO_HIGH 0 "no" 1 "yes" ;
VAL_ 461 MOTOR_I2XT_WARNING 0 "no" 1 "yes" ;
VAL_ 461 MOTOR_I2XT_ERROR 0 "no" 1 "yes" ;
VAL_ 461 MOTOR_FIELDWEAKENING_ERROR 0 "no" 1 "yes" ;
VAL_ 461 INVALID_PARAMETER_COMBINATION 0 "no" 1 "yes" ;
VAL_ 461 PLUG_COVER_SENSOR_SIGNAL_LOW 0 "no" 1 "yes" ;
VAL_ 461 MOTOR_CONNECTION_TEST_FAILED 0 "no" 1 "yes" ;
VAL_ 461 POWERMODULE_IXT_WARNING 0 "no" 1 "yes" ;
VAL_ 461 ISOLATION_FAULT 0 "no" 1 "yes" ;
VAL_ 718 Inverter_B_Statusword_14 0 "NotReadyToSwitchOn" 64 "SwitchOnDisabled" 80 "SwitchOnDisabled" 96 "SwitchOnDisabled" 112 "SwitchOnDisabled" 33 "ReadyToSwitchOn" 49 "ReadyToSwitchOn" 35 "SwitchedOn" 51 "SwitchedOn" 39 "OperationEnabled" 55 "OperationEnabled" 7 "QuickStopActive" 23 "QuickStopActive" 15 "FaultReactionActive" 31 "FaultReactionActive" 47 "FaultReactionActive" 63 "FaultReactionActive" 8 "Fault" 24 "Fault" 40 "Fault" 56 "Fault" ;
VAL_ 718 EVENTBUFFER_NEW_EVENT 0 "no" 1 "yes" ;
VAL_ 718 EVENTBUFFER_OVERFLOW 0 "no" 1 "yes" ;
VAL_ 718 POWERMODULE_TRIPZONE_OVERCURRE 0 "no" 1 "yes" ;
VAL_ 718 POWERMODULE_CURRENT_OFFSET_INI 0 "no" 1 "yes" ;
VAL_ 718 POWERMODULE_TEMPSENSOR_ERROR 0 "no" 1 "yes" ;
VAL_ 718 POWERMODULE_TEMPERATURE_WARNIN 0 "no" 1 "yes" ;
VAL_ 718 POWERMODULE_OVERTEMPERATURE 0 "no" 1 "yes" ;
VAL_ 718 POWERMODULE_IXT_FAULT 0 "no" 1 "yes" ;
VAL_ 718 POWERMODULE_SW_OVERCURRENT 0 "no" 1 "yes" ;
VAL_ 718 POWERMODULE_PATTERNDATA_INCONS 0 "no" 1 "yes" ;
VAL_ 718 DCBUS_TRIPZONE_OVERVOLTAGE 0 "no" 1 "yes" ;
VAL_ 718 DCBUS_SW_OVERVOLTAGE 0 "no" 1 "yes" ;
VAL_ 718 DCBUS_SW_UNDERVOLTAGE 0 "no" 1 "yes" ;
VAL_ 718 NEIGHBOUR_FAULT 0 "no" 1 "yes" ;
VAL_ 718 MOTOR_TEMPSENSOR_ERROR 0 "no" 1 "yes" ;
VAL_ 718 MOTOR_TEMPERATURE_WARNING 0 "no" 1 "yes" ;
VAL_ 718 MOTOR_OVERTEMPERATURE 0 "no" 1 "yes" ;
VAL_ 718 MOTOR_STATOR_FREQ_TO_HIGH 0 "no" 1 "yes" ;
VAL_ 718 SUPPLYVOLTAGE_ERROR 0 "no" 1 "yes" ;
VAL_ 718 RPDO_TIMEOUT 0 "no" 1 "yes" ;
VAL_ 718 NMT_NOT_OPERATIONAL 0 "no" 1 "yes" ;
VAL_ 718 TASKOVERRUN 0 "no" 1 "yes" ;
VAL_ 718 NETSYNC_ERROR 0 "no" 1 "yes" ;
VAL_ 718 POSDEVICE_SIGNAL_TO_LOW 0 "no" 1 "yes" ;
VAL_ 718 POSDEVICE_SIGNAL_TO_HIGH 0 "no" 1 "yes" ;
VAL_ 718 RESOLVER_CALIBRATION_FAILED 0 "no" 1 "yes" ;
VAL_ 718 SYSTEM_FAULT 0 "no" 1 "yes" ;
VAL_ 718 INTERLOCK_OPEN 0 "no" 1 "yes" ;
VAL_ 718 APPC_HAS_GATE_DRIVER_DISABLED 0 "no" 1 "yes" ;
VAL_ 718 MOTOR_STALL_ERROR 0 "no" 1 "yes" ;
VAL_ 718 AMBIENT_TEMPERATURE_WARNING 0 "no" 1 "yes" ;
VAL_ 718 AMBIENT_OVERTEMPERATURE 0 "no" 1 "yes" ;
VAL_ 718 AMBIENT_TEMPSENSOR_ERROR 0 "no" 1 "yes" ;
VAL_ 718 POWERMODULE_CLAMPING_TIMEOUT 0 "no" 1 "yes" ;
VAL_ 718 DCBUS_RIPPLE_TO_HIGH 0 "no" 1 "yes" ;
VAL_ 718 MOTOR_I2XT_WARNING 0 "no" 1 "yes" ;
VAL_ 718 MOTOR_I2XT_ERROR 0 "no" 1 "yes" ;
VAL_ 718 MOTOR_FIELDWEAKENING_ERROR 0 "no" 1 "yes" ;
VAL_ 718 INVALID_PARAMETER_COMBINATION 0 "no" 1 "yes" ;
VAL_ 718 PLUG_COVER_SENSOR_SIGNAL_LOW 0 "no" 1 "yes" ;
VAL_ 718 MOTOR_CONNECTION_TEST_FAILED 0 "no" 1 "yes" ;
VAL_ 718 POWERMODULE_IXT_WARNING 0 "no" 1 "yes" ;
VAL_ 718 ISOLATION_FAULT 0 "no" 1 "yes" ;
VAL_ 705 Inverter_B_Statusword_1 0 "NotReadyToSwitchOn" 64 "SwitchOnDisabled" 80 "SwitchOnDisabled" 96 "SwitchOnDisabled" 112 "SwitchOnDisabled" 33 "ReadyToSwitchOn" 49 "ReadyToSwitchOn" 35 "SwitchedOn" 51 "SwitchedOn" 39 "OperationEnabled" 55 "OperationEnabled" 7 "QuickStopActive" 23 "QuickStopActive" 15 "FaultReactionActive" 31 "FaultReactionActive" 47 "FaultReactionActive" 63 "FaultReactionActive" 8 "Fault" 24 "Fault" 40 "Fault" 56 "Fault" ;
VAL_ 705 EVENTBUFFER_NEW_EVENT 0 "no" 1 "yes" ;
VAL_ 705 EVENTBUFFER_OVERFLOW 0 "no" 1 "yes" ;
VAL_ 705 POWERMODULE_TRIPZONE_OVERCURRE 0 "no" 1 "yes" ;
VAL_ 705 POWERMODULE_CURRENT_OFFSET_INI 0 "no" 1 "yes" ;
VAL_ 705 POWERMODULE_TEMPSENSOR_ERROR 0 "no" 1 "yes" ;
VAL_ 705 POWERMODULE_TEMPERATURE_WARNIN 0 "no" 1 "yes" ;
VAL_ 705 POWERMODULE_OVERTEMPERATURE 0 "no" 1 "yes" ;
VAL_ 705 POWERMODULE_IXT_FAULT 0 "no" 1 "yes" ;
VAL_ 705 POWERMODULE_SW_OVERCURRENT 0 "no" 1 "yes" ;
VAL_ 705 POWERMODULE_PATTERNDATA_INCONS 0 "no" 1 "yes" ;
VAL_ 705 DCBUS_TRIPZONE_OVERVOLTAGE 0 "no" 1 "yes" ;
VAL_ 705 DCBUS_SW_OVERVOLTAGE 0 "no" 1 "yes" ;
VAL_ 705 DCBUS_SW_UNDERVOLTAGE 0 "no" 1 "yes" ;
VAL_ 705 NEIGHBOUR_FAULT 0 "no" 1 "yes" ;
VAL_ 705 MOTOR_TEMPSENSOR_ERROR 0 "no" 1 "yes" ;
VAL_ 705 MOTOR_TEMPERATURE_WARNING 0 "no" 1 "yes" ;
VAL_ 705 MOTOR_OVERTEMPERATURE 0 "no" 1 "yes" ;
VAL_ 705 MOTOR_STATOR_FREQ_TO_HIGH 0 "no" 1 "yes" ;
VAL_ 705 SUPPLYVOLTAGE_ERROR 0 "no" 1 "yes" ;
VAL_ 705 RPDO_TIMEOUT 0 "no" 1 "yes" ;
VAL_ 705 NMT_NOT_OPERATIONAL 0 "no" 1 "yes" ;
VAL_ 705 TASKOVERRUN 0 "no" 1 "yes" ;
VAL_ 705 NETSYNC_ERROR 0 "no" 1 "yes" ;
VAL_ 705 POSDEVICE_SIGNAL_TO_LOW 0 "no" 1 "yes" ;
VAL_ 705 POSDEVICE_SIGNAL_TO_HIGH 0 "no" 1 "yes" ;
VAL_ 705 RESOLVER_CALIBRATION_FAILED 0 "no" 1 "yes" ;
VAL_ 705 SYSTEM_FAULT 0 "no" 1 "yes" ;
VAL_ 705 INTERLOCK_OPEN 0 "no" 1 "yes" ;
VAL_ 705 APPC_HAS_GATE_DRIVER_DISABLED 0 "no" 1 "yes" ;
VAL_ 705 MOTOR_STALL_ERROR 0 "no" 1 "yes" ;
VAL_ 705 AMBIENT_TEMPERATURE_WARNING 0 "no" 1 "yes" ;
VAL_ 705 AMBIENT_OVERTEMPERATURE 0 "no" 1 "yes" ;
VAL_ 705 AMBIENT_TEMPSENSOR_ERROR 0 "no" 1 "yes" ;
VAL_ 705 POWERMODULE_CLAMPING_TIMEOUT 0 "no" 1 "yes" ;
VAL_ 705 DCBUS_RIPPLE_TO_HIGH 0 "no" 1 "yes" ;
VAL_ 705 MOTOR_I2XT_WARNING 0 "no" 1 "yes" ;
VAL_ 705 MOTOR_I2XT_ERROR 0 "no" 1 "yes" ;
VAL_ 705 MOTOR_FIELDWEAKENING_ERROR 0 "no" 1 "yes" ;
VAL_ 705 INVALID_PARAMETER_COMBINATION 0 "no" 1 "yes" ;
VAL_ 705 PLUG_COVER_SENSOR_SIGNAL_LOW 0 "no" 1 "yes" ;
VAL_ 705 MOTOR_CONNECTION_TEST_FAILED 0 "no" 1 "yes" ;
VAL_ 705 POWERMODULE_IXT_WARNING 0 "no" 1 "yes" ;
VAL_ 705 ISOLATION_FAULT 0 "no" 1 "yes" ;
VAL_ 706 Inverter_B_Statusword_2 0 "NotReadyToSwitchOn" 64 "SwitchOnDisabled" 80 "SwitchOnDisabled" 96 "SwitchOnDisabled" 112 "SwitchOnDisabled" 33 "ReadyToSwitchOn" 49 "ReadyToSwitchOn" 35 "SwitchedOn" 51 "SwitchedOn" 39 "OperationEnabled" 55 "OperationEnabled" 7 "QuickStopActive" 23 "QuickStopActive" 15 "FaultReactionActive" 31 "FaultReactionActive" 47 "FaultReactionActive" 63 "FaultReactionActive" 8 "Fault" 24 "Fault" 40 "Fault" 56 "Fault" ;
VAL_ 706 EVENTBUFFER_NEW_EVENT 0 "no" 1 "yes" ;
VAL_ 706 EVENTBUFFER_OVERFLOW 0 "no" 1 "yes" ;
VAL_ 706 POWERMODULE_TRIPZONE_OVERCURRE 0 "no" 1 "yes" ;
VAL_ 706 POWERMODULE_CURRENT_OFFSET_INI 0 "no" 1 "yes" ;
VAL_ 706 POWERMODULE_TEMPSENSOR_ERROR 0 "no" 1 "yes" ;
VAL_ 706 POWERMODULE_TEMPERATURE_WARNIN 0 "no" 1 "yes" ;
VAL_ 706 POWERMODULE_OVERTEMPERATURE 0 "no" 1 "yes" ;
VAL_ 706 POWERMODULE_IXT_FAULT 0 "no" 1 "yes" ;
VAL_ 706 POWERMODULE_SW_OVERCURRENT 0 "no" 1 "yes" ;
VAL_ 706 POWERMODULE_PATTERNDATA_INCONS 0 "no" 1 "yes" ;
VAL_ 706 DCBUS_TRIPZONE_OVERVOLTAGE 0 "no" 1 "yes" ;
VAL_ 706 DCBUS_SW_OVERVOLTAGE 0 "no" 1 "yes" ;
VAL_ 706 DCBUS_SW_UNDERVOLTAGE 0 "no" 1 "yes" ;
VAL_ 706 NEIGHBOUR_FAULT 0 "no" 1 "yes" ;
VAL_ 706 MOTOR_TEMPSENSOR_ERROR 0 "no" 1 "yes" ;
VAL_ 706 MOTOR_TEMPERATURE_WARNING 0 "no" 1 "yes" ;
VAL_ 706 MOTOR_OVERTEMPERATURE 0 "no" 1 "yes" ;
VAL_ 706 MOTOR_STATOR_FREQ_TO_HIGH 0 "no" 1 "yes" ;
VAL_ 706 SUPPLYVOLTAGE_ERROR 0 "no" 1 "yes" ;
VAL_ 706 RPDO_TIMEOUT 0 "no" 1 "yes" ;
VAL_ 706 NMT_NOT_OPERATIONAL 0 "no" 1 "yes" ;
VAL_ 706 TASKOVERRUN 0 "no" 1 "yes" ;
VAL_ 706 NETSYNC_ERROR 0 "no" 1 "yes" ;
VAL_ 706 POSDEVICE_SIGNAL_TO_LOW 0 "no" 1 "yes" ;
VAL_ 706 POSDEVICE_SIGNAL_TO_HIGH 0 "no" 1 "yes" ;
VAL_ 706 RESOLVER_CALIBRATION_FAILED 0 "no" 1 "yes" ;
VAL_ 706 SYSTEM_FAULT 0 "no" 1 "yes" ;
VAL_ 706 INTERLOCK_OPEN 0 "no" 1 "yes" ;
VAL_ 706 APPC_HAS_GATE_DRIVER_DISABLED 0 "no" 1 "yes" ;
VAL_ 706 MOTOR_STALL_ERROR 0 "no" 1 "yes" ;
VAL_ 706 AMBIENT_TEMPERATURE_WARNING 0 "no" 1 "yes" ;
VAL_ 706 AMBIENT_OVERTEMPERATURE 0 "no" 1 "yes" ;
VAL_ 706 AMBIENT_TEMPSENSOR_ERROR 0 "no" 1 "yes" ;
VAL_ 706 POWERMODULE_CLAMPING_TIMEOUT 0 "no" 1 "yes" ;
VAL_ 706 DCBUS_RIPPLE_TO_HIGH 0 "no" 1 "yes" ;
VAL_ 706 MOTOR_I2XT_WARNING 0 "no" 1 "yes" ;
VAL_ 706 MOTOR_I2XT_ERROR 0 "no" 1 "yes" ;
VAL_ 706 MOTOR_FIELDWEAKENING_ERROR 0 "no" 1 "yes" ;
VAL_ 706 INVALID_PARAMETER_COMBINATION 0 "no" 1 "yes" ;
VAL_ 706 PLUG_COVER_SENSOR_SIGNAL_LOW 0 "no" 1 "yes" ;
VAL_ 706 MOTOR_CONNECTION_TEST_FAILED 0 "no" 1 "yes" ;
VAL_ 706 POWERMODULE_IXT_WARNING 0 "no" 1 "yes" ;
VAL_ 706 ISOLATION_FAULT 0 "no" 1 "yes" ;
VAL_ 707 Inverter_B_Statusword_3 0 "NotReadyToSwitchOn" 64 "SwitchOnDisabled" 80 "SwitchOnDisabled" 96 "SwitchOnDisabled" 112 "SwitchOnDisabled" 33 "ReadyToSwitchOn" 49 "ReadyToSwitchOn" 35 "SwitchedOn" 51 "SwitchedOn" 39 "OperationEnabled" 55 "OperationEnabled" 7 "QuickStopActive" 23 "QuickStopActive" 15 "FaultReactionActive" 31 "FaultReactionActive" 47 "FaultReactionActive" 63 "FaultReactionActive" 8 "Fault" 24 "Fault" 40 "Fault" 56 "Fault" ;
VAL_ 707 EVENTBUFFER_NEW_EVENT 0 "no" 1 "yes" ;
VAL_ 707 EVENTBUFFER_OVERFLOW 0 "no" 1 "yes" ;
VAL_ 707 POWERMODULE_TRIPZONE_OVERCURRE 0 "no" 1 "yes" ;
VAL_ 707 POWERMODULE_CURRENT_OFFSET_INI 0 "no" 1 "yes" ;
VAL_ 707 POWERMODULE_TEMPSENSOR_ERROR 0 "no" 1 "yes" ;
VAL_ 707 POWERMODULE_TEMPERATURE_WARNIN 0 "no" 1 "yes" ;
VAL_ 707 POWERMODULE_OVERTEMPERATURE 0 "no" 1 "yes" ;
VAL_ 707 POWERMODULE_IXT_FAULT 0 "no" 1 "yes" ;
VAL_ 707 POWERMODULE_SW_OVERCURRENT 0 "no" 1 "yes" ;
VAL_ 707 POWERMODULE_PATTERNDATA_INCONS 0 "no" 1 "yes" ;
VAL_ 707 DCBUS_TRIPZONE_OVERVOLTAGE 0 "no" 1 "yes" ;
VAL_ 707 DCBUS_SW_OVERVOLTAGE 0 "no" 1 "yes" ;
VAL_ 707 DCBUS_SW_UNDERVOLTAGE 0 "no" 1 "yes" ;
VAL_ 707 NEIGHBOUR_FAULT 0 "no" 1 "yes" ;
VAL_ 707 MOTOR_TEMPSENSOR_ERROR 0 "no" 1 "yes" ;
VAL_ 707 MOTOR_TEMPERATURE_WARNING 0 "no" 1 "yes" ;
VAL_ 707 MOTOR_OVERTEMPERATURE 0 "no" 1 "yes" ;
VAL_ 707 MOTOR_STATOR_FREQ_TO_HIGH 0 "no" 1 "yes" ;
VAL_ 707 SUPPLYVOLTAGE_ERROR 0 "no" 1 "yes" ;
VAL_ 707 RPDO_TIMEOUT 0 "no" 1 "yes" ;
VAL_ 707 NMT_NOT_OPERATIONAL 0 "no" 1 "yes" ;
VAL_ 707 TASKOVERRUN 0 "no" 1 "yes" ;
VAL_ 707 NETSYNC_ERROR 0 "no" 1 "yes" ;
VAL_ 707 POSDEVICE_SIGNAL_TO_LOW 0 "no" 1 "yes" ;
VAL_ 707 POSDEVICE_SIGNAL_TO_HIGH 0 "no" 1 "yes" ;
VAL_ 707 RESOLVER_CALIBRATION_FAILED 0 "no" 1 "yes" ;
VAL_ 707 SYSTEM_FAULT 0 "no" 1 "yes" ;
VAL_ 707 INTERLOCK_OPEN 0 "no" 1 "yes" ;
VAL_ 707 APPC_HAS_GATE_DRIVER_DISABLED 0 "no" 1 "yes" ;
VAL_ 707 MOTOR_STALL_ERROR 0 "no" 1 "yes" ;
VAL_ 707 AMBIENT_TEMPERATURE_WARNING 0 "no" 1 "yes" ;
VAL_ 707 AMBIENT_OVERTEMPERATURE 0 "no" 1 "yes" ;
VAL_ 707 AMBIENT_TEMPSENSOR_ERROR 0 "no" 1 "yes" ;
VAL_ 707 POWERMODULE_CLAMPING_TIMEOUT 0 "no" 1 "yes" ;
VAL_ 707 DCBUS_RIPPLE_TO_HIGH 0 "no" 1 "yes" ;
VAL_ 707 MOTOR_I2XT_WARNING 0 "no" 1 "yes" ;
VAL_ 707 MOTOR_I2XT_ERROR 0 "no" 1 "yes" ;
VAL_ 707 MOTOR_FIELDWEAKENING_ERROR 0 "no" 1 "yes" ;
VAL_ 707 INVALID_PARAMETER_COMBINATION 0 "no" 1 "yes" ;
VAL_ 707 PLUG_COVER_SENSOR_SIGNAL_LOW 0 "no" 1 "yes" ;
VAL_ 707 MOTOR_CONNECTION_TEST_FAILED 0 "no" 1 "yes" ;
VAL_ 707 POWERMODULE_IXT_WARNING 0 "no" 1 "yes" ;
VAL_ 707 ISOLATION_FAULT 0 "no" 1 "yes" ;
